VERSION ""

NS_ :

BS_:

BU_: BMU_ID_0 BMU_ID_1 BMU_ID_2 BMU_ID_3 BMU_ID_4 BMU_ID_5 BMU_ID_6 BMU_ID_7 BMU_ID_8 BMU_ID_9 BMU_ID_10 BMU_ID_11 BMU_ID_12 BMU_ID_13 BMU_ID_14 BMU_ID_15

BO_ 1280 wBMU_ID_0_Reserved: 8 BMU_ID_0
 SG_ RESERVED : 0|64@1+ (1,0) [0|0] ""  BMU_ID_0

BO_ 1281 wBMU_ID_1_Reserved: 8 BMU_ID_0
 SG_ RESERVED : 0|64@1+ (1,0) [0|0] ""  BMU_ID_1

BO_ 1282 wBMU_ID_2_Reserved: 8 BMU_ID_0
 SG_ RESERVED : 0|64@1+ (1,0) [0|0] ""  BMU_ID_2

BO_ 1283 wBMU_ID_3_Reserved: 8 BMU_ID_0
 SG_ RESERVED : 0|64@1+ (1,0) [0|0] ""  BMU_ID_3

BO_ 1284 wBMU_ID_4_Reserved: 8 BMU_ID_0
 SG_ RESERVED : 0|64@1+ (1,0) [0|0] ""  BMU_ID_4

BO_ 1285 wBMU_ID_5_Reserved: 8 BMU_ID_0
 SG_ RESERVED : 0|64@1+ (1,0) [0|0] ""  BMU_ID_5

BO_ 1286 wBMU_ID_6_Reserved: 8 BMU_ID_0
 SG_ RESERVED : 0|64@1+ (1,0) [0|0] ""  BMU_ID_6

BO_ 1287 wBMU_ID_7_Reserved: 8 BMU_ID_0
 SG_ RESERVED : 0|64@1+ (1,0) [0|0] ""  BMU_ID_7

BO_ 1288 wBMU_ID_8_Reserved: 8 BMU_ID_0
 SG_ RESERVED : 0|64@1+ (1,0) [0|0] ""  BMU_ID_8

BO_ 1289 wBMU_ID_9_Reserved: 8 BMU_ID_0
 SG_ RESERVED : 0|64@1+ (1,0) [0|0] ""  BMU_ID_9

BO_ 1290 wBMU_ID_10_Reserved: 8 BMU_ID_0
 SG_ RESERVED : 0|64@1+ (1,0) [0|0] ""  BMU_ID_10

BO_ 1291 wBMU_ID_11_Reserved: 8 BMU_ID_0
 SG_ RESERVED : 0|64@1+ (1,0) [0|0] ""  BMU_ID_11

BO_ 1292 wBMU_ID_12_Reserved: 8 BMU_ID_0
 SG_ RESERVED : 0|64@1+ (1,0) [0|0] ""  BMU_ID_12

BO_ 1293 wBMU_ID_13_Reserved: 8 BMU_ID_0
 SG_ RESERVED : 0|64@1+ (1,0) [0|0] ""  BMU_ID_13

BO_ 1294 wBMU_ID_14_Reserved: 8 BMU_ID_0
 SG_ RESERVED : 0|64@1+ (1,0) [0|0] ""  BMU_ID_14

BO_ 1295 wBMU_ID_15_Reserved: 8 BMU_ID_0
 SG_ RESERVED : 0|64@1+ (1,0) [0|0] ""  BMU_ID_15

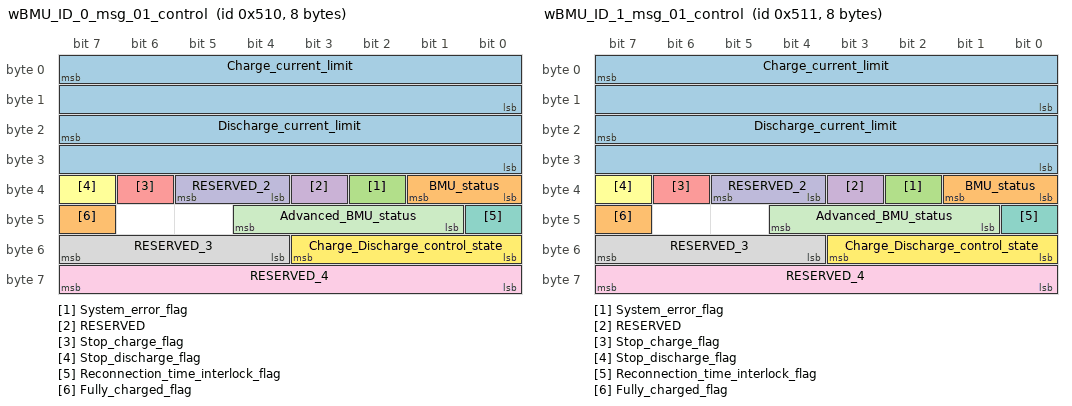
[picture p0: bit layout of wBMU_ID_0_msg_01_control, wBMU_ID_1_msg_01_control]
BO_ 1296 wBMU_ID_0_msg_01_control: 8 BMU_ID_0
 SG_ Discharge_current_limit : 23|16@0+ (0.1,0) [0|0] "A"  BMU_ID_0
 SG_ BMU_status : 33|2@0+ (1,0) [0|0] ""  BMU_ID_0
 SG_ System_error_flag : 34|1@0+ (1,0) [0|0] ""  BMU_ID_0
 SG_ RESERVED : 35|1@0+ (1,0) [0|0] ""  BMU_ID_0
 SG_ Stop_charge_flag : 38|1@0+ (1,0) [0|0] ""  BMU_ID_0
 SG_ Stop_discharge_flag : 39|1@0+ (1,0) [0|0] ""  BMU_ID_0
 SG_ Reconnection_time_interlock_flag : 40|1@0+ (1,0) [0|0] ""  BMU_ID_0
 SG_ RESERVED_3 : 55|4@0+ (1,0) [0|0] ""  BMU_ID_0
 SG_ RESERVED_4 : 63|8@0+ (1,0) [0|0] ""  BMU_ID_0
 SG_ RESERVED_2 : 37|2@0+ (1,0) [0|0] ""  BMU_ID_0
 SG_ Advanced_BMU_status : 44|4@0+ (1,0) [0|0] ""  BMU_ID_0
 SG_ Charge_Discharge_control_state : 51|4@0+ (1,0) [0|0] ""  BMU_ID_0
 SG_ Charge_current_limit : 7|16@0+ (0.1,0) [0|0] "A"  BMU_ID_0
 SG_ Fully_charged_flag : 47|1@0+ (1,0) [0|0] "" Vector__XXX

BO_ 1297 wBMU_ID_1_msg_01_control: 8 BMU_ID_1
 SG_ Discharge_current_limit : 23|16@0+ (0.1,0) [0|0] "A"  BMU_ID_0
 SG_ BMU_status : 33|2@0+ (1,0) [0|0] ""  BMU_ID_0
 SG_ System_error_flag : 34|1@0+ (1,0) [0|0] ""  BMU_ID_0
 SG_ RESERVED : 35|1@0+ (1,0) [0|0] ""  BMU_ID_0
 SG_ Stop_charge_flag : 38|1@0+ (1,0) [0|0] ""  BMU_ID_0
 SG_ Stop_discharge_flag : 39|1@0+ (1,0) [0|0] ""  BMU_ID_0
 SG_ Reconnection_time_interlock_flag : 40|1@0+ (1,0) [0|0] ""  BMU_ID_0
 SG_ RESERVED_3 : 55|4@0+ (1,0) [0|0] ""  BMU_ID_0
 SG_ RESERVED_4 : 63|8@0+ (1,0) [0|0] ""  BMU_ID_0
 SG_ RESERVED_2 : 37|2@0+ (1,0) [0|0] ""  BMU_ID_0
 SG_ Advanced_BMU_status : 44|4@0+ (1,0) [0|0] ""  BMU_ID_0
 SG_ Charge_Discharge_control_state : 51|4@0+ (1,0) [0|0] ""  BMU_ID_0
 SG_ Charge_current_limit : 7|16@0+ (0.1,0) [0|0] "A"  BMU_ID_0
 SG_ Fully_charged_flag : 47|1@0+ (1,0) [0|0] "" Vector__XXX

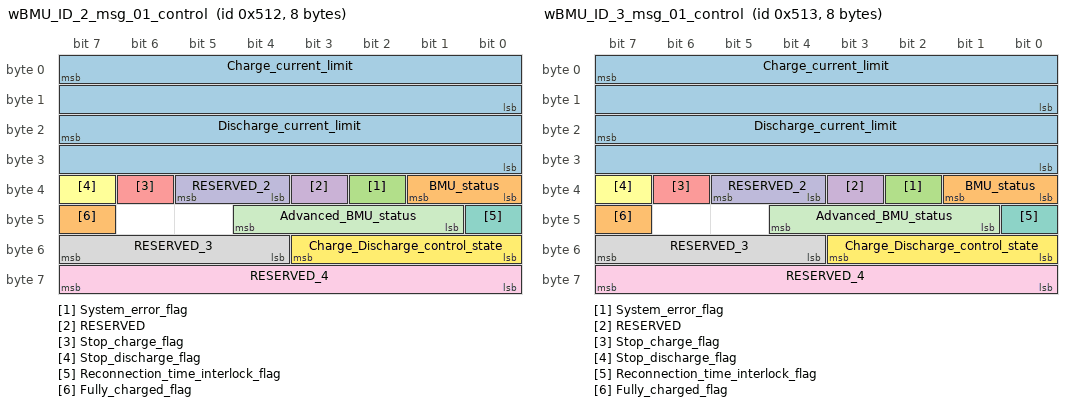
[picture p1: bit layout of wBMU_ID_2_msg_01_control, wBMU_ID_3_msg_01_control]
BO_ 1298 wBMU_ID_2_msg_01_control: 8 BMU_ID_2
 SG_ Discharge_current_limit : 23|16@0+ (0.1,0) [0|0] "A"  BMU_ID_0
 SG_ BMU_status : 33|2@0+ (1,0) [0|0] ""  BMU_ID_0
 SG_ System_error_flag : 34|1@0+ (1,0) [0|0] ""  BMU_ID_0
 SG_ RESERVED : 35|1@0+ (1,0) [0|0] ""  BMU_ID_0
 SG_ Stop_charge_flag : 38|1@0+ (1,0) [0|0] ""  BMU_ID_0
 SG_ Stop_discharge_flag : 39|1@0+ (1,0) [0|0] ""  BMU_ID_0
 SG_ Reconnection_time_interlock_flag : 40|1@0+ (1,0) [0|0] ""  BMU_ID_0
 SG_ RESERVED_3 : 55|4@0+ (1,0) [0|0] ""  BMU_ID_0
 SG_ RESERVED_4 : 63|8@0+ (1,0) [0|0] ""  BMU_ID_0
 SG_ RESERVED_2 : 37|2@0+ (1,0) [0|0] ""  BMU_ID_0
 SG_ Advanced_BMU_status : 44|4@0+ (1,0) [0|0] ""  BMU_ID_0
 SG_ Charge_Discharge_control_state : 51|4@0+ (1,0) [0|0] ""  BMU_ID_0
 SG_ Charge_current_limit : 7|16@0+ (0.1,0) [0|0] "A"  BMU_ID_0
 SG_ Fully_charged_flag : 47|1@0+ (1,0) [0|0] "" Vector__XXX

BO_ 1299 wBMU_ID_3_msg_01_control: 8 BMU_ID_3
 SG_ Discharge_current_limit : 23|16@0+ (0.1,0) [0|0] "A"  BMU_ID_0
 SG_ BMU_status : 33|2@0+ (1,0) [0|0] ""  BMU_ID_0
 SG_ System_error_flag : 34|1@0+ (1,0) [0|0] ""  BMU_ID_0
 SG_ RESERVED : 35|1@0+ (1,0) [0|0] ""  BMU_ID_0
 SG_ Stop_charge_flag : 38|1@0+ (1,0) [0|0] ""  BMU_ID_0
 SG_ Stop_discharge_flag : 39|1@0+ (1,0) [0|0] ""  BMU_ID_0
 SG_ Reconnection_time_interlock_flag : 40|1@0+ (1,0) [0|0] ""  BMU_ID_0
 SG_ RESERVED_3 : 55|4@0+ (1,0) [0|0] ""  BMU_ID_0
 SG_ RESERVED_4 : 63|8@0+ (1,0) [0|0] ""  BMU_ID_0
 SG_ RESERVED_2 : 37|2@0+ (1,0) [0|0] ""  BMU_ID_0
 SG_ Advanced_BMU_status : 44|4@0+ (1,0) [0|0] ""  BMU_ID_0
 SG_ Charge_Discharge_control_state : 51|4@0+ (1,0) [0|0] ""  BMU_ID_0
 SG_ Charge_current_limit : 7|16@0+ (0.1,0) [0|0] "A"  BMU_ID_0
 SG_ Fully_charged_flag : 47|1@0+ (1,0) [0|0] "" Vector__XXX

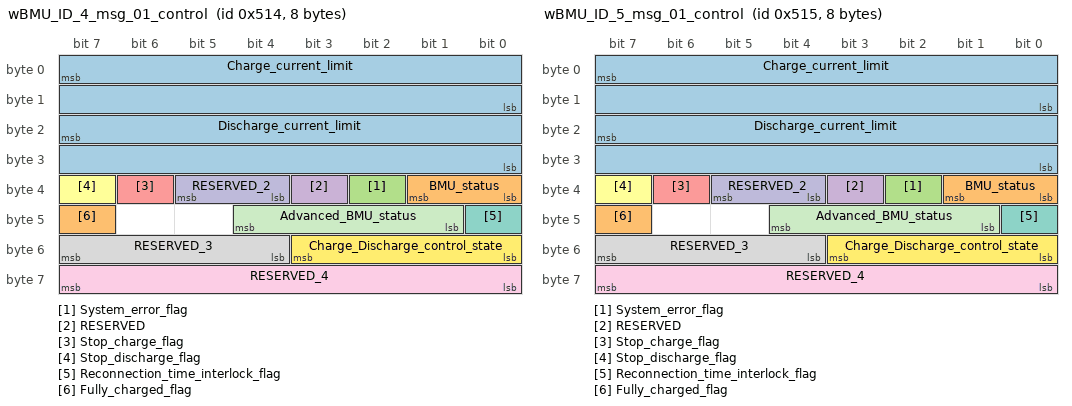
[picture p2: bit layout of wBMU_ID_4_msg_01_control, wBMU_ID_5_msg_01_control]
BO_ 1300 wBMU_ID_4_msg_01_control: 8 BMU_ID_4
 SG_ Discharge_current_limit : 23|16@0+ (0.1,0) [0|0] "A"  BMU_ID_0
 SG_ BMU_status : 33|2@0+ (1,0) [0|0] ""  BMU_ID_0
 SG_ System_error_flag : 34|1@0+ (1,0) [0|0] ""  BMU_ID_0
 SG_ RESERVED : 35|1@0+ (1,0) [0|0] ""  BMU_ID_0
 SG_ Stop_charge_flag : 38|1@0+ (1,0) [0|0] ""  BMU_ID_0
 SG_ Stop_discharge_flag : 39|1@0+ (1,0) [0|0] ""  BMU_ID_0
 SG_ Reconnection_time_interlock_flag : 40|1@0+ (1,0) [0|0] ""  BMU_ID_0
 SG_ RESERVED_3 : 55|4@0+ (1,0) [0|0] ""  BMU_ID_0
 SG_ RESERVED_4 : 63|8@0+ (1,0) [0|0] ""  BMU_ID_0
 SG_ RESERVED_2 : 37|2@0+ (1,0) [0|0] ""  BMU_ID_0
 SG_ Advanced_BMU_status : 44|4@0+ (1,0) [0|0] ""  BMU_ID_0
 SG_ Charge_Discharge_control_state : 51|4@0+ (1,0) [0|0] ""  BMU_ID_0
 SG_ Charge_current_limit : 7|16@0+ (0.1,0) [0|0] "A"  BMU_ID_0
 SG_ Fully_charged_flag : 47|1@0+ (1,0) [0|0] "" Vector__XXX

BO_ 1301 wBMU_ID_5_msg_01_control: 8 BMU_ID_5
 SG_ Discharge_current_limit : 23|16@0+ (0.1,0) [0|0] "A"  BMU_ID_0
 SG_ BMU_status : 33|2@0+ (1,0) [0|0] ""  BMU_ID_0
 SG_ System_error_flag : 34|1@0+ (1,0) [0|0] ""  BMU_ID_0
 SG_ RESERVED : 35|1@0+ (1,0) [0|0] ""  BMU_ID_0
 SG_ Stop_charge_flag : 38|1@0+ (1,0) [0|0] ""  BMU_ID_0
 SG_ Stop_discharge_flag : 39|1@0+ (1,0) [0|0] ""  BMU_ID_0
 SG_ Reconnection_time_interlock_flag : 40|1@0+ (1,0) [0|0] ""  BMU_ID_0
 SG_ RESERVED_3 : 55|4@0+ (1,0) [0|0] ""  BMU_ID_0
 SG_ RESERVED_4 : 63|8@0+ (1,0) [0|0] ""  BMU_ID_0
 SG_ RESERVED_2 : 37|2@0+ (1,0) [0|0] ""  BMU_ID_0
 SG_ Advanced_BMU_status : 44|4@0+ (1,0) [0|0] ""  BMU_ID_0
 SG_ Charge_Discharge_control_state : 51|4@0+ (1,0) [0|0] ""  BMU_ID_0
 SG_ Charge_current_limit : 7|16@0+ (0.1,0) [0|0] "A"  BMU_ID_0
 SG_ Fully_charged_flag : 47|1@0+ (1,0) [0|0] "" Vector__XXX

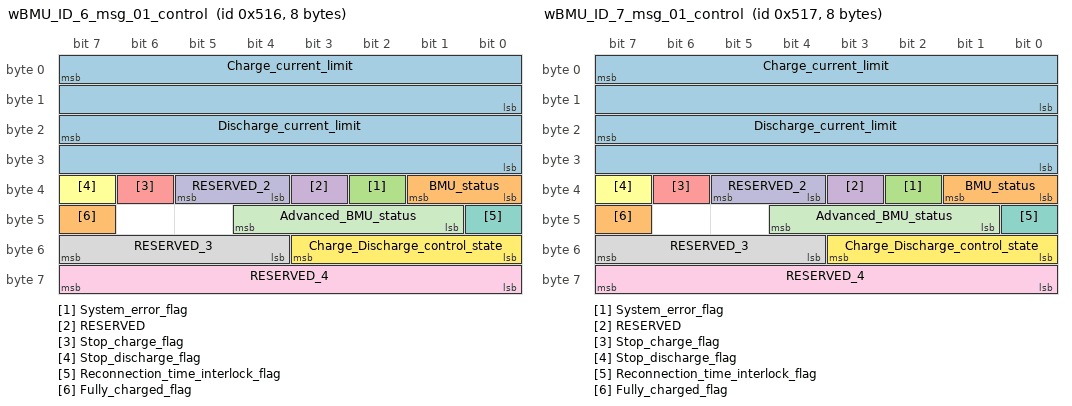
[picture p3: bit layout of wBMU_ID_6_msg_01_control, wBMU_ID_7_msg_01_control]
BO_ 1302 wBMU_ID_6_msg_01_control: 8 BMU_ID_6
 SG_ Discharge_current_limit : 23|16@0+ (0.1,0) [0|0] "A"  BMU_ID_0
 SG_ BMU_status : 33|2@0+ (1,0) [0|0] ""  BMU_ID_0
 SG_ System_error_flag : 34|1@0+ (1,0) [0|0] ""  BMU_ID_0
 SG_ RESERVED : 35|1@0+ (1,0) [0|0] ""  BMU_ID_0
 SG_ Stop_charge_flag : 38|1@0+ (1,0) [0|0] ""  BMU_ID_0
 SG_ Stop_discharge_flag : 39|1@0+ (1,0) [0|0] ""  BMU_ID_0
 SG_ Reconnection_time_interlock_flag : 40|1@0+ (1,0) [0|0] ""  BMU_ID_0
 SG_ RESERVED_3 : 55|4@0+ (1,0) [0|0] ""  BMU_ID_0
 SG_ RESERVED_4 : 63|8@0+ (1,0) [0|0] ""  BMU_ID_0
 SG_ RESERVED_2 : 37|2@0+ (1,0) [0|0] ""  BMU_ID_0
 SG_ Advanced_BMU_status : 44|4@0+ (1,0) [0|0] ""  BMU_ID_0
 SG_ Charge_Discharge_control_state : 51|4@0+ (1,0) [0|0] ""  BMU_ID_0
 SG_ Charge_current_limit : 7|16@0+ (0.1,0) [0|0] "A"  BMU_ID_0
 SG_ Fully_charged_flag : 47|1@0+ (1,0) [0|0] "" Vector__XXX

BO_ 1303 wBMU_ID_7_msg_01_control: 8 BMU_ID_7
 SG_ Discharge_current_limit : 23|16@0+ (0.1,0) [0|0] "A"  BMU_ID_0
 SG_ BMU_status : 33|2@0+ (1,0) [0|0] ""  BMU_ID_0
 SG_ System_error_flag : 34|1@0+ (1,0) [0|0] ""  BMU_ID_0
 SG_ RESERVED : 35|1@0+ (1,0) [0|0] ""  BMU_ID_0
 SG_ Stop_charge_flag : 38|1@0+ (1,0) [0|0] ""  BMU_ID_0
 SG_ Stop_discharge_flag : 39|1@0+ (1,0) [0|0] ""  BMU_ID_0
 SG_ Reconnection_time_interlock_flag : 40|1@0+ (1,0) [0|0] ""  BMU_ID_0
 SG_ RESERVED_3 : 55|4@0+ (1,0) [0|0] ""  BMU_ID_0
 SG_ RESERVED_4 : 63|8@0+ (1,0) [0|0] ""  BMU_ID_0
 SG_ RESERVED_2 : 37|2@0+ (1,0) [0|0] ""  BMU_ID_0
 SG_ Advanced_BMU_status : 44|4@0+ (1,0) [0|0] ""  BMU_ID_0
 SG_ Charge_Discharge_control_state : 51|4@0+ (1,0) [0|0] ""  BMU_ID_0
 SG_ Charge_current_limit : 7|16@0+ (0.1,0) [0|0] "A"  BMU_ID_0
 SG_ Fully_charged_flag : 47|1@0+ (1,0) [0|0] "" Vector__XXX

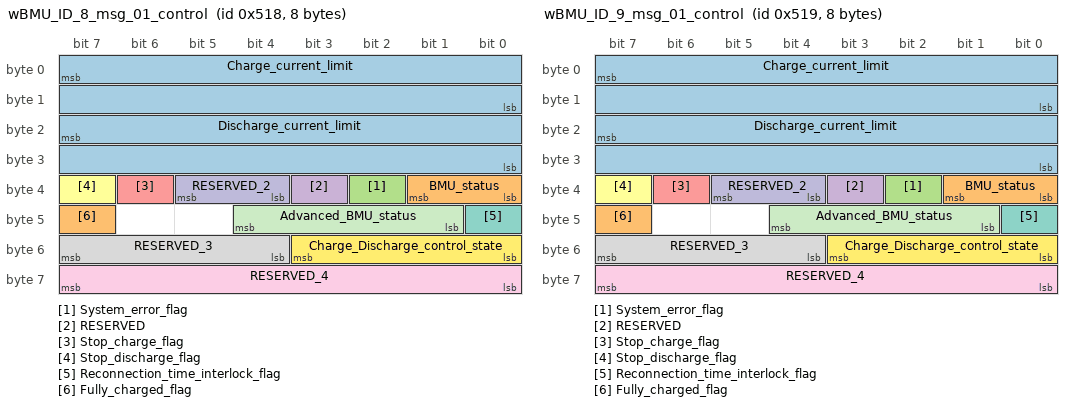
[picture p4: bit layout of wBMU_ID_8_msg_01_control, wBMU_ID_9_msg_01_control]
BO_ 1304 wBMU_ID_8_msg_01_control: 8 BMU_ID_8
 SG_ Discharge_current_limit : 23|16@0+ (0.1,0) [0|0] "A"  BMU_ID_0
 SG_ BMU_status : 33|2@0+ (1,0) [0|0] ""  BMU_ID_0
 SG_ System_error_flag : 34|1@0+ (1,0) [0|0] ""  BMU_ID_0
 SG_ RESERVED : 35|1@0+ (1,0) [0|0] ""  BMU_ID_0
 SG_ Stop_charge_flag : 38|1@0+ (1,0) [0|0] ""  BMU_ID_0
 SG_ Stop_discharge_flag : 39|1@0+ (1,0) [0|0] ""  BMU_ID_0
 SG_ Reconnection_time_interlock_flag : 40|1@0+ (1,0) [0|0] ""  BMU_ID_0
 SG_ RESERVED_3 : 55|4@0+ (1,0) [0|0] ""  BMU_ID_0
 SG_ RESERVED_4 : 63|8@0+ (1,0) [0|0] ""  BMU_ID_0
 SG_ RESERVED_2 : 37|2@0+ (1,0) [0|0] ""  BMU_ID_0
 SG_ Advanced_BMU_status : 44|4@0+ (1,0) [0|0] ""  BMU_ID_0
 SG_ Charge_Discharge_control_state : 51|4@0+ (1,0) [0|0] ""  BMU_ID_0
 SG_ Charge_current_limit : 7|16@0+ (0.1,0) [0|0] "A"  BMU_ID_0
 SG_ Fully_charged_flag : 47|1@0+ (1,0) [0|0] "" Vector__XXX

BO_ 1305 wBMU_ID_9_msg_01_control: 8 BMU_ID_9
 SG_ Discharge_current_limit : 23|16@0+ (0.1,0) [0|0] "A"  BMU_ID_0
 SG_ BMU_status : 33|2@0+ (1,0) [0|0] ""  BMU_ID_0
 SG_ System_error_flag : 34|1@0+ (1,0) [0|0] ""  BMU_ID_0
 SG_ RESERVED : 35|1@0+ (1,0) [0|0] ""  BMU_ID_0
 SG_ Stop_charge_flag : 38|1@0+ (1,0) [0|0] ""  BMU_ID_0
 SG_ Stop_discharge_flag : 39|1@0+ (1,0) [0|0] ""  BMU_ID_0
 SG_ Reconnection_time_interlock_flag : 40|1@0+ (1,0) [0|0] ""  BMU_ID_0
 SG_ RESERVED_3 : 55|4@0+ (1,0) [0|0] ""  BMU_ID_0
 SG_ RESERVED_4 : 63|8@0+ (1,0) [0|0] ""  BMU_ID_0
 SG_ RESERVED_2 : 37|2@0+ (1,0) [0|0] ""  BMU_ID_0
 SG_ Advanced_BMU_status : 44|4@0+ (1,0) [0|0] ""  BMU_ID_0
 SG_ Charge_Discharge_control_state : 51|4@0+ (1,0) [0|0] ""  BMU_ID_0
 SG_ Charge_current_limit : 7|16@0+ (0.1,0) [0|0] "A"  BMU_ID_0
 SG_ Fully_charged_flag : 47|1@0+ (1,0) [0|0] "" Vector__XXX

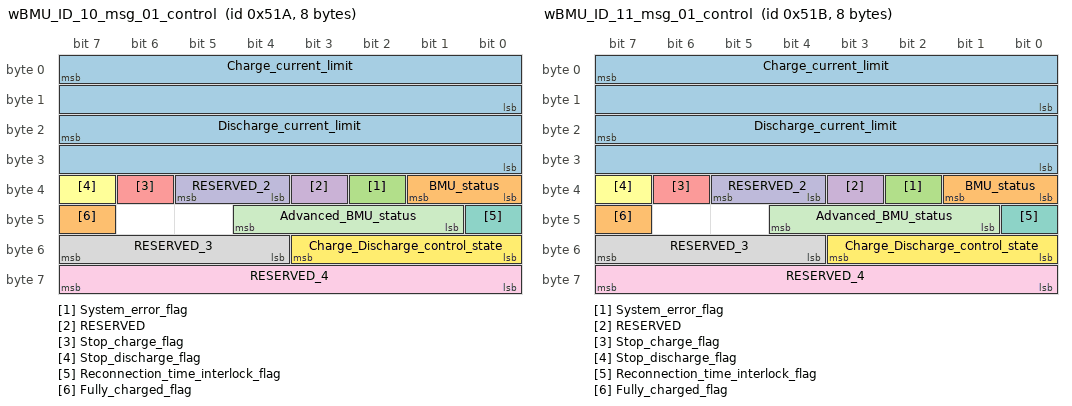
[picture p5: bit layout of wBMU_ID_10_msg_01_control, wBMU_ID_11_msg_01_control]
BO_ 1306 wBMU_ID_10_msg_01_control: 8 BMU_ID_10
 SG_ Discharge_current_limit : 23|16@0+ (0.1,0) [0|0] "A"  BMU_ID_0
 SG_ BMU_status : 33|2@0+ (1,0) [0|0] ""  BMU_ID_0
 SG_ System_error_flag : 34|1@0+ (1,0) [0|0] ""  BMU_ID_0
 SG_ RESERVED : 35|1@0+ (1,0) [0|0] ""  BMU_ID_0
 SG_ Stop_charge_flag : 38|1@0+ (1,0) [0|0] ""  BMU_ID_0
 SG_ Stop_discharge_flag : 39|1@0+ (1,0) [0|0] ""  BMU_ID_0
 SG_ Reconnection_time_interlock_flag : 40|1@0+ (1,0) [0|0] ""  BMU_ID_0
 SG_ RESERVED_3 : 55|4@0+ (1,0) [0|0] ""  BMU_ID_0
 SG_ RESERVED_4 : 63|8@0+ (1,0) [0|0] ""  BMU_ID_0
 SG_ RESERVED_2 : 37|2@0+ (1,0) [0|0] ""  BMU_ID_0
 SG_ Advanced_BMU_status : 44|4@0+ (1,0) [0|0] ""  BMU_ID_0
 SG_ Charge_Discharge_control_state : 51|4@0+ (1,0) [0|0] ""  BMU_ID_0
 SG_ Charge_current_limit : 7|16@0+ (0.1,0) [0|0] "A"  BMU_ID_0
 SG_ Fully_charged_flag : 47|1@0+ (1,0) [0|0] "" Vector__XXX

BO_ 1307 wBMU_ID_11_msg_01_control: 8 BMU_ID_11
 SG_ Discharge_current_limit : 23|16@0+ (0.1,0) [0|0] "A"  BMU_ID_0
 SG_ BMU_status : 33|2@0+ (1,0) [0|0] ""  BMU_ID_0
 SG_ System_error_flag : 34|1@0+ (1,0) [0|0] ""  BMU_ID_0
 SG_ RESERVED : 35|1@0+ (1,0) [0|0] ""  BMU_ID_0
 SG_ Stop_charge_flag : 38|1@0+ (1,0) [0|0] ""  BMU_ID_0
 SG_ Stop_discharge_flag : 39|1@0+ (1,0) [0|0] ""  BMU_ID_0
 SG_ Reconnection_time_interlock_flag : 40|1@0+ (1,0) [0|0] ""  BMU_ID_0
 SG_ RESERVED_3 : 55|4@0+ (1,0) [0|0] ""  BMU_ID_0
 SG_ RESERVED_4 : 63|8@0+ (1,0) [0|0] ""  BMU_ID_0
 SG_ RESERVED_2 : 37|2@0+ (1,0) [0|0] ""  BMU_ID_0
 SG_ Advanced_BMU_status : 44|4@0+ (1,0) [0|0] ""  BMU_ID_0
 SG_ Charge_Discharge_control_state : 51|4@0+ (1,0) [0|0] ""  BMU_ID_0
 SG_ Charge_current_limit : 7|16@0+ (0.1,0) [0|0] "A"  BMU_ID_0
 SG_ Fully_charged_flag : 47|1@0+ (1,0) [0|0] "" Vector__XXX

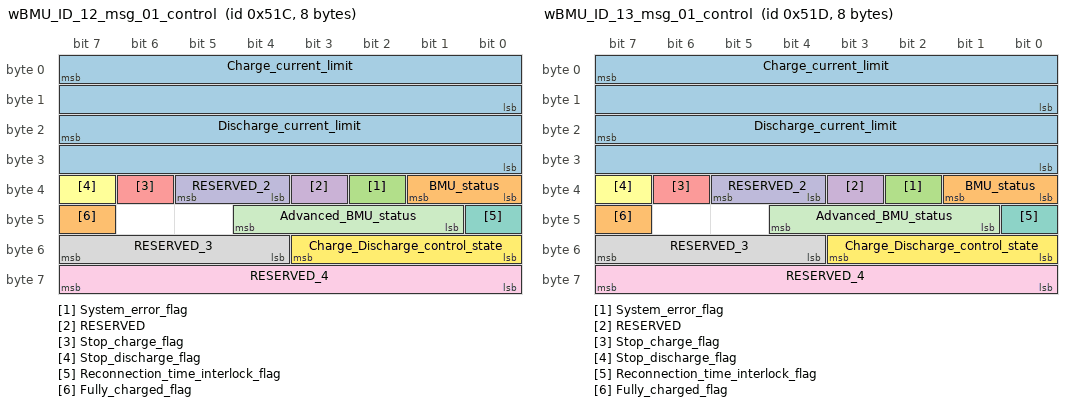
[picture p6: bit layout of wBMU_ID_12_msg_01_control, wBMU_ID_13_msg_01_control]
BO_ 1308 wBMU_ID_12_msg_01_control: 8 BMU_ID_12
 SG_ Discharge_current_limit : 23|16@0+ (0.1,0) [0|0] "A"  BMU_ID_0
 SG_ BMU_status : 33|2@0+ (1,0) [0|0] ""  BMU_ID_0
 SG_ System_error_flag : 34|1@0+ (1,0) [0|0] ""  BMU_ID_0
 SG_ RESERVED : 35|1@0+ (1,0) [0|0] ""  BMU_ID_0
 SG_ Stop_charge_flag : 38|1@0+ (1,0) [0|0] ""  BMU_ID_0
 SG_ Stop_discharge_flag : 39|1@0+ (1,0) [0|0] ""  BMU_ID_0
 SG_ Reconnection_time_interlock_flag : 40|1@0+ (1,0) [0|0] ""  BMU_ID_0
 SG_ RESERVED_3 : 55|4@0+ (1,0) [0|0] ""  BMU_ID_0
 SG_ RESERVED_4 : 63|8@0+ (1,0) [0|0] ""  BMU_ID_0
 SG_ RESERVED_2 : 37|2@0+ (1,0) [0|0] ""  BMU_ID_0
 SG_ Advanced_BMU_status : 44|4@0+ (1,0) [0|0] ""  BMU_ID_0
 SG_ Charge_Discharge_control_state : 51|4@0+ (1,0) [0|0] ""  BMU_ID_0
 SG_ Charge_current_limit : 7|16@0+ (0.1,0) [0|0] "A"  BMU_ID_0
 SG_ Fully_charged_flag : 47|1@0+ (1,0) [0|0] "" Vector__XXX

BO_ 1309 wBMU_ID_13_msg_01_control: 8 BMU_ID_13
 SG_ Discharge_current_limit : 23|16@0+ (0.1,0) [0|0] "A"  BMU_ID_0
 SG_ BMU_status : 33|2@0+ (1,0) [0|0] ""  BMU_ID_0
 SG_ System_error_flag : 34|1@0+ (1,0) [0|0] ""  BMU_ID_0
 SG_ RESERVED : 35|1@0+ (1,0) [0|0] ""  BMU_ID_0
 SG_ Stop_charge_flag : 38|1@0+ (1,0) [0|0] ""  BMU_ID_0
 SG_ Stop_discharge_flag : 39|1@0+ (1,0) [0|0] ""  BMU_ID_0
 SG_ Reconnection_time_interlock_flag : 40|1@0+ (1,0) [0|0] ""  BMU_ID_0
 SG_ RESERVED_3 : 55|4@0+ (1,0) [0|0] ""  BMU_ID_0
 SG_ RESERVED_4 : 63|8@0+ (1,0) [0|0] ""  BMU_ID_0
 SG_ RESERVED_2 : 37|2@0+ (1,0) [0|0] ""  BMU_ID_0
 SG_ Advanced_BMU_status : 44|4@0+ (1,0) [0|0] ""  BMU_ID_0
 SG_ Charge_Discharge_control_state : 51|4@0+ (1,0) [0|0] ""  BMU_ID_0
 SG_ Charge_current_limit : 7|16@0+ (0.1,0) [0|0] "A"  BMU_ID_0
 SG_ Fully_charged_flag : 47|1@0+ (1,0) [0|0] "" Vector__XXX

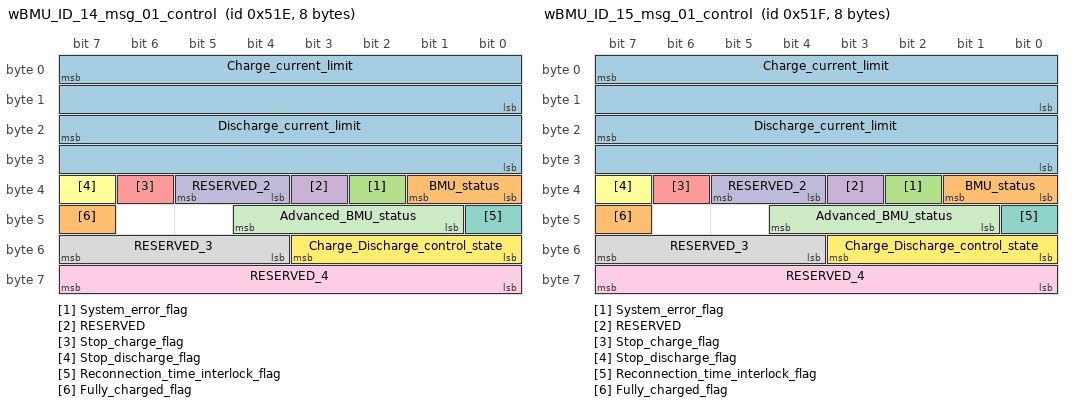
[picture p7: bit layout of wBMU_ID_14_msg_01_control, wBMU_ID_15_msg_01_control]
BO_ 1310 wBMU_ID_14_msg_01_control: 8 BMU_ID_14
 SG_ Discharge_current_limit : 23|16@0+ (0.1,0) [0|0] "A"  BMU_ID_0
 SG_ BMU_status : 33|2@0+ (1,0) [0|0] ""  BMU_ID_0
 SG_ System_error_flag : 34|1@0+ (1,0) [0|0] ""  BMU_ID_0
 SG_ RESERVED : 35|1@0+ (1,0) [0|0] ""  BMU_ID_0
 SG_ Stop_charge_flag : 38|1@0+ (1,0) [0|0] ""  BMU_ID_0
 SG_ Stop_discharge_flag : 39|1@0+ (1,0) [0|0] ""  BMU_ID_0
 SG_ Reconnection_time_interlock_flag : 40|1@0+ (1,0) [0|0] ""  BMU_ID_0
 SG_ RESERVED_3 : 55|4@0+ (1,0) [0|0] ""  BMU_ID_0
 SG_ RESERVED_4 : 63|8@0+ (1,0) [0|0] ""  BMU_ID_0
 SG_ RESERVED_2 : 37|2@0+ (1,0) [0|0] ""  BMU_ID_0
 SG_ Advanced_BMU_status : 44|4@0+ (1,0) [0|0] ""  BMU_ID_0
 SG_ Charge_Discharge_control_state : 51|4@0+ (1,0) [0|0] ""  BMU_ID_0
 SG_ Charge_current_limit : 7|16@0+ (0.1,0) [0|0] "A"  BMU_ID_0
 SG_ Fully_charged_flag : 47|1@0+ (1,0) [0|0] "" Vector__XXX

BO_ 1311 wBMU_ID_15_msg_01_control: 8 BMU_ID_15
 SG_ Discharge_current_limit : 23|16@0+ (0.1,0) [0|0] "A"  BMU_ID_0
 SG_ BMU_status : 33|2@0+ (1,0) [0|0] ""  BMU_ID_0
 SG_ System_error_flag : 34|1@0+ (1,0) [0|0] ""  BMU_ID_0
 SG_ RESERVED : 35|1@0+ (1,0) [0|0] ""  BMU_ID_0
 SG_ Stop_charge_flag : 38|1@0+ (1,0) [0|0] ""  BMU_ID_0
 SG_ Stop_discharge_flag : 39|1@0+ (1,0) [0|0] ""  BMU_ID_0
 SG_ Reconnection_time_interlock_flag : 40|1@0+ (1,0) [0|0] ""  BMU_ID_0
 SG_ RESERVED_3 : 55|4@0+ (1,0) [0|0] ""  BMU_ID_0
 SG_ RESERVED_4 : 63|8@0+ (1,0) [0|0] ""  BMU_ID_0
 SG_ RESERVED_2 : 37|2@0+ (1,0) [0|0] ""  BMU_ID_0
 SG_ Advanced_BMU_status : 44|4@0+ (1,0) [0|0] ""  BMU_ID_0
 SG_ Charge_Discharge_control_state : 51|4@0+ (1,0) [0|0] ""  BMU_ID_0
 SG_ Charge_current_limit : 7|16@0+ (0.1,0) [0|0] "A"  BMU_ID_0
 SG_ Fully_charged_flag : 47|1@0+ (1,0) [0|0] "" Vector__XXX

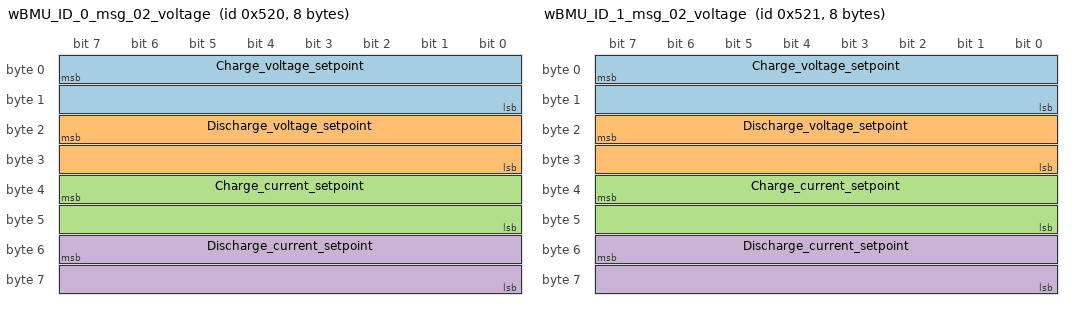
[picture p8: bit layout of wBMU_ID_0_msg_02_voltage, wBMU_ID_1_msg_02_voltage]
BO_ 1312 wBMU_ID_0_msg_02_voltage: 8 BMU_ID_0
 SG_ Charge_voltage_setpoint : 7|16@0+ (0.1,0) [0|0] "V"  BMU_ID_0
 SG_ Discharge_voltage_setpoint : 23|16@0+ (0.1,0) [0|0] "V"  BMU_ID_0
 SG_ Charge_current_setpoint : 39|16@0+ (0.1,0) [0|0] "A"  BMU_ID_0
 SG_ Discharge_current_setpoint : 55|16@0+ (0.1,0) [0|0] "A"  BMU_ID_0

BO_ 1313 wBMU_ID_1_msg_02_voltage: 8 BMU_ID_1
 SG_ Charge_voltage_setpoint : 7|16@0+ (0.1,0) [0|0] "V"  BMU_ID_0
 SG_ Discharge_voltage_setpoint : 23|16@0+ (0.1,0) [0|0] "V"  BMU_ID_0
 SG_ Charge_current_setpoint : 39|16@0+ (0.1,0) [0|0] "A"  BMU_ID_0
 SG_ Discharge_current_setpoint : 55|16@0+ (0.1,0) [0|0] "A"  BMU_ID_0

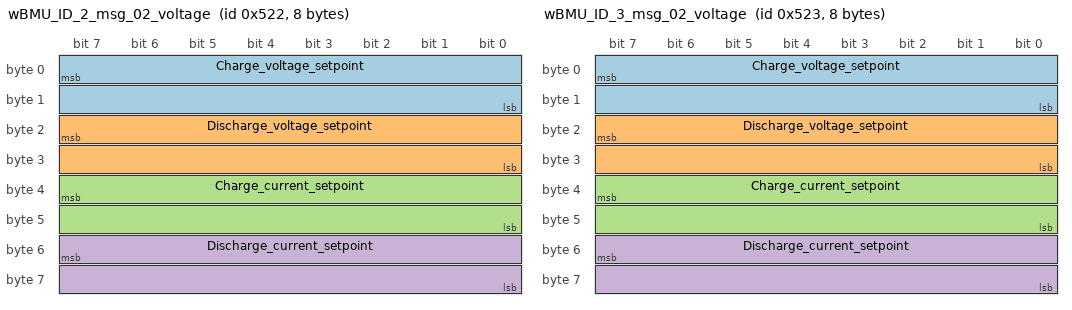
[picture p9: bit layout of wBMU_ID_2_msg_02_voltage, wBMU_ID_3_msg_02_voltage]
BO_ 1314 wBMU_ID_2_msg_02_voltage: 8 BMU_ID_2
 SG_ Charge_voltage_setpoint : 7|16@0+ (0.1,0) [0|0] "V"  BMU_ID_0
 SG_ Discharge_voltage_setpoint : 23|16@0+ (0.1,0) [0|0] "V"  BMU_ID_0
 SG_ Charge_current_setpoint : 39|16@0+ (0.1,0) [0|0] "A"  BMU_ID_0
 SG_ Discharge_current_setpoint : 55|16@0+ (0.1,0) [0|0] "A"  BMU_ID_0

BO_ 1315 wBMU_ID_3_msg_02_voltage: 8 BMU_ID_3
 SG_ Charge_voltage_setpoint : 7|16@0+ (0.1,0) [0|0] "V"  BMU_ID_0
 SG_ Discharge_voltage_setpoint : 23|16@0+ (0.1,0) [0|0] "V"  BMU_ID_0
 SG_ Charge_current_setpoint : 39|16@0+ (0.1,0) [0|0] "A"  BMU_ID_0
 SG_ Discharge_current_setpoint : 55|16@0+ (0.1,0) [0|0] "A"  BMU_ID_0

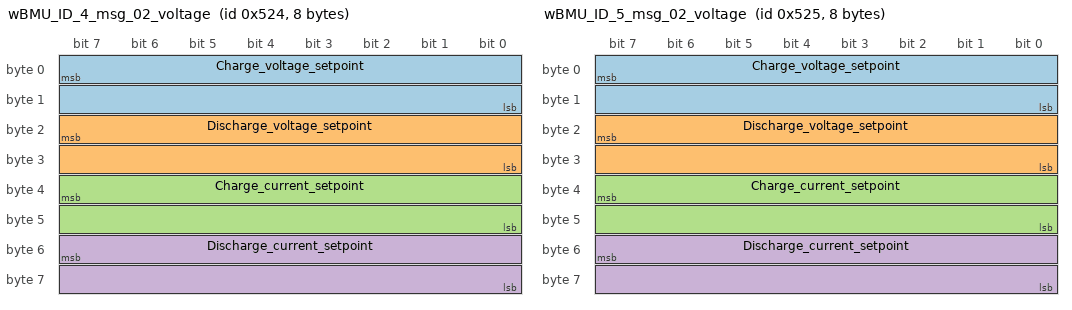
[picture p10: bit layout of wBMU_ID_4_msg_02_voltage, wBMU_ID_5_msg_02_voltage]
BO_ 1316 wBMU_ID_4_msg_02_voltage: 8 BMU_ID_4
 SG_ Charge_voltage_setpoint : 7|16@0+ (0.1,0) [0|0] "V"  BMU_ID_0
 SG_ Discharge_voltage_setpoint : 23|16@0+ (0.1,0) [0|0] "V"  BMU_ID_0
 SG_ Charge_current_setpoint : 39|16@0+ (0.1,0) [0|0] "A"  BMU_ID_0
 SG_ Discharge_current_setpoint : 55|16@0+ (0.1,0) [0|0] "A"  BMU_ID_0

BO_ 1317 wBMU_ID_5_msg_02_voltage: 8 BMU_ID_5
 SG_ Charge_voltage_setpoint : 7|16@0+ (0.1,0) [0|0] "V"  BMU_ID_0
 SG_ Discharge_voltage_setpoint : 23|16@0+ (0.1,0) [0|0] "V"  BMU_ID_0
 SG_ Charge_current_setpoint : 39|16@0+ (0.1,0) [0|0] "A"  BMU_ID_0
 SG_ Discharge_current_setpoint : 55|16@0+ (0.1,0) [0|0] "A"  BMU_ID_0

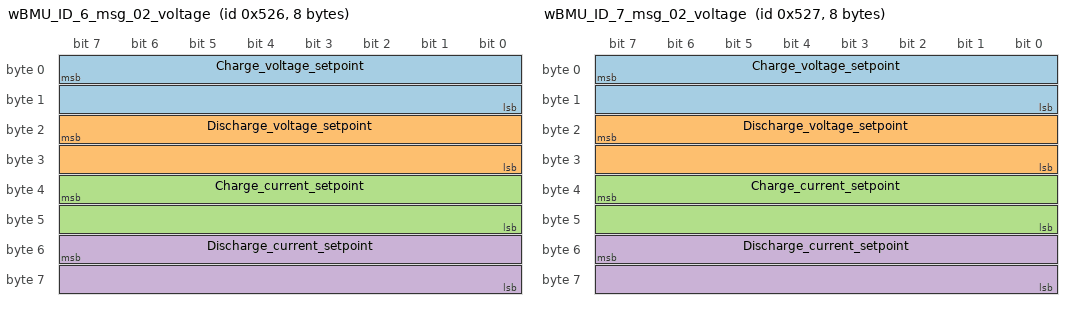
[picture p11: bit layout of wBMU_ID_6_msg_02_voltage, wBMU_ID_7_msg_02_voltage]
BO_ 1318 wBMU_ID_6_msg_02_voltage: 8 BMU_ID_6
 SG_ Charge_voltage_setpoint : 7|16@0+ (0.1,0) [0|0] "V"  BMU_ID_0
 SG_ Discharge_voltage_setpoint : 23|16@0+ (0.1,0) [0|0] "V"  BMU_ID_0
 SG_ Charge_current_setpoint : 39|16@0+ (0.1,0) [0|0] "A"  BMU_ID_0
 SG_ Discharge_current_setpoint : 55|16@0+ (0.1,0) [0|0] "A"  BMU_ID_0

BO_ 1319 wBMU_ID_7_msg_02_voltage: 8 BMU_ID_7
 SG_ Charge_voltage_setpoint : 7|16@0+ (0.1,0) [0|0] "V"  BMU_ID_0
 SG_ Discharge_voltage_setpoint : 23|16@0+ (0.1,0) [0|0] "V"  BMU_ID_0
 SG_ Charge_current_setpoint : 39|16@0+ (0.1,0) [0|0] "A"  BMU_ID_0
 SG_ Discharge_current_setpoint : 55|16@0+ (0.1,0) [0|0] "A"  BMU_ID_0

BO_ 1320 wBMU_ID_8_msg_02_voltage: 8 BMU_ID_8
 SG_ Charge_voltage_setpoint : 7|16@0+ (0.1,0) [0|0] "V"  BMU_ID_0
 SG_ Discharge_voltage_setpoint : 23|16@0+ (0.1,0) [0|0] "V"  BMU_ID_0
 SG_ Charge_current_setpoint : 39|16@0+ (0.1,0) [0|0] "A"  BMU_ID_0
 SG_ Discharge_current_setpoint : 55|16@0+ (0.1,0) [0|0] "A"  BMU_ID_0

BO_ 1321 wBMU_ID_9_msg_02_voltage: 8 BMU_ID_9
 SG_ Charge_voltage_setpoint : 7|16@0+ (0.1,0) [0|0] "V"  BMU_ID_0
 SG_ Discharge_voltage_setpoint : 23|16@0+ (0.1,0) [0|0] "V"  BMU_ID_0
 SG_ Charge_current_setpoint : 39|16@0+ (0.1,0) [0|0] "A"  BMU_ID_0
 SG_ Discharge_current_setpoint : 55|16@0+ (0.1,0) [0|0] "A"  BMU_ID_0

BO_ 1322 wBMU_ID_10_msg_02_voltage: 8 BMU_ID_10
 SG_ Charge_voltage_setpoint : 7|16@0+ (0.1,0) [0|0] "V"  BMU_ID_0
 SG_ Discharge_voltage_setpoint : 23|16@0+ (0.1,0) [0|0] "V"  BMU_ID_0
 SG_ Charge_current_setpoint : 39|16@0+ (0.1,0) [0|0] "A"  BMU_ID_0
 SG_ Discharge_current_setpoint : 55|16@0+ (0.1,0) [0|0] "A"  BMU_ID_0

BO_ 1323 wBMU_ID_11_msg_02_voltage: 8 BMU_ID_11
 SG_ Charge_voltage_setpoint : 7|16@0+ (0.1,0) [0|0] "V"  BMU_ID_0
 SG_ Discharge_voltage_setpoint : 23|16@0+ (0.1,0) [0|0] "V"  BMU_ID_0
 SG_ Charge_current_setpoint : 39|16@0+ (0.1,0) [0|0] "A"  BMU_ID_0
 SG_ Discharge_current_setpoint : 55|16@0+ (0.1,0) [0|0] "A"  BMU_ID_0

BO_ 1324 wBMU_ID_12_msg_02_voltage: 8 BMU_ID_12
 SG_ Charge_voltage_setpoint : 7|16@0+ (0.1,0) [0|0] "V"  BMU_ID_0
 SG_ Discharge_voltage_setpoint : 23|16@0+ (0.1,0) [0|0] "V"  BMU_ID_0
 SG_ Charge_current_setpoint : 39|16@0+ (0.1,0) [0|0] "A"  BMU_ID_0
 SG_ Discharge_current_setpoint : 55|16@0+ (0.1,0) [0|0] "A"  BMU_ID_0

BO_ 1325 wBMU_ID_13_msg_02_voltage: 8 BMU_ID_13
 SG_ Charge_voltage_setpoint : 7|16@0+ (0.1,0) [0|0] "V"  BMU_ID_0
 SG_ Discharge_voltage_setpoint : 23|16@0+ (0.1,0) [0|0] "V"  BMU_ID_0
 SG_ Charge_current_setpoint : 39|16@0+ (0.1,0) [0|0] "A"  BMU_ID_0
 SG_ Discharge_current_setpoint : 55|16@0+ (0.1,0) [0|0] "A"  BMU_ID_0

BO_ 1326 wBMU_ID_14_msg_02_voltage: 8 BMU_ID_14
 SG_ Charge_voltage_setpoint : 7|16@0+ (0.1,0) [0|0] "V"  BMU_ID_0
 SG_ Discharge_voltage_setpoint : 23|16@0+ (0.1,0) [0|0] "V"  BMU_ID_0
 SG_ Charge_current_setpoint : 39|16@0+ (0.1,0) [0|0] "A"  BMU_ID_0
 SG_ Discharge_current_setpoint : 55|16@0+ (0.1,0) [0|0] "A"  BMU_ID_0

BO_ 1327 wBMU_ID_15_msg_02_voltage: 8 BMU_ID_15
 SG_ Charge_voltage_setpoint : 7|16@0+ (0.1,0) [0|0] "V"  BMU_ID_0
 SG_ Discharge_voltage_setpoint : 23|16@0+ (0.1,0) [0|0] "V"  BMU_ID_0
 SG_ Charge_current_setpoint : 39|16@0+ (0.1,0) [0|0] "A"  BMU_ID_0
 SG_ Discharge_current_setpoint : 55|16@0+ (0.1,0) [0|0] "A"  BMU_ID_0

BO_ 1328 wBMU_ID_0_msg_03_errors: 8 BMU_ID_0
 SG_ System_errors : 0|1@1+ (1,0) [0|0] ""  BMU_ID_0
 SG_ Architecture_configuration_error : 1|1@1+ (1,0) [0|0] ""  BMU_ID_0
 SG_ Parallelization_voltage_errors : 2|1@1+ (1,0) [0|0] ""  BMU_ID_0
 SG_ General_configuration_errors : 3|1@1+ (1,0) [0|0] ""  BMU_ID_0
 SG_ Parallelization_comm_lost_primar : 4|1@1+ (1,0) [0|0] ""  BMU_ID_0
 SG_ Cell_overvoltage : 5|1@1+ (1,0) [0|0] ""  BMU_ID_0
 SG_ Cell_undervoltage : 6|1@1+ (1,0) [0|0] ""  BMU_ID_0
 SG_ Comm_failure_with_CMU : 7|1@1+ (1,0) [0|0] ""  BMU_ID_0
 SG_ Internal_CMU_error : 8|1@1+ (1,0) [0|0] ""  BMU_ID_0
 SG_ Internal_CMU_temperature_error : 9|1@1+ (1,0) [0|0] ""  BMU_ID_0
 SG_ Internal_CMU_voltage_reference : 10|1@1+ (1,0) [0|0] ""  BMU_ID_0
 SG_ Cell_shortcircuit : 11|1@1+ (1,0) [0|0] ""  BMU_ID_0
 SG_ Battery_overcurrent : 12|1@1+ (1,0) [0|0] ""  BMU_ID_0
 SG_ Overload_ratio_exceeded : 13|1@1+ (1,0) [0|0] ""  BMU_ID_0
 SG_ Current_sensor_errors : 14|1@1+ (1,0) [0|0] ""  BMU_ID_0
 SG_ BMU_temperature_errors : 15|1@1+ (1,0) [0|0] ""  BMU_ID_0
 SG_ Cell_overtemperature : 16|1@1+ (1,0) [0|0] ""  BMU_ID_0
 SG_ Cell_undertemperature : 17|1@1+ (1,0) [0|0] ""  BMU_ID_0
 SG_ Balancing_overtemperature : 18|1@1+ (1,0) [0|0] ""  BMU_ID_0
 SG_ Balancing_undertemperature : 19|1@1+ (1,0) [0|0] ""  BMU_ID_0
 SG_ Max_op_cell_temp_delta : 20|1@1+ (1,0) [0|0] ""  BMU_ID_0
 SG_ Thermal_runaway : 21|1@1+ (1,0) [0|0] ""  BMU_ID_0
 SG_ OW_and_SC_detected_on_cell : 22|1@1+ (1,0) [0|0] ""  BMU_ID_0
 SG_ BMU_external_overtemperature : 23|1@1+ (1,0) [0|0] ""  BMU_ID_0
 SG_ Battery_undervoltage : 24|1@1+ (1,0) [0|0] ""  BMU_ID_0
 SG_ BMU_supply_voltage_error : 25|1@1+ (1,0) [0|0] ""  BMU_ID_0
 SG_ Battery_overvoltage : 26|1@1+ (1,0) [0|0] ""  BMU_ID_0
 SG_ Cells_unbalanced : 27|1@1+ (1,0) [0|0] ""  BMU_ID_0
 SG_ Advanced_relaxation_voltage_delt : 28|1@1+ (1,0) [0|0] ""  BMU_ID_0
 SG_ Internal_BMU_error : 30|1@1+ (1,0) [0|0] ""  BMU_ID_0
 SG_ Safety_sensor_error : 31|1@1+ (1,0) [0|0] ""  BMU_ID_0
 SG_ High_voltage_sensor_errors : 32|1@1+ (1,0) [0|0] ""  BMU_ID_0
 SG_ IMD_errors : 33|1@1+ (1,0) [0|0] ""  BMU_ID_0
 SG_ Isolation_error : 34|1@1+ (1,0) [0|0] ""  BMU_ID_0
 SG_ BMU_SoC_errors : 35|1@1+ (1,0) [0|0] ""  BMU_ID_0
 SG_ BMU_SoH_error : 36|1@1+ (1,0) [0|0] ""  BMU_ID_0
 SG_ Contactor_stuck_open_errors : 37|1@1+ (1,0) [0|0] ""  BMU_ID_0
 SG_ Contactor_stuck_closed_errors : 38|1@1+ (1,0) [0|0] ""  BMU_ID_0
 SG_ Contactor_supply_error : 39|1@1+ (1,0) [0|0] ""  BMU_ID_0
 SG_ Contactor_precharge_error : 40|1@1+ (1,0) [0|0] ""  BMU_ID_0
 SG_ Emergency_button_error : 41|1@1+ (1,0) [0|0] ""  BMU_ID_0
 SG_ Actuation_errors : 42|1@1+ (1,0) [0|0] ""  BMU_ID_0
 SG_ Auto_OFF : 43|1@1+ (1,0) [0|0] ""  BMU_ID_0
 SG_ Mode_mismatch : 44|1@1+ (1,0) [0|0] ""  BMU_ID_0
 SG_ Open_wire_errors : 45|1@1+ (1,0) [0|0] ""  BMU_ID_0
 SG_ Output_driver_errors_diagnostics : 46|1@1+ (1,0) [0|0] ""  BMU_ID_0
 SG_ User_forced_errors : 47|1@1+ (1,0) [0|0] ""  BMU_ID_0
 SG_ SD_error : 48|1@1+ (1,0) [0|0] ""  BMU_ID_0
 SG_ Ethernet_module_error : 49|1@1+ (1,0) [0|0] ""  BMU_ID_0
 SG_ Internal_memory_errors : 29|1@1+ (1,0) [0|0] ""  BMU_ID_0

BO_ 1329 wBMU_ID_1_msg_03_errors: 8 BMU_ID_1
 SG_ System_errors : 0|1@1+ (1,0) [0|0] ""  BMU_ID_0
 SG_ Architecture_configuration_error : 1|1@1+ (1,0) [0|0] ""  BMU_ID_0
 SG_ Parallelization_voltage_errors : 2|1@1+ (1,0) [0|0] ""  BMU_ID_0
 SG_ General_configuration_errors : 3|1@1+ (1,0) [0|0] ""  BMU_ID_0
 SG_ Parallelization_comm_lost_primar : 4|1@1+ (1,0) [0|0] ""  BMU_ID_0
 SG_ Cell_overvoltage : 5|1@1+ (1,0) [0|0] ""  BMU_ID_0
 SG_ Cell_undervoltage : 6|1@1+ (1,0) [0|0] ""  BMU_ID_0
 SG_ Comm_failure_with_CMU : 7|1@1+ (1,0) [0|0] ""  BMU_ID_0
 SG_ Internal_CMU_error : 8|1@1+ (1,0) [0|0] ""  BMU_ID_0
 SG_ Internal_CMU_temperature_error : 9|1@1+ (1,0) [0|0] ""  BMU_ID_0
 SG_ Internal_CMU_voltage_reference : 10|1@1+ (1,0) [0|0] ""  BMU_ID_0
 SG_ Cell_shortcircuit : 11|1@1+ (1,0) [0|0] ""  BMU_ID_0
 SG_ Battery_overcurrent : 12|1@1+ (1,0) [0|0] ""  BMU_ID_0
 SG_ Overload_ratio_exceeded : 13|1@1+ (1,0) [0|0] ""  BMU_ID_0
 SG_ Current_sensor_errors : 14|1@1+ (1,0) [0|0] ""  BMU_ID_0
 SG_ BMU_temperature_errors : 15|1@1+ (1,0) [0|0] ""  BMU_ID_0
 SG_ Cell_overtemperature : 16|1@1+ (1,0) [0|0] ""  BMU_ID_0
 SG_ Cell_undertemperature : 17|1@1+ (1,0) [0|0] ""  BMU_ID_0
 SG_ Balancing_overtemperature : 18|1@1+ (1,0) [0|0] ""  BMU_ID_0
 SG_ Balancing_undertemperature : 19|1@1+ (1,0) [0|0] ""  BMU_ID_0
 SG_ Max_op_cell_temp_delta : 20|1@1+ (1,0) [0|0] ""  BMU_ID_0
 SG_ Thermal_runaway : 21|1@1+ (1,0) [0|0] ""  BMU_ID_0
 SG_ OW_and_SC_detected_on_cell : 22|1@1+ (1,0) [0|0] ""  BMU_ID_0
 SG_ BMU_external_overtemperature : 23|1@1+ (1,0) [0|0] ""  BMU_ID_0
 SG_ Battery_undervoltage : 24|1@1+ (1,0) [0|0] ""  BMU_ID_0
 SG_ BMU_supply_voltage_error : 25|1@1+ (1,0) [0|0] ""  BMU_ID_0
 SG_ Battery_overvoltage : 26|1@1+ (1,0) [0|0] ""  BMU_ID_0
 SG_ Cells_unbalanced : 27|1@1+ (1,0) [0|0] ""  BMU_ID_0
 SG_ Advanced_relaxation_voltage_delt : 28|1@1+ (1,0) [0|0] ""  BMU_ID_0
 SG_ Internal_BMU_error : 30|1@1+ (1,0) [0|0] ""  BMU_ID_0
 SG_ Safety_sensor_error : 31|1@1+ (1,0) [0|0] ""  BMU_ID_0
 SG_ High_voltage_sensor_errors : 32|1@1+ (1,0) [0|0] ""  BMU_ID_0
 SG_ IMD_errors : 33|1@1+ (1,0) [0|0] ""  BMU_ID_0
 SG_ Isolation_error : 34|1@1+ (1,0) [0|0] ""  BMU_ID_0
 SG_ BMU_SoC_errors : 35|1@1+ (1,0) [0|0] ""  BMU_ID_0
 SG_ BMU_SoH_error : 36|1@1+ (1,0) [0|0] ""  BMU_ID_0
 SG_ Contactor_stuck_open_errors : 37|1@1+ (1,0) [0|0] ""  BMU_ID_0
 SG_ Contactor_stuck_closed_errors : 38|1@1+ (1,0) [0|0] ""  BMU_ID_0
 SG_ Contactor_supply_error : 39|1@1+ (1,0) [0|0] ""  BMU_ID_0
 SG_ Contactor_precharge_error : 40|1@1+ (1,0) [0|0] ""  BMU_ID_0
 SG_ Emergency_button_error : 41|1@1+ (1,0) [0|0] ""  BMU_ID_0
 SG_ Actuation_errors : 42|1@1+ (1,0) [0|0] ""  BMU_ID_0
 SG_ Auto_OFF : 43|1@1+ (1,0) [0|0] ""  BMU_ID_0
 SG_ Mode_mismatch : 44|1@1+ (1,0) [0|0] ""  BMU_ID_0
 SG_ Open_wire_errors : 45|1@1+ (1,0) [0|0] ""  BMU_ID_0
 SG_ Output_driver_errors_diagnostics : 46|1@1+ (1,0) [0|0] ""  BMU_ID_0
 SG_ User_forced_errors : 47|1@1+ (1,0) [0|0] ""  BMU_ID_0
 SG_ SD_error : 48|1@1+ (1,0) [0|0] ""  BMU_ID_0
 SG_ Ethernet_module_error : 49|1@1+ (1,0) [0|0] ""  BMU_ID_0
 SG_ Internal_memory_errors : 29|1@1+ (1,0) [0|0] ""  BMU_ID_0

BO_ 1330 wBMU_ID_2_msg_03_errors: 8 BMU_ID_2
 SG_ System_errors : 0|1@1+ (1,0) [0|0] ""  BMU_ID_0
 SG_ Architecture_configuration_error : 1|1@1+ (1,0) [0|0] ""  BMU_ID_0
 SG_ Parallelization_voltage_errors : 2|1@1+ (1,0) [0|0] ""  BMU_ID_0
 SG_ General_configuration_errors : 3|1@1+ (1,0) [0|0] ""  BMU_ID_0
 SG_ Parallelization_comm_lost_primar : 4|1@1+ (1,0) [0|0] ""  BMU_ID_0
 SG_ Cell_overvoltage : 5|1@1+ (1,0) [0|0] ""  BMU_ID_0
 SG_ Cell_undervoltage : 6|1@1+ (1,0) [0|0] ""  BMU_ID_0
 SG_ Comm_failure_with_CMU : 7|1@1+ (1,0) [0|0] ""  BMU_ID_0
 SG_ Internal_CMU_error : 8|1@1+ (1,0) [0|0] ""  BMU_ID_0
 SG_ Internal_CMU_temperature_error : 9|1@1+ (1,0) [0|0] ""  BMU_ID_0
 SG_ Internal_CMU_voltage_reference : 10|1@1+ (1,0) [0|0] ""  BMU_ID_0
 SG_ Cell_shortcircuit : 11|1@1+ (1,0) [0|0] ""  BMU_ID_0
 SG_ Battery_overcurrent : 12|1@1+ (1,0) [0|0] ""  BMU_ID_0
 SG_ Overload_ratio_exceeded : 13|1@1+ (1,0) [0|0] ""  BMU_ID_0
 SG_ Current_sensor_errors : 14|1@1+ (1,0) [0|0] ""  BMU_ID_0
 SG_ BMU_temperature_errors : 15|1@1+ (1,0) [0|0] ""  BMU_ID_0
 SG_ Cell_overtemperature : 16|1@1+ (1,0) [0|0] ""  BMU_ID_0
 SG_ Cell_undertemperature : 17|1@1+ (1,0) [0|0] ""  BMU_ID_0
 SG_ Balancing_overtemperature : 18|1@1+ (1,0) [0|0] ""  BMU_ID_0
 SG_ Balancing_undertemperature : 19|1@1+ (1,0) [0|0] ""  BMU_ID_0
 SG_ Max_op_cell_temp_delta : 20|1@1+ (1,0) [0|0] ""  BMU_ID_0
 SG_ Thermal_runaway : 21|1@1+ (1,0) [0|0] ""  BMU_ID_0
 SG_ OW_and_SC_detected_on_cell : 22|1@1+ (1,0) [0|0] ""  BMU_ID_0
 SG_ BMU_external_overtemperature : 23|1@1+ (1,0) [0|0] ""  BMU_ID_0
 SG_ Battery_undervoltage : 24|1@1+ (1,0) [0|0] ""  BMU_ID_0
 SG_ BMU_supply_voltage_error : 25|1@1+ (1,0) [0|0] ""  BMU_ID_0
 SG_ Battery_overvoltage : 26|1@1+ (1,0) [0|0] ""  BMU_ID_0
 SG_ Cells_unbalanced : 27|1@1+ (1,0) [0|0] ""  BMU_ID_0
 SG_ Advanced_relaxation_voltage_delt : 28|1@1+ (1,0) [0|0] ""  BMU_ID_0
 SG_ Internal_BMU_error : 30|1@1+ (1,0) [0|0] ""  BMU_ID_0
 SG_ Safety_sensor_error : 31|1@1+ (1,0) [0|0] ""  BMU_ID_0
 SG_ High_voltage_sensor_errors : 32|1@1+ (1,0) [0|0] ""  BMU_ID_0
 SG_ IMD_errors : 33|1@1+ (1,0) [0|0] ""  BMU_ID_0
 SG_ Isolation_error : 34|1@1+ (1,0) [0|0] ""  BMU_ID_0
 SG_ BMU_SoC_errors : 35|1@1+ (1,0) [0|0] ""  BMU_ID_0
 SG_ BMU_SoH_error : 36|1@1+ (1,0) [0|0] ""  BMU_ID_0
 SG_ Contactor_stuck_open_errors : 37|1@1+ (1,0) [0|0] ""  BMU_ID_0
 SG_ Contactor_stuck_closed_errors : 38|1@1+ (1,0) [0|0] ""  BMU_ID_0
 SG_ Contactor_supply_error : 39|1@1+ (1,0) [0|0] ""  BMU_ID_0
 SG_ Contactor_precharge_error : 40|1@1+ (1,0) [0|0] ""  BMU_ID_0
 SG_ Emergency_button_error : 41|1@1+ (1,0) [0|0] ""  BMU_ID_0
 SG_ Actuation_errors : 42|1@1+ (1,0) [0|0] ""  BMU_ID_0
 SG_ Auto_OFF : 43|1@1+ (1,0) [0|0] ""  BMU_ID_0
 SG_ Mode_mismatch : 44|1@1+ (1,0) [0|0] ""  BMU_ID_0
 SG_ Open_wire_errors : 45|1@1+ (1,0) [0|0] ""  BMU_ID_0
 SG_ Output_driver_errors_diagnostics : 46|1@1+ (1,0) [0|0] ""  BMU_ID_0
 SG_ User_forced_errors : 47|1@1+ (1,0) [0|0] ""  BMU_ID_0
 SG_ SD_error : 48|1@1+ (1,0) [0|0] ""  BMU_ID_0
 SG_ Ethernet_module_error : 49|1@1+ (1,0) [0|0] ""  BMU_ID_0
 SG_ Internal_memory_errors : 29|1@1+ (1,0) [0|0] ""  BMU_ID_0

BO_ 1331 wBMU_ID_3_msg_03_errors: 8 BMU_ID_3
 SG_ System_errors : 0|1@1+ (1,0) [0|0] ""  BMU_ID_0
 SG_ Architecture_configuration_error : 1|1@1+ (1,0) [0|0] ""  BMU_ID_0
 SG_ Parallelization_voltage_errors : 2|1@1+ (1,0) [0|0] ""  BMU_ID_0
 SG_ General_configuration_errors : 3|1@1+ (1,0) [0|0] ""  BMU_ID_0
 SG_ Parallelization_comm_lost_primar : 4|1@1+ (1,0) [0|0] ""  BMU_ID_0
 SG_ Cell_overvoltage : 5|1@1+ (1,0) [0|0] ""  BMU_ID_0
 SG_ Cell_undervoltage : 6|1@1+ (1,0) [0|0] ""  BMU_ID_0
 SG_ Comm_failure_with_CMU : 7|1@1+ (1,0) [0|0] ""  BMU_ID_0
 SG_ Internal_CMU_error : 8|1@1+ (1,0) [0|0] ""  BMU_ID_0
 SG_ Internal_CMU_temperature_error : 9|1@1+ (1,0) [0|0] ""  BMU_ID_0
 SG_ Internal_CMU_voltage_reference : 10|1@1+ (1,0) [0|0] ""  BMU_ID_0
 SG_ Cell_shortcircuit : 11|1@1+ (1,0) [0|0] ""  BMU_ID_0
 SG_ Battery_overcurrent : 12|1@1+ (1,0) [0|0] ""  BMU_ID_0
 SG_ Overload_ratio_exceeded : 13|1@1+ (1,0) [0|0] ""  BMU_ID_0
 SG_ Current_sensor_errors : 14|1@1+ (1,0) [0|0] ""  BMU_ID_0
 SG_ BMU_temperature_errors : 15|1@1+ (1,0) [0|0] ""  BMU_ID_0
 SG_ Cell_overtemperature : 16|1@1+ (1,0) [0|0] ""  BMU_ID_0
 SG_ Cell_undertemperature : 17|1@1+ (1,0) [0|0] ""  BMU_ID_0
 SG_ Balancing_overtemperature : 18|1@1+ (1,0) [0|0] ""  BMU_ID_0
 SG_ Balancing_undertemperature : 19|1@1+ (1,0) [0|0] ""  BMU_ID_0
 SG_ Max_op_cell_temp_delta : 20|1@1+ (1,0) [0|0] ""  BMU_ID_0
 SG_ Thermal_runaway : 21|1@1+ (1,0) [0|0] ""  BMU_ID_0
 SG_ OW_and_SC_detected_on_cell : 22|1@1+ (1,0) [0|0] ""  BMU_ID_0
 SG_ BMU_external_overtemperature : 23|1@1+ (1,0) [0|0] ""  BMU_ID_0
 SG_ Battery_undervoltage : 24|1@1+ (1,0) [0|0] ""  BMU_ID_0
 SG_ BMU_supply_voltage_error : 25|1@1+ (1,0) [0|0] ""  BMU_ID_0
 SG_ Battery_overvoltage : 26|1@1+ (1,0) [0|0] ""  BMU_ID_0
 SG_ Cells_unbalanced : 27|1@1+ (1,0) [0|0] ""  BMU_ID_0
 SG_ Advanced_relaxation_voltage_delt : 28|1@1+ (1,0) [0|0] ""  BMU_ID_0
 SG_ Internal_BMU_error : 30|1@1+ (1,0) [0|0] ""  BMU_ID_0
 SG_ Safety_sensor_error : 31|1@1+ (1,0) [0|0] ""  BMU_ID_0
 SG_ High_voltage_sensor_errors : 32|1@1+ (1,0) [0|0] ""  BMU_ID_0
 SG_ IMD_errors : 33|1@1+ (1,0) [0|0] ""  BMU_ID_0
 SG_ Isolation_error : 34|1@1+ (1,0) [0|0] ""  BMU_ID_0
 SG_ BMU_SoC_errors : 35|1@1+ (1,0) [0|0] ""  BMU_ID_0
 SG_ BMU_SoH_error : 36|1@1+ (1,0) [0|0] ""  BMU_ID_0
 SG_ Contactor_stuck_open_errors : 37|1@1+ (1,0) [0|0] ""  BMU_ID_0
 SG_ Contactor_stuck_closed_errors : 38|1@1+ (1,0) [0|0] ""  BMU_ID_0
 SG_ Contactor_supply_error : 39|1@1+ (1,0) [0|0] ""  BMU_ID_0
 SG_ Contactor_precharge_error : 40|1@1+ (1,0) [0|0] ""  BMU_ID_0
 SG_ Emergency_button_error : 41|1@1+ (1,0) [0|0] ""  BMU_ID_0
 SG_ Actuation_errors : 42|1@1+ (1,0) [0|0] ""  BMU_ID_0
 SG_ Auto_OFF : 43|1@1+ (1,0) [0|0] ""  BMU_ID_0
 SG_ Mode_mismatch : 44|1@1+ (1,0) [0|0] ""  BMU_ID_0
 SG_ Open_wire_errors : 45|1@1+ (1,0) [0|0] ""  BMU_ID_0
 SG_ Output_driver_errors_diagnostics : 46|1@1+ (1,0) [0|0] ""  BMU_ID_0
 SG_ User_forced_errors : 47|1@1+ (1,0) [0|0] ""  BMU_ID_0
 SG_ SD_error : 48|1@1+ (1,0) [0|0] ""  BMU_ID_0
 SG_ Ethernet_module_error : 49|1@1+ (1,0) [0|0] ""  BMU_ID_0
 SG_ Internal_memory_errors : 29|1@1+ (1,0) [0|0] ""  BMU_ID_0

BO_ 1332 wBMU_ID_4_msg_03_errors: 8 BMU_ID_4
 SG_ System_errors : 0|1@1+ (1,0) [0|0] ""  BMU_ID_0
 SG_ Architecture_configuration_error : 1|1@1+ (1,0) [0|0] ""  BMU_ID_0
 SG_ Parallelization_voltage_errors : 2|1@1+ (1,0) [0|0] ""  BMU_ID_0
 SG_ General_configuration_errors : 3|1@1+ (1,0) [0|0] ""  BMU_ID_0
 SG_ Parallelization_comm_lost_primar : 4|1@1+ (1,0) [0|0] ""  BMU_ID_0
 SG_ Cell_overvoltage : 5|1@1+ (1,0) [0|0] ""  BMU_ID_0
 SG_ Cell_undervoltage : 6|1@1+ (1,0) [0|0] ""  BMU_ID_0
 SG_ Comm_failure_with_CMU : 7|1@1+ (1,0) [0|0] ""  BMU_ID_0
 SG_ Internal_CMU_error : 8|1@1+ (1,0) [0|0] ""  BMU_ID_0
 SG_ Internal_CMU_temperature_error : 9|1@1+ (1,0) [0|0] ""  BMU_ID_0
 SG_ Internal_CMU_voltage_reference : 10|1@1+ (1,0) [0|0] ""  BMU_ID_0
 SG_ Cell_shortcircuit : 11|1@1+ (1,0) [0|0] ""  BMU_ID_0
 SG_ Battery_overcurrent : 12|1@1+ (1,0) [0|0] ""  BMU_ID_0
 SG_ Overload_ratio_exceeded : 13|1@1+ (1,0) [0|0] ""  BMU_ID_0
 SG_ Current_sensor_errors : 14|1@1+ (1,0) [0|0] ""  BMU_ID_0
 SG_ BMU_temperature_errors : 15|1@1+ (1,0) [0|0] ""  BMU_ID_0
 SG_ Cell_overtemperature : 16|1@1+ (1,0) [0|0] ""  BMU_ID_0
 SG_ Cell_undertemperature : 17|1@1+ (1,0) [0|0] ""  BMU_ID_0
 SG_ Balancing_overtemperature : 18|1@1+ (1,0) [0|0] ""  BMU_ID_0
 SG_ Balancing_undertemperature : 19|1@1+ (1,0) [0|0] ""  BMU_ID_0
 SG_ Max_op_cell_temp_delta : 20|1@1+ (1,0) [0|0] ""  BMU_ID_0
 SG_ Thermal_runaway : 21|1@1+ (1,0) [0|0] ""  BMU_ID_0
 SG_ OW_and_SC_detected_on_cell : 22|1@1+ (1,0) [0|0] ""  BMU_ID_0
 SG_ BMU_external_overtemperature : 23|1@1+ (1,0) [0|0] ""  BMU_ID_0
 SG_ Battery_undervoltage : 24|1@1+ (1,0) [0|0] ""  BMU_ID_0
 SG_ BMU_supply_voltage_error : 25|1@1+ (1,0) [0|0] ""  BMU_ID_0
 SG_ Battery_overvoltage : 26|1@1+ (1,0) [0|0] ""  BMU_ID_0
 SG_ Cells_unbalanced : 27|1@1+ (1,0) [0|0] ""  BMU_ID_0
 SG_ Advanced_relaxation_voltage_delt : 28|1@1+ (1,0) [0|0] ""  BMU_ID_0
 SG_ Internal_BMU_error : 30|1@1+ (1,0) [0|0] ""  BMU_ID_0
 SG_ Safety_sensor_error : 31|1@1+ (1,0) [0|0] ""  BMU_ID_0
 SG_ High_voltage_sensor_errors : 32|1@1+ (1,0) [0|0] ""  BMU_ID_0
 SG_ IMD_errors : 33|1@1+ (1,0) [0|0] ""  BMU_ID_0
 SG_ Isolation_error : 34|1@1+ (1,0) [0|0] ""  BMU_ID_0
 SG_ BMU_SoC_errors : 35|1@1+ (1,0) [0|0] ""  BMU_ID_0
 SG_ BMU_SoH_error : 36|1@1+ (1,0) [0|0] ""  BMU_ID_0
 SG_ Contactor_stuck_open_errors : 37|1@1+ (1,0) [0|0] ""  BMU_ID_0
 SG_ Contactor_stuck_closed_errors : 38|1@1+ (1,0) [0|0] ""  BMU_ID_0
 SG_ Contactor_supply_error : 39|1@1+ (1,0) [0|0] ""  BMU_ID_0
 SG_ Contactor_precharge_error : 40|1@1+ (1,0) [0|0] ""  BMU_ID_0
 SG_ Emergency_button_error : 41|1@1+ (1,0) [0|0] ""  BMU_ID_0
 SG_ Actuation_errors : 42|1@1+ (1,0) [0|0] ""  BMU_ID_0
 SG_ Auto_OFF : 43|1@1+ (1,0) [0|0] ""  BMU_ID_0
 SG_ Mode_mismatch : 44|1@1+ (1,0) [0|0] ""  BMU_ID_0
 SG_ Open_wire_errors : 45|1@1+ (1,0) [0|0] ""  BMU_ID_0
 SG_ Output_driver_errors_diagnostics : 46|1@1+ (1,0) [0|0] ""  BMU_ID_0
 SG_ User_forced_errors : 47|1@1+ (1,0) [0|0] ""  BMU_ID_0
 SG_ SD_error : 48|1@1+ (1,0) [0|0] ""  BMU_ID_0
 SG_ Ethernet_module_error : 49|1@1+ (1,0) [0|0] ""  BMU_ID_0
 SG_ Internal_memory_errors : 29|1@1+ (1,0) [0|0] ""  BMU_ID_0

BO_ 1333 wBMU_ID_5_msg_03_errors: 8 BMU_ID_5
 SG_ System_errors : 0|1@1+ (1,0) [0|0] ""  BMU_ID_0
 SG_ Architecture_configuration_error : 1|1@1+ (1,0) [0|0] ""  BMU_ID_0
 SG_ Parallelization_voltage_errors : 2|1@1+ (1,0) [0|0] ""  BMU_ID_0
 SG_ General_configuration_errors : 3|1@1+ (1,0) [0|0] ""  BMU_ID_0
 SG_ Parallelization_comm_lost_primar : 4|1@1+ (1,0) [0|0] ""  BMU_ID_0
 SG_ Cell_overvoltage : 5|1@1+ (1,0) [0|0] ""  BMU_ID_0
 SG_ Cell_undervoltage : 6|1@1+ (1,0) [0|0] ""  BMU_ID_0
 SG_ Comm_failure_with_CMU : 7|1@1+ (1,0) [0|0] ""  BMU_ID_0
 SG_ Internal_CMU_error : 8|1@1+ (1,0) [0|0] ""  BMU_ID_0
 SG_ Internal_CMU_temperature_error : 9|1@1+ (1,0) [0|0] ""  BMU_ID_0
 SG_ Internal_CMU_voltage_reference : 10|1@1+ (1,0) [0|0] ""  BMU_ID_0
 SG_ Cell_shortcircuit : 11|1@1+ (1,0) [0|0] ""  BMU_ID_0
 SG_ Battery_overcurrent : 12|1@1+ (1,0) [0|0] ""  BMU_ID_0
 SG_ Overload_ratio_exceeded : 13|1@1+ (1,0) [0|0] ""  BMU_ID_0
 SG_ Current_sensor_errors : 14|1@1+ (1,0) [0|0] ""  BMU_ID_0
 SG_ BMU_temperature_errors : 15|1@1+ (1,0) [0|0] ""  BMU_ID_0
 SG_ Cell_overtemperature : 16|1@1+ (1,0) [0|0] ""  BMU_ID_0
 SG_ Cell_undertemperature : 17|1@1+ (1,0) [0|0] ""  BMU_ID_0
 SG_ Balancing_overtemperature : 18|1@1+ (1,0) [0|0] ""  BMU_ID_0
 SG_ Balancing_undertemperature : 19|1@1+ (1,0) [0|0] ""  BMU_ID_0
 SG_ Max_op_cell_temp_delta : 20|1@1+ (1,0) [0|0] ""  BMU_ID_0
 SG_ Thermal_runaway : 21|1@1+ (1,0) [0|0] ""  BMU_ID_0
 SG_ OW_and_SC_detected_on_cell : 22|1@1+ (1,0) [0|0] ""  BMU_ID_0
 SG_ BMU_external_overtemperature : 23|1@1+ (1,0) [0|0] ""  BMU_ID_0
 SG_ Battery_undervoltage : 24|1@1+ (1,0) [0|0] ""  BMU_ID_0
 SG_ BMU_supply_voltage_error : 25|1@1+ (1,0) [0|0] ""  BMU_ID_0
 SG_ Battery_overvoltage : 26|1@1+ (1,0) [0|0] ""  BMU_ID_0
 SG_ Cells_unbalanced : 27|1@1+ (1,0) [0|0] ""  BMU_ID_0
 SG_ Advanced_relaxation_voltage_delt : 28|1@1+ (1,0) [0|0] ""  BMU_ID_0
 SG_ Internal_BMU_error : 30|1@1+ (1,0) [0|0] ""  BMU_ID_0
 SG_ Safety_sensor_error : 31|1@1+ (1,0) [0|0] ""  BMU_ID_0
 SG_ High_voltage_sensor_errors : 32|1@1+ (1,0) [0|0] ""  BMU_ID_0
 SG_ IMD_errors : 33|1@1+ (1,0) [0|0] ""  BMU_ID_0
 SG_ Isolation_error : 34|1@1+ (1,0) [0|0] ""  BMU_ID_0
 SG_ BMU_SoC_errors : 35|1@1+ (1,0) [0|0] ""  BMU_ID_0
 SG_ BMU_SoH_error : 36|1@1+ (1,0) [0|0] ""  BMU_ID_0
 SG_ Contactor_stuck_open_errors : 37|1@1+ (1,0) [0|0] ""  BMU_ID_0
 SG_ Contactor_stuck_closed_errors : 38|1@1+ (1,0) [0|0] ""  BMU_ID_0
 SG_ Contactor_supply_error : 39|1@1+ (1,0) [0|0] ""  BMU_ID_0
 SG_ Contactor_precharge_error : 40|1@1+ (1,0) [0|0] ""  BMU_ID_0
 SG_ Emergency_button_error : 41|1@1+ (1,0) [0|0] ""  BMU_ID_0
 SG_ Actuation_errors : 42|1@1+ (1,0) [0|0] ""  BMU_ID_0
 SG_ Auto_OFF : 43|1@1+ (1,0) [0|0] ""  BMU_ID_0
 SG_ Mode_mismatch : 44|1@1+ (1,0) [0|0] ""  BMU_ID_0
 SG_ Open_wire_errors : 45|1@1+ (1,0) [0|0] ""  BMU_ID_0
 SG_ Output_driver_errors_diagnostics : 46|1@1+ (1,0) [0|0] ""  BMU_ID_0
 SG_ User_forced_errors : 47|1@1+ (1,0) [0|0] ""  BMU_ID_0
 SG_ SD_error : 48|1@1+ (1,0) [0|0] ""  BMU_ID_0
 SG_ Ethernet_module_error : 49|1@1+ (1,0) [0|0] ""  BMU_ID_0
 SG_ Internal_memory_errors : 29|1@1+ (1,0) [0|0] ""  BMU_ID_0

BO_ 1334 wBMU_ID_6_msg_03_errors: 8 BMU_ID_6
 SG_ System_errors : 0|1@1+ (1,0) [0|0] ""  BMU_ID_0
 SG_ Architecture_configuration_error : 1|1@1+ (1,0) [0|0] ""  BMU_ID_0
 SG_ Parallelization_voltage_errors : 2|1@1+ (1,0) [0|0] ""  BMU_ID_0
 SG_ General_configuration_errors : 3|1@1+ (1,0) [0|0] ""  BMU_ID_0
 SG_ Parallelization_comm_lost_primar : 4|1@1+ (1,0) [0|0] ""  BMU_ID_0
 SG_ Cell_overvoltage : 5|1@1+ (1,0) [0|0] ""  BMU_ID_0
 SG_ Cell_undervoltage : 6|1@1+ (1,0) [0|0] ""  BMU_ID_0
 SG_ Comm_failure_with_CMU : 7|1@1+ (1,0) [0|0] ""  BMU_ID_0
 SG_ Internal_CMU_error : 8|1@1+ (1,0) [0|0] ""  BMU_ID_0
 SG_ Internal_CMU_temperature_error : 9|1@1+ (1,0) [0|0] ""  BMU_ID_0
 SG_ Internal_CMU_voltage_reference : 10|1@1+ (1,0) [0|0] ""  BMU_ID_0
 SG_ Cell_shortcircuit : 11|1@1+ (1,0) [0|0] ""  BMU_ID_0
 SG_ Battery_overcurrent : 12|1@1+ (1,0) [0|0] ""  BMU_ID_0
 SG_ Overload_ratio_exceeded : 13|1@1+ (1,0) [0|0] ""  BMU_ID_0
 SG_ Current_sensor_errors : 14|1@1+ (1,0) [0|0] ""  BMU_ID_0
 SG_ BMU_temperature_errors : 15|1@1+ (1,0) [0|0] ""  BMU_ID_0
 SG_ Cell_overtemperature : 16|1@1+ (1,0) [0|0] ""  BMU_ID_0
 SG_ Cell_undertemperature : 17|1@1+ (1,0) [0|0] ""  BMU_ID_0
 SG_ Balancing_overtemperature : 18|1@1+ (1,0) [0|0] ""  BMU_ID_0
 SG_ Balancing_undertemperature : 19|1@1+ (1,0) [0|0] ""  BMU_ID_0
 SG_ Max_op_cell_temp_delta : 20|1@1+ (1,0) [0|0] ""  BMU_ID_0
 SG_ Thermal_runaway : 21|1@1+ (1,0) [0|0] ""  BMU_ID_0
 SG_ OW_and_SC_detected_on_cell : 22|1@1+ (1,0) [0|0] ""  BMU_ID_0
 SG_ BMU_external_overtemperature : 23|1@1+ (1,0) [0|0] ""  BMU_ID_0
 SG_ Battery_undervoltage : 24|1@1+ (1,0) [0|0] ""  BMU_ID_0
 SG_ BMU_supply_voltage_error : 25|1@1+ (1,0) [0|0] ""  BMU_ID_0
 SG_ Battery_overvoltage : 26|1@1+ (1,0) [0|0] ""  BMU_ID_0
 SG_ Cells_unbalanced : 27|1@1+ (1,0) [0|0] ""  BMU_ID_0
 SG_ Advanced_relaxation_voltage_delt : 28|1@1+ (1,0) [0|0] ""  BMU_ID_0
 SG_ Internal_BMU_error : 30|1@1+ (1,0) [0|0] ""  BMU_ID_0
 SG_ Safety_sensor_error : 31|1@1+ (1,0) [0|0] ""  BMU_ID_0
 SG_ High_voltage_sensor_errors : 32|1@1+ (1,0) [0|0] ""  BMU_ID_0
 SG_ IMD_errors : 33|1@1+ (1,0) [0|0] ""  BMU_ID_0
 SG_ Isolation_error : 34|1@1+ (1,0) [0|0] ""  BMU_ID_0
 SG_ BMU_SoC_errors : 35|1@1+ (1,0) [0|0] ""  BMU_ID_0
 SG_ BMU_SoH_error : 36|1@1+ (1,0) [0|0] ""  BMU_ID_0
 SG_ Contactor_stuck_open_errors : 37|1@1+ (1,0) [0|0] ""  BMU_ID_0
 SG_ Contactor_stuck_closed_errors : 38|1@1+ (1,0) [0|0] ""  BMU_ID_0
 SG_ Contactor_supply_error : 39|1@1+ (1,0) [0|0] ""  BMU_ID_0
 SG_ Contactor_precharge_error : 40|1@1+ (1,0) [0|0] ""  BMU_ID_0
 SG_ Emergency_button_error : 41|1@1+ (1,0) [0|0] ""  BMU_ID_0
 SG_ Actuation_errors : 42|1@1+ (1,0) [0|0] ""  BMU_ID_0
 SG_ Auto_OFF : 43|1@1+ (1,0) [0|0] ""  BMU_ID_0
 SG_ Mode_mismatch : 44|1@1+ (1,0) [0|0] ""  BMU_ID_0
 SG_ Open_wire_errors : 45|1@1+ (1,0) [0|0] ""  BMU_ID_0
 SG_ Output_driver_errors_diagnostics : 46|1@1+ (1,0) [0|0] ""  BMU_ID_0
 SG_ User_forced_errors : 47|1@1+ (1,0) [0|0] ""  BMU_ID_0
 SG_ SD_error : 48|1@1+ (1,0) [0|0] ""  BMU_ID_0
 SG_ Ethernet_module_error : 49|1@1+ (1,0) [0|0] ""  BMU_ID_0
 SG_ Internal_memory_errors : 29|1@1+ (1,0) [0|0] ""  BMU_ID_0

BO_ 1335 wBMU_ID_7_msg_03_errors: 8 BMU_ID_7
 SG_ System_errors : 0|1@1+ (1,0) [0|0] ""  BMU_ID_0
 SG_ Architecture_configuration_error : 1|1@1+ (1,0) [0|0] ""  BMU_ID_0
 SG_ Parallelization_voltage_errors : 2|1@1+ (1,0) [0|0] ""  BMU_ID_0
 SG_ General_configuration_errors : 3|1@1+ (1,0) [0|0] ""  BMU_ID_0
 SG_ Parallelization_comm_lost_primar : 4|1@1+ (1,0) [0|0] ""  BMU_ID_0
 SG_ Cell_overvoltage : 5|1@1+ (1,0) [0|0] ""  BMU_ID_0
 SG_ Cell_undervoltage : 6|1@1+ (1,0) [0|0] ""  BMU_ID_0
 SG_ Comm_failure_with_CMU : 7|1@1+ (1,0) [0|0] ""  BMU_ID_0
 SG_ Internal_CMU_error : 8|1@1+ (1,0) [0|0] ""  BMU_ID_0
 SG_ Internal_CMU_temperature_error : 9|1@1+ (1,0) [0|0] ""  BMU_ID_0
 SG_ Internal_CMU_voltage_reference : 10|1@1+ (1,0) [0|0] ""  BMU_ID_0
 SG_ Cell_shortcircuit : 11|1@1+ (1,0) [0|0] ""  BMU_ID_0
 SG_ Battery_overcurrent : 12|1@1+ (1,0) [0|0] ""  BMU_ID_0
 SG_ Overload_ratio_exceeded : 13|1@1+ (1,0) [0|0] ""  BMU_ID_0
 SG_ Current_sensor_errors : 14|1@1+ (1,0) [0|0] ""  BMU_ID_0
 SG_ BMU_temperature_errors : 15|1@1+ (1,0) [0|0] ""  BMU_ID_0
 SG_ Cell_overtemperature : 16|1@1+ (1,0) [0|0] ""  BMU_ID_0
 SG_ Cell_undertemperature : 17|1@1+ (1,0) [0|0] ""  BMU_ID_0
 SG_ Balancing_overtemperature : 18|1@1+ (1,0) [0|0] ""  BMU_ID_0
 SG_ Balancing_undertemperature : 19|1@1+ (1,0) [0|0] ""  BMU_ID_0
 SG_ Max_op_cell_temp_delta : 20|1@1+ (1,0) [0|0] ""  BMU_ID_0
 SG_ Thermal_runaway : 21|1@1+ (1,0) [0|0] ""  BMU_ID_0
 SG_ OW_and_SC_detected_on_cell : 22|1@1+ (1,0) [0|0] ""  BMU_ID_0
 SG_ BMU_external_overtemperature : 23|1@1+ (1,0) [0|0] ""  BMU_ID_0
 SG_ Battery_undervoltage : 24|1@1+ (1,0) [0|0] ""  BMU_ID_0
 SG_ BMU_supply_voltage_error : 25|1@1+ (1,0) [0|0] ""  BMU_ID_0
 SG_ Battery_overvoltage : 26|1@1+ (1,0) [0|0] ""  BMU_ID_0
 SG_ Cells_unbalanced : 27|1@1+ (1,0) [0|0] ""  BMU_ID_0
 SG_ Advanced_relaxation_voltage_delt : 28|1@1+ (1,0) [0|0] ""  BMU_ID_0
 SG_ Internal_BMU_error : 30|1@1+ (1,0) [0|0] ""  BMU_ID_0
 SG_ Safety_sensor_error : 31|1@1+ (1,0) [0|0] ""  BMU_ID_0
 SG_ High_voltage_sensor_errors : 32|1@1+ (1,0) [0|0] ""  BMU_ID_0
 SG_ IMD_errors : 33|1@1+ (1,0) [0|0] ""  BMU_ID_0
 SG_ Isolation_error : 34|1@1+ (1,0) [0|0] ""  BMU_ID_0
 SG_ BMU_SoC_errors : 35|1@1+ (1,0) [0|0] ""  BMU_ID_0
 SG_ BMU_SoH_error : 36|1@1+ (1,0) [0|0] ""  BMU_ID_0
 SG_ Contactor_stuck_open_errors : 37|1@1+ (1,0) [0|0] ""  BMU_ID_0
 SG_ Contactor_stuck_closed_errors : 38|1@1+ (1,0) [0|0] ""  BMU_ID_0
 SG_ Contactor_supply_error : 39|1@1+ (1,0) [0|0] ""  BMU_ID_0
 SG_ Contactor_precharge_error : 40|1@1+ (1,0) [0|0] ""  BMU_ID_0
 SG_ Emergency_button_error : 41|1@1+ (1,0) [0|0] ""  BMU_ID_0
 SG_ Actuation_errors : 42|1@1+ (1,0) [0|0] ""  BMU_ID_0
 SG_ Auto_OFF : 43|1@1+ (1,0) [0|0] ""  BMU_ID_0
 SG_ Mode_mismatch : 44|1@1+ (1,0) [0|0] ""  BMU_ID_0
 SG_ Open_wire_errors : 45|1@1+ (1,0) [0|0] ""  BMU_ID_0
 SG_ Output_driver_errors_diagnostics : 46|1@1+ (1,0) [0|0] ""  BMU_ID_0
 SG_ User_forced_errors : 47|1@1+ (1,0) [0|0] ""  BMU_ID_0
 SG_ SD_error : 48|1@1+ (1,0) [0|0] ""  BMU_ID_0
 SG_ Ethernet_module_error : 49|1@1+ (1,0) [0|0] ""  BMU_ID_0
 SG_ Internal_memory_errors : 29|1@1+ (1,0) [0|0] ""  BMU_ID_0

BO_ 1336 wBMU_ID_8_msg_03_errors: 8 BMU_ID_8
 SG_ System_errors : 0|1@1+ (1,0) [0|0] ""  BMU_ID_0
 SG_ Architecture_configuration_error : 1|1@1+ (1,0) [0|0] ""  BMU_ID_0
 SG_ Parallelization_voltage_errors : 2|1@1+ (1,0) [0|0] ""  BMU_ID_0
 SG_ General_configuration_errors : 3|1@1+ (1,0) [0|0] ""  BMU_ID_0
 SG_ Parallelization_comm_lost_primar : 4|1@1+ (1,0) [0|0] ""  BMU_ID_0
 SG_ Cell_overvoltage : 5|1@1+ (1,0) [0|0] ""  BMU_ID_0
 SG_ Cell_undervoltage : 6|1@1+ (1,0) [0|0] ""  BMU_ID_0
 SG_ Comm_failure_with_CMU : 7|1@1+ (1,0) [0|0] ""  BMU_ID_0
 SG_ Internal_CMU_error : 8|1@1+ (1,0) [0|0] ""  BMU_ID_0
 SG_ Internal_CMU_temperature_error : 9|1@1+ (1,0) [0|0] ""  BMU_ID_0
 SG_ Internal_CMU_voltage_reference : 10|1@1+ (1,0) [0|0] ""  BMU_ID_0
 SG_ Cell_shortcircuit : 11|1@1+ (1,0) [0|0] ""  BMU_ID_0
 SG_ Battery_overcurrent : 12|1@1+ (1,0) [0|0] ""  BMU_ID_0
 SG_ Overload_ratio_exceeded : 13|1@1+ (1,0) [0|0] ""  BMU_ID_0
 SG_ Current_sensor_errors : 14|1@1+ (1,0) [0|0] ""  BMU_ID_0
 SG_ BMU_temperature_errors : 15|1@1+ (1,0) [0|0] ""  BMU_ID_0
 SG_ Cell_overtemperature : 16|1@1+ (1,0) [0|0] ""  BMU_ID_0
 SG_ Cell_undertemperature : 17|1@1+ (1,0) [0|0] ""  BMU_ID_0
 SG_ Balancing_overtemperature : 18|1@1+ (1,0) [0|0] ""  BMU_ID_0
 SG_ Balancing_undertemperature : 19|1@1+ (1,0) [0|0] ""  BMU_ID_0
 SG_ Max_op_cell_temp_delta : 20|1@1+ (1,0) [0|0] ""  BMU_ID_0
 SG_ Thermal_runaway : 21|1@1+ (1,0) [0|0] ""  BMU_ID_0
 SG_ OW_and_SC_detected_on_cell : 22|1@1+ (1,0) [0|0] ""  BMU_ID_0
 SG_ BMU_external_overtemperature : 23|1@1+ (1,0) [0|0] ""  BMU_ID_0
 SG_ Battery_undervoltage : 24|1@1+ (1,0) [0|0] ""  BMU_ID_0
 SG_ BMU_supply_voltage_error : 25|1@1+ (1,0) [0|0] ""  BMU_ID_0
 SG_ Battery_overvoltage : 26|1@1+ (1,0) [0|0] ""  BMU_ID_0
 SG_ Cells_unbalanced : 27|1@1+ (1,0) [0|0] ""  BMU_ID_0
 SG_ Advanced_relaxation_voltage_delt : 28|1@1+ (1,0) [0|0] ""  BMU_ID_0
 SG_ Internal_BMU_error : 30|1@1+ (1,0) [0|0] ""  BMU_ID_0
 SG_ Safety_sensor_error : 31|1@1+ (1,0) [0|0] ""  BMU_ID_0
 SG_ High_voltage_sensor_errors : 32|1@1+ (1,0) [0|0] ""  BMU_ID_0
 SG_ IMD_errors : 33|1@1+ (1,0) [0|0] ""  BMU_ID_0
 SG_ Isolation_error : 34|1@1+ (1,0) [0|0] ""  BMU_ID_0
 SG_ BMU_SoC_errors : 35|1@1+ (1,0) [0|0] ""  BMU_ID_0
 SG_ BMU_SoH_error : 36|1@1+ (1,0) [0|0] ""  BMU_ID_0
 SG_ Contactor_stuck_open_errors : 37|1@1+ (1,0) [0|0] ""  BMU_ID_0
 SG_ Contactor_stuck_closed_errors : 38|1@1+ (1,0) [0|0] ""  BMU_ID_0
 SG_ Contactor_supply_error : 39|1@1+ (1,0) [0|0] ""  BMU_ID_0
 SG_ Contactor_precharge_error : 40|1@1+ (1,0) [0|0] ""  BMU_ID_0
 SG_ Emergency_button_error : 41|1@1+ (1,0) [0|0] ""  BMU_ID_0
 SG_ Actuation_errors : 42|1@1+ (1,0) [0|0] ""  BMU_ID_0
 SG_ Auto_OFF : 43|1@1+ (1,0) [0|0] ""  BMU_ID_0
 SG_ Mode_mismatch : 44|1@1+ (1,0) [0|0] ""  BMU_ID_0
 SG_ Open_wire_errors : 45|1@1+ (1,0) [0|0] ""  BMU_ID_0
 SG_ Output_driver_errors_diagnostics : 46|1@1+ (1,0) [0|0] ""  BMU_ID_0
 SG_ User_forced_errors : 47|1@1+ (1,0) [0|0] ""  BMU_ID_0
 SG_ SD_error : 48|1@1+ (1,0) [0|0] ""  BMU_ID_0
 SG_ Ethernet_module_error : 49|1@1+ (1,0) [0|0] ""  BMU_ID_0
 SG_ Internal_memory_errors : 29|1@1+ (1,0) [0|0] ""  BMU_ID_0

BO_ 1337 wBMU_ID_9_msg_03_errors: 8 BMU_ID_9
 SG_ System_errors : 0|1@1+ (1,0) [0|0] ""  BMU_ID_0
 SG_ Architecture_configuration_error : 1|1@1+ (1,0) [0|0] ""  BMU_ID_0
 SG_ Parallelization_voltage_errors : 2|1@1+ (1,0) [0|0] ""  BMU_ID_0
 SG_ General_configuration_errors : 3|1@1+ (1,0) [0|0] ""  BMU_ID_0
 SG_ Parallelization_comm_lost_primar : 4|1@1+ (1,0) [0|0] ""  BMU_ID_0
 SG_ Cell_overvoltage : 5|1@1+ (1,0) [0|0] ""  BMU_ID_0
 SG_ Cell_undervoltage : 6|1@1+ (1,0) [0|0] ""  BMU_ID_0
 SG_ Comm_failure_with_CMU : 7|1@1+ (1,0) [0|0] ""  BMU_ID_0
 SG_ Internal_CMU_error : 8|1@1+ (1,0) [0|0] ""  BMU_ID_0
 SG_ Internal_CMU_temperature_error : 9|1@1+ (1,0) [0|0] ""  BMU_ID_0
 SG_ Internal_CMU_voltage_reference : 10|1@1+ (1,0) [0|0] ""  BMU_ID_0
 SG_ Cell_shortcircuit : 11|1@1+ (1,0) [0|0] ""  BMU_ID_0
 SG_ Battery_overcurrent : 12|1@1+ (1,0) [0|0] ""  BMU_ID_0
 SG_ Overload_ratio_exceeded : 13|1@1+ (1,0) [0|0] ""  BMU_ID_0
 SG_ Current_sensor_errors : 14|1@1+ (1,0) [0|0] ""  BMU_ID_0
 SG_ BMU_temperature_errors : 15|1@1+ (1,0) [0|0] ""  BMU_ID_0
 SG_ Cell_overtemperature : 16|1@1+ (1,0) [0|0] ""  BMU_ID_0
 SG_ Cell_undertemperature : 17|1@1+ (1,0) [0|0] ""  BMU_ID_0
 SG_ Balancing_overtemperature : 18|1@1+ (1,0) [0|0] ""  BMU_ID_0
 SG_ Balancing_undertemperature : 19|1@1+ (1,0) [0|0] ""  BMU_ID_0
 SG_ Max_op_cell_temp_delta : 20|1@1+ (1,0) [0|0] ""  BMU_ID_0
 SG_ Thermal_runaway : 21|1@1+ (1,0) [0|0] ""  BMU_ID_0
 SG_ OW_and_SC_detected_on_cell : 22|1@1+ (1,0) [0|0] ""  BMU_ID_0
 SG_ BMU_external_overtemperature : 23|1@1+ (1,0) [0|0] ""  BMU_ID_0
 SG_ Battery_undervoltage : 24|1@1+ (1,0) [0|0] ""  BMU_ID_0
 SG_ BMU_supply_voltage_error : 25|1@1+ (1,0) [0|0] ""  BMU_ID_0
 SG_ Battery_overvoltage : 26|1@1+ (1,0) [0|0] ""  BMU_ID_0
 SG_ Cells_unbalanced : 27|1@1+ (1,0) [0|0] ""  BMU_ID_0
 SG_ Advanced_relaxation_voltage_delt : 28|1@1+ (1,0) [0|0] ""  BMU_ID_0
 SG_ Internal_BMU_error : 30|1@1+ (1,0) [0|0] ""  BMU_ID_0
 SG_ Safety_sensor_error : 31|1@1+ (1,0) [0|0] ""  BMU_ID_0
 SG_ High_voltage_sensor_errors : 32|1@1+ (1,0) [0|0] ""  BMU_ID_0
 SG_ IMD_errors : 33|1@1+ (1,0) [0|0] ""  BMU_ID_0
 SG_ Isolation_error : 34|1@1+ (1,0) [0|0] ""  BMU_ID_0
 SG_ BMU_SoC_errors : 35|1@1+ (1,0) [0|0] ""  BMU_ID_0
 SG_ BMU_SoH_error : 36|1@1+ (1,0) [0|0] ""  BMU_ID_0
 SG_ Contactor_stuck_open_errors : 37|1@1+ (1,0) [0|0] ""  BMU_ID_0
 SG_ Contactor_stuck_closed_errors : 38|1@1+ (1,0) [0|0] ""  BMU_ID_0
 SG_ Contactor_supply_error : 39|1@1+ (1,0) [0|0] ""  BMU_ID_0
 SG_ Contactor_precharge_error : 40|1@1+ (1,0) [0|0] ""  BMU_ID_0
 SG_ Emergency_button_error : 41|1@1+ (1,0) [0|0] ""  BMU_ID_0
 SG_ Actuation_errors : 42|1@1+ (1,0) [0|0] ""  BMU_ID_0
 SG_ Auto_OFF : 43|1@1+ (1,0) [0|0] ""  BMU_ID_0
 SG_ Mode_mismatch : 44|1@1+ (1,0) [0|0] ""  BMU_ID_0
 SG_ Open_wire_errors : 45|1@1+ (1,0) [0|0] ""  BMU_ID_0
 SG_ Output_driver_errors_diagnostics : 46|1@1+ (1,0) [0|0] ""  BMU_ID_0
 SG_ User_forced_errors : 47|1@1+ (1,0) [0|0] ""  BMU_ID_0
 SG_ SD_error : 48|1@1+ (1,0) [0|0] ""  BMU_ID_0
 SG_ Ethernet_module_error : 49|1@1+ (1,0) [0|0] ""  BMU_ID_0
 SG_ Internal_memory_errors : 29|1@1+ (1,0) [0|0] ""  BMU_ID_0

BO_ 1338 wBMU_ID_10_msg_03_errors: 8 BMU_ID_10
 SG_ System_errors : 0|1@1+ (1,0) [0|0] ""  BMU_ID_0
 SG_ Architecture_configuration_error : 1|1@1+ (1,0) [0|0] ""  BMU_ID_0
 SG_ Parallelization_voltage_errors : 2|1@1+ (1,0) [0|0] ""  BMU_ID_0
 SG_ General_configuration_errors : 3|1@1+ (1,0) [0|0] ""  BMU_ID_0
 SG_ Parallelization_comm_lost_primar : 4|1@1+ (1,0) [0|0] ""  BMU_ID_0
 SG_ Cell_overvoltage : 5|1@1+ (1,0) [0|0] ""  BMU_ID_0
 SG_ Cell_undervoltage : 6|1@1+ (1,0) [0|0] ""  BMU_ID_0
 SG_ Comm_failure_with_CMU : 7|1@1+ (1,0) [0|0] ""  BMU_ID_0
 SG_ Internal_CMU_error : 8|1@1+ (1,0) [0|0] ""  BMU_ID_0
 SG_ Internal_CMU_temperature_error : 9|1@1+ (1,0) [0|0] ""  BMU_ID_0
 SG_ Internal_CMU_voltage_reference : 10|1@1+ (1,0) [0|0] ""  BMU_ID_0
 SG_ Cell_shortcircuit : 11|1@1+ (1,0) [0|0] ""  BMU_ID_0
 SG_ Battery_overcurrent : 12|1@1+ (1,0) [0|0] ""  BMU_ID_0
 SG_ Overload_ratio_exceeded : 13|1@1+ (1,0) [0|0] ""  BMU_ID_0
 SG_ Current_sensor_errors : 14|1@1+ (1,0) [0|0] ""  BMU_ID_0
 SG_ BMU_temperature_errors : 15|1@1+ (1,0) [0|0] ""  BMU_ID_0
 SG_ Cell_overtemperature : 16|1@1+ (1,0) [0|0] ""  BMU_ID_0
 SG_ Cell_undertemperature : 17|1@1+ (1,0) [0|0] ""  BMU_ID_0
 SG_ Balancing_overtemperature : 18|1@1+ (1,0) [0|0] ""  BMU_ID_0
 SG_ Balancing_undertemperature : 19|1@1+ (1,0) [0|0] ""  BMU_ID_0
 SG_ Max_op_cell_temp_delta : 20|1@1+ (1,0) [0|0] ""  BMU_ID_0
 SG_ Thermal_runaway : 21|1@1+ (1,0) [0|0] ""  BMU_ID_0
 SG_ OW_and_SC_detected_on_cell : 22|1@1+ (1,0) [0|0] ""  BMU_ID_0
 SG_ BMU_external_overtemperature : 23|1@1+ (1,0) [0|0] ""  BMU_ID_0
 SG_ Battery_undervoltage : 24|1@1+ (1,0) [0|0] ""  BMU_ID_0
 SG_ BMU_supply_voltage_error : 25|1@1+ (1,0) [0|0] ""  BMU_ID_0
 SG_ Battery_overvoltage : 26|1@1+ (1,0) [0|0] ""  BMU_ID_0
 SG_ Cells_unbalanced : 27|1@1+ (1,0) [0|0] ""  BMU_ID_0
 SG_ Advanced_relaxation_voltage_delt : 28|1@1+ (1,0) [0|0] ""  BMU_ID_0
 SG_ Internal_BMU_error : 30|1@1+ (1,0) [0|0] ""  BMU_ID_0
 SG_ Safety_sensor_error : 31|1@1+ (1,0) [0|0] ""  BMU_ID_0
 SG_ High_voltage_sensor_errors : 32|1@1+ (1,0) [0|0] ""  BMU_ID_0
 SG_ IMD_errors : 33|1@1+ (1,0) [0|0] ""  BMU_ID_0
 SG_ Isolation_error : 34|1@1+ (1,0) [0|0] ""  BMU_ID_0
 SG_ BMU_SoC_errors : 35|1@1+ (1,0) [0|0] ""  BMU_ID_0
 SG_ BMU_SoH_error : 36|1@1+ (1,0) [0|0] ""  BMU_ID_0
 SG_ Contactor_stuck_open_errors : 37|1@1+ (1,0) [0|0] ""  BMU_ID_0
 SG_ Contactor_stuck_closed_errors : 38|1@1+ (1,0) [0|0] ""  BMU_ID_0
 SG_ Contactor_supply_error : 39|1@1+ (1,0) [0|0] ""  BMU_ID_0
 SG_ Contactor_precharge_error : 40|1@1+ (1,0) [0|0] ""  BMU_ID_0
 SG_ Emergency_button_error : 41|1@1+ (1,0) [0|0] ""  BMU_ID_0
 SG_ Actuation_errors : 42|1@1+ (1,0) [0|0] ""  BMU_ID_0
 SG_ Auto_OFF : 43|1@1+ (1,0) [0|0] ""  BMU_ID_0
 SG_ Mode_mismatch : 44|1@1+ (1,0) [0|0] ""  BMU_ID_0
 SG_ Open_wire_errors : 45|1@1+ (1,0) [0|0] ""  BMU_ID_0
 SG_ Output_driver_errors_diagnostics : 46|1@1+ (1,0) [0|0] ""  BMU_ID_0
 SG_ User_forced_errors : 47|1@1+ (1,0) [0|0] ""  BMU_ID_0
 SG_ SD_error : 48|1@1+ (1,0) [0|0] ""  BMU_ID_0
 SG_ Ethernet_module_error : 49|1@1+ (1,0) [0|0] ""  BMU_ID_0
 SG_ Internal_memory_errors : 29|1@1+ (1,0) [0|0] ""  BMU_ID_0

BO_ 1339 wBMU_ID_11_msg_03_errors: 8 BMU_ID_11
 SG_ System_errors : 0|1@1+ (1,0) [0|0] ""  BMU_ID_0
 SG_ Architecture_configuration_error : 1|1@1+ (1,0) [0|0] ""  BMU_ID_0
 SG_ Parallelization_voltage_errors : 2|1@1+ (1,0) [0|0] ""  BMU_ID_0
 SG_ General_configuration_errors : 3|1@1+ (1,0) [0|0] ""  BMU_ID_0
 SG_ Parallelization_comm_lost_primar : 4|1@1+ (1,0) [0|0] ""  BMU_ID_0
 SG_ Cell_overvoltage : 5|1@1+ (1,0) [0|0] ""  BMU_ID_0
 SG_ Cell_undervoltage : 6|1@1+ (1,0) [0|0] ""  BMU_ID_0
 SG_ Comm_failure_with_CMU : 7|1@1+ (1,0) [0|0] ""  BMU_ID_0
 SG_ Internal_CMU_error : 8|1@1+ (1,0) [0|0] ""  BMU_ID_0
 SG_ Internal_CMU_temperature_error : 9|1@1+ (1,0) [0|0] ""  BMU_ID_0
 SG_ Internal_CMU_voltage_reference : 10|1@1+ (1,0) [0|0] ""  BMU_ID_0
 SG_ Cell_shortcircuit : 11|1@1+ (1,0) [0|0] ""  BMU_ID_0
 SG_ Battery_overcurrent : 12|1@1+ (1,0) [0|0] ""  BMU_ID_0
 SG_ Overload_ratio_exceeded : 13|1@1+ (1,0) [0|0] ""  BMU_ID_0
 SG_ Current_sensor_errors : 14|1@1+ (1,0) [0|0] ""  BMU_ID_0
 SG_ BMU_temperature_errors : 15|1@1+ (1,0) [0|0] ""  BMU_ID_0
 SG_ Cell_overtemperature : 16|1@1+ (1,0) [0|0] ""  BMU_ID_0
 SG_ Cell_undertemperature : 17|1@1+ (1,0) [0|0] ""  BMU_ID_0
 SG_ Balancing_overtemperature : 18|1@1+ (1,0) [0|0] ""  BMU_ID_0
 SG_ Balancing_undertemperature : 19|1@1+ (1,0) [0|0] ""  BMU_ID_0
 SG_ Max_op_cell_temp_delta : 20|1@1+ (1,0) [0|0] ""  BMU_ID_0
 SG_ Thermal_runaway : 21|1@1+ (1,0) [0|0] ""  BMU_ID_0
 SG_ OW_and_SC_detected_on_cell : 22|1@1+ (1,0) [0|0] ""  BMU_ID_0
 SG_ BMU_external_overtemperature : 23|1@1+ (1,0) [0|0] ""  BMU_ID_0
 SG_ Battery_undervoltage : 24|1@1+ (1,0) [0|0] ""  BMU_ID_0
 SG_ BMU_supply_voltage_error : 25|1@1+ (1,0) [0|0] ""  BMU_ID_0
 SG_ Battery_overvoltage : 26|1@1+ (1,0) [0|0] ""  BMU_ID_0
 SG_ Cells_unbalanced : 27|1@1+ (1,0) [0|0] ""  BMU_ID_0
 SG_ Advanced_relaxation_voltage_delt : 28|1@1+ (1,0) [0|0] ""  BMU_ID_0
 SG_ Internal_BMU_error : 30|1@1+ (1,0) [0|0] ""  BMU_ID_0
 SG_ Safety_sensor_error : 31|1@1+ (1,0) [0|0] ""  BMU_ID_0
 SG_ High_voltage_sensor_errors : 32|1@1+ (1,0) [0|0] ""  BMU_ID_0
 SG_ IMD_errors : 33|1@1+ (1,0) [0|0] ""  BMU_ID_0
 SG_ Isolation_error : 34|1@1+ (1,0) [0|0] ""  BMU_ID_0
 SG_ BMU_SoC_errors : 35|1@1+ (1,0) [0|0] ""  BMU_ID_0
 SG_ BMU_SoH_error : 36|1@1+ (1,0) [0|0] ""  BMU_ID_0
 SG_ Contactor_stuck_open_errors : 37|1@1+ (1,0) [0|0] ""  BMU_ID_0
 SG_ Contactor_stuck_closed_errors : 38|1@1+ (1,0) [0|0] ""  BMU_ID_0
 SG_ Contactor_supply_error : 39|1@1+ (1,0) [0|0] ""  BMU_ID_0
 SG_ Contactor_precharge_error : 40|1@1+ (1,0) [0|0] ""  BMU_ID_0
 SG_ Emergency_button_error : 41|1@1+ (1,0) [0|0] ""  BMU_ID_0
 SG_ Actuation_errors : 42|1@1+ (1,0) [0|0] ""  BMU_ID_0
 SG_ Auto_OFF : 43|1@1+ (1,0) [0|0] ""  BMU_ID_0
 SG_ Mode_mismatch : 44|1@1+ (1,0) [0|0] ""  BMU_ID_0
 SG_ Open_wire_errors : 45|1@1+ (1,0) [0|0] ""  BMU_ID_0
 SG_ Output_driver_errors_diagnostics : 46|1@1+ (1,0) [0|0] ""  BMU_ID_0
 SG_ User_forced_errors : 47|1@1+ (1,0) [0|0] ""  BMU_ID_0
 SG_ SD_error : 48|1@1+ (1,0) [0|0] ""  BMU_ID_0
 SG_ Ethernet_module_error : 49|1@1+ (1,0) [0|0] ""  BMU_ID_0
 SG_ Internal_memory_errors : 29|1@1+ (1,0) [0|0] ""  BMU_ID_0

BO_ 1340 wBMU_ID_12_msg_03_errors: 8 BMU_ID_12
 SG_ System_errors : 0|1@1+ (1,0) [0|0] ""  BMU_ID_0
 SG_ Architecture_configuration_error : 1|1@1+ (1,0) [0|0] ""  BMU_ID_0
 SG_ Parallelization_voltage_errors : 2|1@1+ (1,0) [0|0] ""  BMU_ID_0
 SG_ General_configuration_errors : 3|1@1+ (1,0) [0|0] ""  BMU_ID_0
 SG_ Parallelization_comm_lost_primar : 4|1@1+ (1,0) [0|0] ""  BMU_ID_0
 SG_ Cell_overvoltage : 5|1@1+ (1,0) [0|0] ""  BMU_ID_0
 SG_ Cell_undervoltage : 6|1@1+ (1,0) [0|0] ""  BMU_ID_0
 SG_ Comm_failure_with_CMU : 7|1@1+ (1,0) [0|0] ""  BMU_ID_0
 SG_ Internal_CMU_error : 8|1@1+ (1,0) [0|0] ""  BMU_ID_0
 SG_ Internal_CMU_temperature_error : 9|1@1+ (1,0) [0|0] ""  BMU_ID_0
 SG_ Internal_CMU_voltage_reference : 10|1@1+ (1,0) [0|0] ""  BMU_ID_0
 SG_ Cell_shortcircuit : 11|1@1+ (1,0) [0|0] ""  BMU_ID_0
 SG_ Battery_overcurrent : 12|1@1+ (1,0) [0|0] ""  BMU_ID_0
 SG_ Overload_ratio_exceeded : 13|1@1+ (1,0) [0|0] ""  BMU_ID_0
 SG_ Current_sensor_errors : 14|1@1+ (1,0) [0|0] ""  BMU_ID_0
 SG_ BMU_temperature_errors : 15|1@1+ (1,0) [0|0] ""  BMU_ID_0
 SG_ Cell_overtemperature : 16|1@1+ (1,0) [0|0] ""  BMU_ID_0
 SG_ Cell_undertemperature : 17|1@1+ (1,0) [0|0] ""  BMU_ID_0
 SG_ Balancing_overtemperature : 18|1@1+ (1,0) [0|0] ""  BMU_ID_0
 SG_ Balancing_undertemperature : 19|1@1+ (1,0) [0|0] ""  BMU_ID_0
 SG_ Max_op_cell_temp_delta : 20|1@1+ (1,0) [0|0] ""  BMU_ID_0
 SG_ Thermal_runaway : 21|1@1+ (1,0) [0|0] ""  BMU_ID_0
 SG_ OW_and_SC_detected_on_cell : 22|1@1+ (1,0) [0|0] ""  BMU_ID_0
 SG_ BMU_external_overtemperature : 23|1@1+ (1,0) [0|0] ""  BMU_ID_0
 SG_ Battery_undervoltage : 24|1@1+ (1,0) [0|0] ""  BMU_ID_0
 SG_ BMU_supply_voltage_error : 25|1@1+ (1,0) [0|0] ""  BMU_ID_0
 SG_ Battery_overvoltage : 26|1@1+ (1,0) [0|0] ""  BMU_ID_0
 SG_ Cells_unbalanced : 27|1@1+ (1,0) [0|0] ""  BMU_ID_0
 SG_ Advanced_relaxation_voltage_delt : 28|1@1+ (1,0) [0|0] ""  BMU_ID_0
 SG_ Internal_BMU_error : 30|1@1+ (1,0) [0|0] ""  BMU_ID_0
 SG_ Safety_sensor_error : 31|1@1+ (1,0) [0|0] ""  BMU_ID_0
 SG_ High_voltage_sensor_errors : 32|1@1+ (1,0) [0|0] ""  BMU_ID_0
 SG_ IMD_errors : 33|1@1+ (1,0) [0|0] ""  BMU_ID_0
 SG_ Isolation_error : 34|1@1+ (1,0) [0|0] ""  BMU_ID_0
 SG_ BMU_SoC_errors : 35|1@1+ (1,0) [0|0] ""  BMU_ID_0
 SG_ BMU_SoH_error : 36|1@1+ (1,0) [0|0] ""  BMU_ID_0
 SG_ Contactor_stuck_open_errors : 37|1@1+ (1,0) [0|0] ""  BMU_ID_0
 SG_ Contactor_stuck_closed_errors : 38|1@1+ (1,0) [0|0] ""  BMU_ID_0
 SG_ Contactor_supply_error : 39|1@1+ (1,0) [0|0] ""  BMU_ID_0
 SG_ Contactor_precharge_error : 40|1@1+ (1,0) [0|0] ""  BMU_ID_0
 SG_ Emergency_button_error : 41|1@1+ (1,0) [0|0] ""  BMU_ID_0
 SG_ Actuation_errors : 42|1@1+ (1,0) [0|0] ""  BMU_ID_0
 SG_ Auto_OFF : 43|1@1+ (1,0) [0|0] ""  BMU_ID_0
 SG_ Mode_mismatch : 44|1@1+ (1,0) [0|0] ""  BMU_ID_0
 SG_ Open_wire_errors : 45|1@1+ (1,0) [0|0] ""  BMU_ID_0
 SG_ Output_driver_errors_diagnostics : 46|1@1+ (1,0) [0|0] ""  BMU_ID_0
 SG_ User_forced_errors : 47|1@1+ (1,0) [0|0] ""  BMU_ID_0
 SG_ SD_error : 48|1@1+ (1,0) [0|0] ""  BMU_ID_0
 SG_ Ethernet_module_error : 49|1@1+ (1,0) [0|0] ""  BMU_ID_0
 SG_ Internal_memory_errors : 29|1@1+ (1,0) [0|0] ""  BMU_ID_0

BO_ 1341 wBMU_ID_13_msg_03_errors: 8 BMU_ID_13
 SG_ System_errors : 0|1@1+ (1,0) [0|0] ""  BMU_ID_0
 SG_ Architecture_configuration_error : 1|1@1+ (1,0) [0|0] ""  BMU_ID_0
 SG_ Parallelization_voltage_errors : 2|1@1+ (1,0) [0|0] ""  BMU_ID_0
 SG_ General_configuration_errors : 3|1@1+ (1,0) [0|0] ""  BMU_ID_0
 SG_ Parallelization_comm_lost_primar : 4|1@1+ (1,0) [0|0] ""  BMU_ID_0
 SG_ Cell_overvoltage : 5|1@1+ (1,0) [0|0] ""  BMU_ID_0
 SG_ Cell_undervoltage : 6|1@1+ (1,0) [0|0] ""  BMU_ID_0
 SG_ Comm_failure_with_CMU : 7|1@1+ (1,0) [0|0] ""  BMU_ID_0
 SG_ Internal_CMU_error : 8|1@1+ (1,0) [0|0] ""  BMU_ID_0
 SG_ Internal_CMU_temperature_error : 9|1@1+ (1,0) [0|0] ""  BMU_ID_0
 SG_ Internal_CMU_voltage_reference : 10|1@1+ (1,0) [0|0] ""  BMU_ID_0
 SG_ Cell_shortcircuit : 11|1@1+ (1,0) [0|0] ""  BMU_ID_0
 SG_ Battery_overcurrent : 12|1@1+ (1,0) [0|0] ""  BMU_ID_0
 SG_ Overload_ratio_exceeded : 13|1@1+ (1,0) [0|0] ""  BMU_ID_0
 SG_ Current_sensor_errors : 14|1@1+ (1,0) [0|0] ""  BMU_ID_0
 SG_ BMU_temperature_errors : 15|1@1+ (1,0) [0|0] ""  BMU_ID_0
 SG_ Cell_overtemperature : 16|1@1+ (1,0) [0|0] ""  BMU_ID_0
 SG_ Cell_undertemperature : 17|1@1+ (1,0) [0|0] ""  BMU_ID_0
 SG_ Balancing_overtemperature : 18|1@1+ (1,0) [0|0] ""  BMU_ID_0
 SG_ Balancing_undertemperature : 19|1@1+ (1,0) [0|0] ""  BMU_ID_0
 SG_ Max_op_cell_temp_delta : 20|1@1+ (1,0) [0|0] ""  BMU_ID_0
 SG_ Thermal_runaway : 21|1@1+ (1,0) [0|0] ""  BMU_ID_0
 SG_ OW_and_SC_detected_on_cell : 22|1@1+ (1,0) [0|0] ""  BMU_ID_0
 SG_ BMU_external_overtemperature : 23|1@1+ (1,0) [0|0] ""  BMU_ID_0
 SG_ Battery_undervoltage : 24|1@1+ (1,0) [0|0] ""  BMU_ID_0
 SG_ BMU_supply_voltage_error : 25|1@1+ (1,0) [0|0] ""  BMU_ID_0
 SG_ Battery_overvoltage : 26|1@1+ (1,0) [0|0] ""  BMU_ID_0
 SG_ Cells_unbalanced : 27|1@1+ (1,0) [0|0] ""  BMU_ID_0
 SG_ Advanced_relaxation_voltage_delt : 28|1@1+ (1,0) [0|0] ""  BMU_ID_0
 SG_ Internal_BMU_error : 30|1@1+ (1,0) [0|0] ""  BMU_ID_0
 SG_ Safety_sensor_error : 31|1@1+ (1,0) [0|0] ""  BMU_ID_0
 SG_ High_voltage_sensor_errors : 32|1@1+ (1,0) [0|0] ""  BMU_ID_0
 SG_ IMD_errors : 33|1@1+ (1,0) [0|0] ""  BMU_ID_0
 SG_ Isolation_error : 34|1@1+ (1,0) [0|0] ""  BMU_ID_0
 SG_ BMU_SoC_errors : 35|1@1+ (1,0) [0|0] ""  BMU_ID_0
 SG_ BMU_SoH_error : 36|1@1+ (1,0) [0|0] ""  BMU_ID_0
 SG_ Contactor_stuck_open_errors : 37|1@1+ (1,0) [0|0] ""  BMU_ID_0
 SG_ Contactor_stuck_closed_errors : 38|1@1+ (1,0) [0|0] ""  BMU_ID_0
 SG_ Contactor_supply_error : 39|1@1+ (1,0) [0|0] ""  BMU_ID_0
 SG_ Contactor_precharge_error : 40|1@1+ (1,0) [0|0] ""  BMU_ID_0
 SG_ Emergency_button_error : 41|1@1+ (1,0) [0|0] ""  BMU_ID_0
 SG_ Actuation_errors : 42|1@1+ (1,0) [0|0] ""  BMU_ID_0
 SG_ Auto_OFF : 43|1@1+ (1,0) [0|0] ""  BMU_ID_0
 SG_ Mode_mismatch : 44|1@1+ (1,0) [0|0] ""  BMU_ID_0
 SG_ Open_wire_errors : 45|1@1+ (1,0) [0|0] ""  BMU_ID_0
 SG_ Output_driver_errors_diagnostics : 46|1@1+ (1,0) [0|0] ""  BMU_ID_0
 SG_ User_forced_errors : 47|1@1+ (1,0) [0|0] ""  BMU_ID_0
 SG_ SD_error : 48|1@1+ (1,0) [0|0] ""  BMU_ID_0
 SG_ Ethernet_module_error : 49|1@1+ (1,0) [0|0] ""  BMU_ID_0
 SG_ Internal_memory_errors : 29|1@1+ (1,0) [0|0] ""  BMU_ID_0

BO_ 1342 wBMU_ID_14_msg_03_errors: 8 BMU_ID_14
 SG_ System_errors : 0|1@1+ (1,0) [0|0] ""  BMU_ID_0
 SG_ Architecture_configuration_error : 1|1@1+ (1,0) [0|0] ""  BMU_ID_0
 SG_ Parallelization_voltage_errors : 2|1@1+ (1,0) [0|0] ""  BMU_ID_0
 SG_ General_configuration_errors : 3|1@1+ (1,0) [0|0] ""  BMU_ID_0
 SG_ Parallelization_comm_lost_primar : 4|1@1+ (1,0) [0|0] ""  BMU_ID_0
 SG_ Cell_overvoltage : 5|1@1+ (1,0) [0|0] ""  BMU_ID_0
 SG_ Cell_undervoltage : 6|1@1+ (1,0) [0|0] ""  BMU_ID_0
 SG_ Comm_failure_with_CMU : 7|1@1+ (1,0) [0|0] ""  BMU_ID_0
 SG_ Internal_CMU_error : 8|1@1+ (1,0) [0|0] ""  BMU_ID_0
 SG_ Internal_CMU_temperature_error : 9|1@1+ (1,0) [0|0] ""  BMU_ID_0
 SG_ Internal_CMU_voltage_reference : 10|1@1+ (1,0) [0|0] ""  BMU_ID_0
 SG_ Cell_shortcircuit : 11|1@1+ (1,0) [0|0] ""  BMU_ID_0
 SG_ Battery_overcurrent : 12|1@1+ (1,0) [0|0] ""  BMU_ID_0
 SG_ Overload_ratio_exceeded : 13|1@1+ (1,0) [0|0] ""  BMU_ID_0
 SG_ Current_sensor_errors : 14|1@1+ (1,0) [0|0] ""  BMU_ID_0
 SG_ BMU_temperature_errors : 15|1@1+ (1,0) [0|0] ""  BMU_ID_0
 SG_ Cell_overtemperature : 16|1@1+ (1,0) [0|0] ""  BMU_ID_0
 SG_ Cell_undertemperature : 17|1@1+ (1,0) [0|0] ""  BMU_ID_0
 SG_ Balancing_overtemperature : 18|1@1+ (1,0) [0|0] ""  BMU_ID_0
 SG_ Balancing_undertemperature : 19|1@1+ (1,0) [0|0] ""  BMU_ID_0
 SG_ Max_op_cell_temp_delta : 20|1@1+ (1,0) [0|0] ""  BMU_ID_0
 SG_ Thermal_runaway : 21|1@1+ (1,0) [0|0] ""  BMU_ID_0
 SG_ OW_and_SC_detected_on_cell : 22|1@1+ (1,0) [0|0] ""  BMU_ID_0
 SG_ BMU_external_overtemperature : 23|1@1+ (1,0) [0|0] ""  BMU_ID_0
 SG_ Battery_undervoltage : 24|1@1+ (1,0) [0|0] ""  BMU_ID_0
 SG_ BMU_supply_voltage_error : 25|1@1+ (1,0) [0|0] ""  BMU_ID_0
 SG_ Battery_overvoltage : 26|1@1+ (1,0) [0|0] ""  BMU_ID_0
 SG_ Cells_unbalanced : 27|1@1+ (1,0) [0|0] ""  BMU_ID_0
 SG_ Advanced_relaxation_voltage_delt : 28|1@1+ (1,0) [0|0] ""  BMU_ID_0
 SG_ Internal_BMU_error : 30|1@1+ (1,0) [0|0] ""  BMU_ID_0
 SG_ Safety_sensor_error : 31|1@1+ (1,0) [0|0] ""  BMU_ID_0
 SG_ High_voltage_sensor_errors : 32|1@1+ (1,0) [0|0] ""  BMU_ID_0
 SG_ IMD_errors : 33|1@1+ (1,0) [0|0] ""  BMU_ID_0
 SG_ Isolation_error : 34|1@1+ (1,0) [0|0] ""  BMU_ID_0
 SG_ BMU_SoC_errors : 35|1@1+ (1,0) [0|0] ""  BMU_ID_0
 SG_ BMU_SoH_error : 36|1@1+ (1,0) [0|0] ""  BMU_ID_0
 SG_ Contactor_stuck_open_errors : 37|1@1+ (1,0) [0|0] ""  BMU_ID_0
 SG_ Contactor_stuck_closed_errors : 38|1@1+ (1,0) [0|0] ""  BMU_ID_0
 SG_ Contactor_supply_error : 39|1@1+ (1,0) [0|0] ""  BMU_ID_0
 SG_ Contactor_precharge_error : 40|1@1+ (1,0) [0|0] ""  BMU_ID_0
 SG_ Emergency_button_error : 41|1@1+ (1,0) [0|0] ""  BMU_ID_0
 SG_ Actuation_errors : 42|1@1+ (1,0) [0|0] ""  BMU_ID_0
 SG_ Auto_OFF : 43|1@1+ (1,0) [0|0] ""  BMU_ID_0
 SG_ Mode_mismatch : 44|1@1+ (1,0) [0|0] ""  BMU_ID_0
 SG_ Open_wire_errors : 45|1@1+ (1,0) [0|0] ""  BMU_ID_0
 SG_ Output_driver_errors_diagnostics : 46|1@1+ (1,0) [0|0] ""  BMU_ID_0
 SG_ User_forced_errors : 47|1@1+ (1,0) [0|0] ""  BMU_ID_0
 SG_ SD_error : 48|1@1+ (1,0) [0|0] ""  BMU_ID_0
 SG_ Ethernet_module_error : 49|1@1+ (1,0) [0|0] ""  BMU_ID_0
 SG_ Internal_memory_errors : 29|1@1+ (1,0) [0|0] ""  BMU_ID_0

BO_ 1343 wBMU_ID_15_msg_03_errors: 8 BMU_ID_15
 SG_ System_errors : 0|1@1+ (1,0) [0|0] ""  BMU_ID_0
 SG_ Architecture_configuration_error : 1|1@1+ (1,0) [0|0] ""  BMU_ID_0
 SG_ Parallelization_voltage_errors : 2|1@1+ (1,0) [0|0] ""  BMU_ID_0
 SG_ General_configuration_errors : 3|1@1+ (1,0) [0|0] ""  BMU_ID_0
 SG_ Parallelization_comm_lost_primar : 4|1@1+ (1,0) [0|0] ""  BMU_ID_0
 SG_ Cell_overvoltage : 5|1@1+ (1,0) [0|0] ""  BMU_ID_0
 SG_ Cell_undervoltage : 6|1@1+ (1,0) [0|0] ""  BMU_ID_0
 SG_ Comm_failure_with_CMU : 7|1@1+ (1,0) [0|0] ""  BMU_ID_0
 SG_ Internal_CMU_error : 8|1@1+ (1,0) [0|0] ""  BMU_ID_0
 SG_ Internal_CMU_temperature_error : 9|1@1+ (1,0) [0|0] ""  BMU_ID_0
 SG_ Internal_CMU_voltage_reference : 10|1@1+ (1,0) [0|0] ""  BMU_ID_0
 SG_ Cell_shortcircuit : 11|1@1+ (1,0) [0|0] ""  BMU_ID_0
 SG_ Battery_overcurrent : 12|1@1+ (1,0) [0|0] ""  BMU_ID_0
 SG_ Overload_ratio_exceeded : 13|1@1+ (1,0) [0|0] ""  BMU_ID_0
 SG_ Current_sensor_errors : 14|1@1+ (1,0) [0|0] ""  BMU_ID_0
 SG_ BMU_temperature_errors : 15|1@1+ (1,0) [0|0] ""  BMU_ID_0
 SG_ Cell_overtemperature : 16|1@1+ (1,0) [0|0] ""  BMU_ID_0
 SG_ Cell_undertemperature : 17|1@1+ (1,0) [0|0] ""  BMU_ID_0
 SG_ Balancing_overtemperature : 18|1@1+ (1,0) [0|0] ""  BMU_ID_0
 SG_ Balancing_undertemperature : 19|1@1+ (1,0) [0|0] ""  BMU_ID_0
 SG_ Max_op_cell_temp_delta : 20|1@1+ (1,0) [0|0] ""  BMU_ID_0
 SG_ Thermal_runaway : 21|1@1+ (1,0) [0|0] ""  BMU_ID_0
 SG_ OW_and_SC_detected_on_cell : 22|1@1+ (1,0) [0|0] ""  BMU_ID_0
 SG_ BMU_external_overtemperature : 23|1@1+ (1,0) [0|0] ""  BMU_ID_0
 SG_ Battery_undervoltage : 24|1@1+ (1,0) [0|0] ""  BMU_ID_0
 SG_ BMU_supply_voltage_error : 25|1@1+ (1,0) [0|0] ""  BMU_ID_0
 SG_ Battery_overvoltage : 26|1@1+ (1,0) [0|0] ""  BMU_ID_0
 SG_ Cells_unbalanced : 27|1@1+ (1,0) [0|0] ""  BMU_ID_0
 SG_ Advanced_relaxation_voltage_delt : 28|1@1+ (1,0) [0|0] ""  BMU_ID_0
 SG_ Internal_BMU_error : 30|1@1+ (1,0) [0|0] ""  BMU_ID_0
 SG_ Safety_sensor_error : 31|1@1+ (1,0) [0|0] ""  BMU_ID_0
 SG_ High_voltage_sensor_errors : 32|1@1+ (1,0) [0|0] ""  BMU_ID_0
 SG_ IMD_errors : 33|1@1+ (1,0) [0|0] ""  BMU_ID_0
 SG_ Isolation_error : 34|1@1+ (1,0) [0|0] ""  BMU_ID_0
 SG_ BMU_SoC_errors : 35|1@1+ (1,0) [0|0] ""  BMU_ID_0
 SG_ BMU_SoH_error : 36|1@1+ (1,0) [0|0] ""  BMU_ID_0
 SG_ Contactor_stuck_open_errors : 37|1@1+ (1,0) [0|0] ""  BMU_ID_0
 SG_ Contactor_stuck_closed_errors : 38|1@1+ (1,0) [0|0] ""  BMU_ID_0
 SG_ Contactor_supply_error : 39|1@1+ (1,0) [0|0] ""  BMU_ID_0
 SG_ Contactor_precharge_error : 40|1@1+ (1,0) [0|0] ""  BMU_ID_0
 SG_ Emergency_button_error : 41|1@1+ (1,0) [0|0] ""  BMU_ID_0
 SG_ Actuation_errors : 42|1@1+ (1,0) [0|0] ""  BMU_ID_0
 SG_ Auto_OFF : 43|1@1+ (1,0) [0|0] ""  BMU_ID_0
 SG_ Mode_mismatch : 44|1@1+ (1,0) [0|0] ""  BMU_ID_0
 SG_ Open_wire_errors : 45|1@1+ (1,0) [0|0] ""  BMU_ID_0
 SG_ Output_driver_errors_diagnostics : 46|1@1+ (1,0) [0|0] ""  BMU_ID_0
 SG_ User_forced_errors : 47|1@1+ (1,0) [0|0] ""  BMU_ID_0
 SG_ SD_error : 48|1@1+ (1,0) [0|0] ""  BMU_ID_0
 SG_ Ethernet_module_error : 49|1@1+ (1,0) [0|0] ""  BMU_ID_0
 SG_ Internal_memory_errors : 29|1@1+ (1,0) [0|0] ""  BMU_ID_0

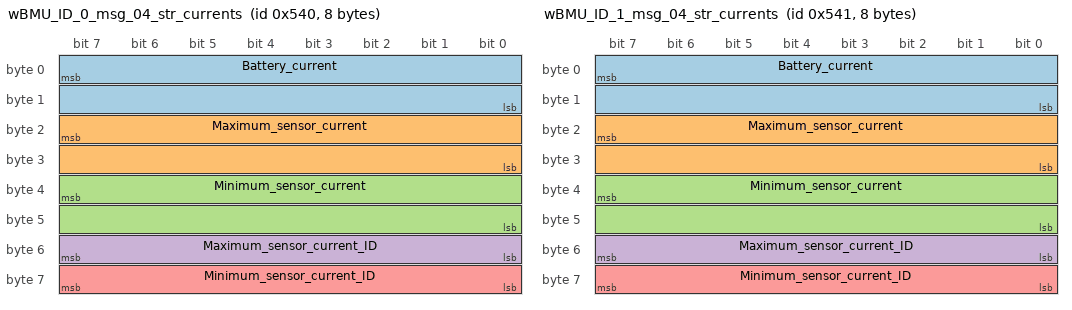
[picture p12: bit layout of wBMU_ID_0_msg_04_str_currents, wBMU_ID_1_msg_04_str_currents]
BO_ 1344 wBMU_ID_0_msg_04_str_currents: 8 BMU_ID_0
 SG_ Battery_current : 7|16@0+ (0.1,-3200) [0|0] "A"  BMU_ID_0
 SG_ Maximum_sensor_current : 23|16@0+ (0.1,-3200) [0|0] "A"  BMU_ID_0
 SG_ Minimum_sensor_current : 39|16@0+ (0.1,-3200) [0|0] "A"  BMU_ID_0
 SG_ Maximum_sensor_current_ID : 55|8@0+ (1,1) [0|0] "-"  BMU_ID_0
 SG_ Minimum_sensor_current_ID : 63|8@0+ (1,1) [0|0] "-"  BMU_ID_0

BO_ 1345 wBMU_ID_1_msg_04_str_currents: 8 BMU_ID_1
 SG_ Battery_current : 7|16@0+ (0.1,-3200) [0|0] "A"  BMU_ID_0
 SG_ Maximum_sensor_current : 23|16@0+ (0.1,-3200) [0|0] "A"  BMU_ID_0
 SG_ Minimum_sensor_current : 39|16@0+ (0.1,-3200) [0|0] "A"  BMU_ID_0
 SG_ Maximum_sensor_current_ID : 55|8@0+ (1,1) [0|0] "-"  BMU_ID_0
 SG_ Minimum_sensor_current_ID : 63|8@0+ (1,1) [0|0] "-"  BMU_ID_0

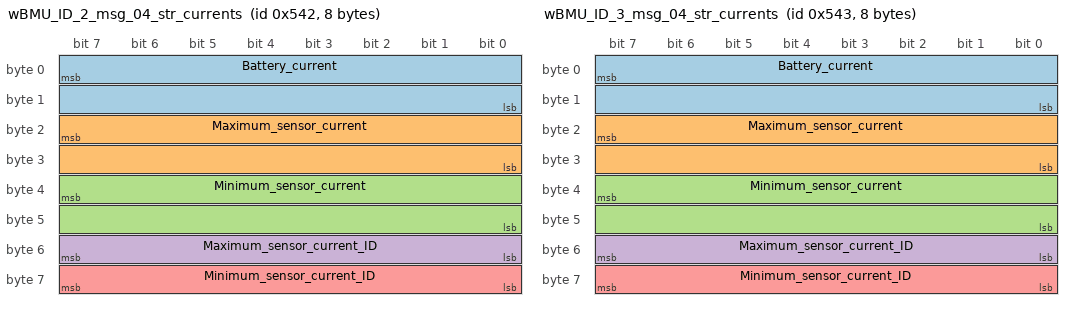
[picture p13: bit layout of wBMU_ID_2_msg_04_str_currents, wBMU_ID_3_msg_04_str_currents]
BO_ 1346 wBMU_ID_2_msg_04_str_currents: 8 BMU_ID_2
 SG_ Battery_current : 7|16@0+ (0.1,-3200) [0|0] "A"  BMU_ID_0
 SG_ Maximum_sensor_current : 23|16@0+ (0.1,-3200) [0|0] "A"  BMU_ID_0
 SG_ Minimum_sensor_current : 39|16@0+ (0.1,-3200) [0|0] "A"  BMU_ID_0
 SG_ Maximum_sensor_current_ID : 55|8@0+ (1,1) [0|0] "-"  BMU_ID_0
 SG_ Minimum_sensor_current_ID : 63|8@0+ (1,1) [0|0] "-"  BMU_ID_0

BO_ 1347 wBMU_ID_3_msg_04_str_currents: 8 BMU_ID_3
 SG_ Battery_current : 7|16@0+ (0.1,-3200) [0|0] "A"  BMU_ID_0
 SG_ Maximum_sensor_current : 23|16@0+ (0.1,-3200) [0|0] "A"  BMU_ID_0
 SG_ Minimum_sensor_current : 39|16@0+ (0.1,-3200) [0|0] "A"  BMU_ID_0
 SG_ Maximum_sensor_current_ID : 55|8@0+ (1,1) [0|0] "-"  BMU_ID_0
 SG_ Minimum_sensor_current_ID : 63|8@0+ (1,1) [0|0] "-"  BMU_ID_0

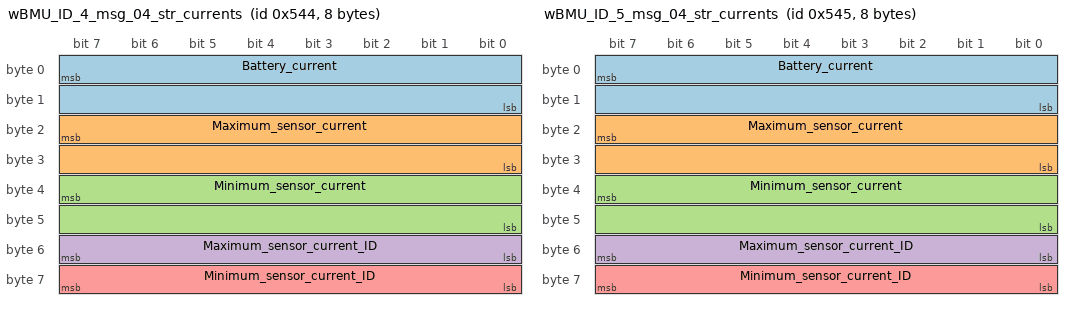
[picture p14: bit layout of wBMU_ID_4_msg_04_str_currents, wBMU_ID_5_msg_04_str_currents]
BO_ 1348 wBMU_ID_4_msg_04_str_currents: 8 BMU_ID_4
 SG_ Battery_current : 7|16@0+ (0.1,-3200) [0|0] "A"  BMU_ID_0
 SG_ Maximum_sensor_current : 23|16@0+ (0.1,-3200) [0|0] "A"  BMU_ID_0
 SG_ Minimum_sensor_current : 39|16@0+ (0.1,-3200) [0|0] "A"  BMU_ID_0
 SG_ Maximum_sensor_current_ID : 55|8@0+ (1,1) [0|0] "-"  BMU_ID_0
 SG_ Minimum_sensor_current_ID : 63|8@0+ (1,1) [0|0] "-"  BMU_ID_0

BO_ 1349 wBMU_ID_5_msg_04_str_currents: 8 BMU_ID_5
 SG_ Battery_current : 7|16@0+ (0.1,-3200) [0|0] "A"  BMU_ID_0
 SG_ Maximum_sensor_current : 23|16@0+ (0.1,-3200) [0|0] "A"  BMU_ID_0
 SG_ Minimum_sensor_current : 39|16@0+ (0.1,-3200) [0|0] "A"  BMU_ID_0
 SG_ Maximum_sensor_current_ID : 55|8@0+ (1,1) [0|0] "-"  BMU_ID_0
 SG_ Minimum_sensor_current_ID : 63|8@0+ (1,1) [0|0] "-"  BMU_ID_0

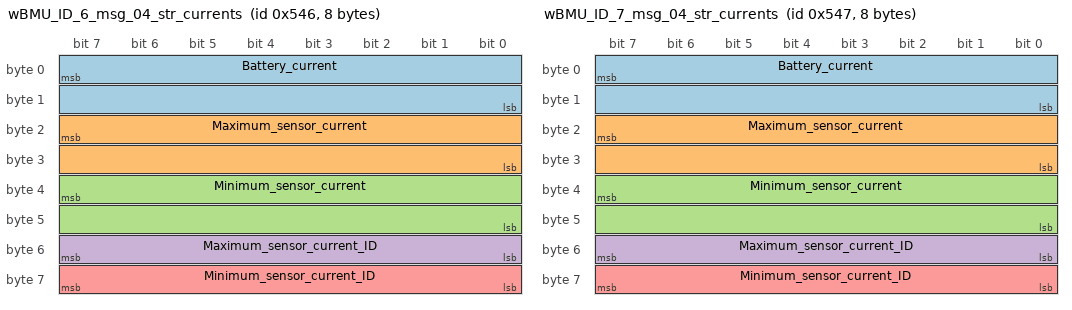
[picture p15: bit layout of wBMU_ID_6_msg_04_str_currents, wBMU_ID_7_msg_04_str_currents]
BO_ 1350 wBMU_ID_6_msg_04_str_currents: 8 BMU_ID_6
 SG_ Battery_current : 7|16@0+ (0.1,-3200) [0|0] "A"  BMU_ID_0
 SG_ Maximum_sensor_current : 23|16@0+ (0.1,-3200) [0|0] "A"  BMU_ID_0
 SG_ Minimum_sensor_current : 39|16@0+ (0.1,-3200) [0|0] "A"  BMU_ID_0
 SG_ Maximum_sensor_current_ID : 55|8@0+ (1,1) [0|0] "-"  BMU_ID_0
 SG_ Minimum_sensor_current_ID : 63|8@0+ (1,1) [0|0] "-"  BMU_ID_0

BO_ 1351 wBMU_ID_7_msg_04_str_currents: 8 BMU_ID_7
 SG_ Battery_current : 7|16@0+ (0.1,-3200) [0|0] "A"  BMU_ID_0
 SG_ Maximum_sensor_current : 23|16@0+ (0.1,-3200) [0|0] "A"  BMU_ID_0
 SG_ Minimum_sensor_current : 39|16@0+ (0.1,-3200) [0|0] "A"  BMU_ID_0
 SG_ Maximum_sensor_current_ID : 55|8@0+ (1,1) [0|0] "-"  BMU_ID_0
 SG_ Minimum_sensor_current_ID : 63|8@0+ (1,1) [0|0] "-"  BMU_ID_0

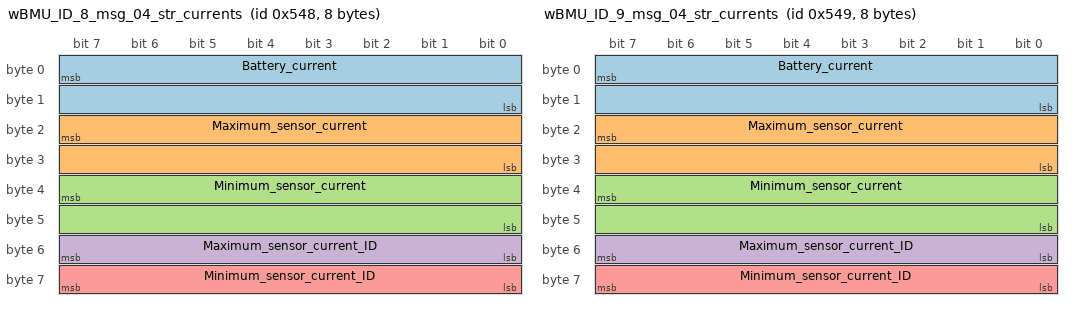
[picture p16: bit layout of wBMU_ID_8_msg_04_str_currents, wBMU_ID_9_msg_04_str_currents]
BO_ 1352 wBMU_ID_8_msg_04_str_currents: 8 BMU_ID_8
 SG_ Battery_current : 7|16@0+ (0.1,-3200) [0|0] "A"  BMU_ID_0
 SG_ Maximum_sensor_current : 23|16@0+ (0.1,-3200) [0|0] "A"  BMU_ID_0
 SG_ Minimum_sensor_current : 39|16@0+ (0.1,-3200) [0|0] "A"  BMU_ID_0
 SG_ Maximum_sensor_current_ID : 55|8@0+ (1,1) [0|0] "-"  BMU_ID_0
 SG_ Minimum_sensor_current_ID : 63|8@0+ (1,1) [0|0] "-"  BMU_ID_0

BO_ 1353 wBMU_ID_9_msg_04_str_currents: 8 BMU_ID_9
 SG_ Battery_current : 7|16@0+ (0.1,-3200) [0|0] "A"  BMU_ID_0
 SG_ Maximum_sensor_current : 23|16@0+ (0.1,-3200) [0|0] "A"  BMU_ID_0
 SG_ Minimum_sensor_current : 39|16@0+ (0.1,-3200) [0|0] "A"  BMU_ID_0
 SG_ Maximum_sensor_current_ID : 55|8@0+ (1,1) [0|0] "-"  BMU_ID_0
 SG_ Minimum_sensor_current_ID : 63|8@0+ (1,1) [0|0] "-"  BMU_ID_0

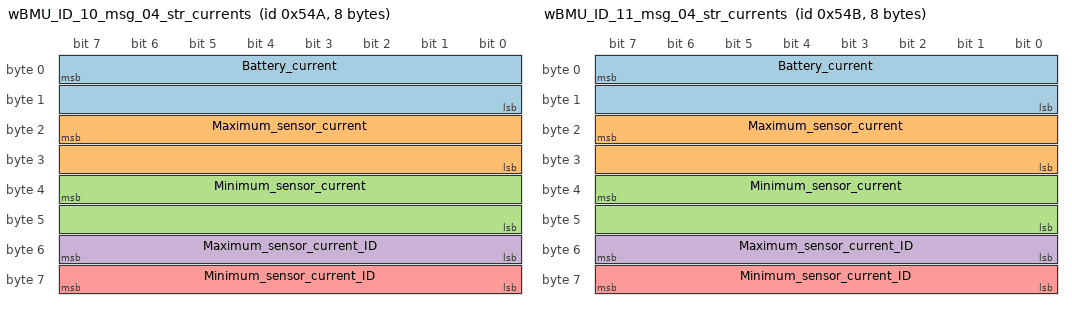
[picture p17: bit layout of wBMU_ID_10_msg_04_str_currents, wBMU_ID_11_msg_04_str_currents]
BO_ 1354 wBMU_ID_10_msg_04_str_currents: 8 BMU_ID_10
 SG_ Battery_current : 7|16@0+ (0.1,-3200) [0|0] "A"  BMU_ID_0
 SG_ Maximum_sensor_current : 23|16@0+ (0.1,-3200) [0|0] "A"  BMU_ID_0
 SG_ Minimum_sensor_current : 39|16@0+ (0.1,-3200) [0|0] "A"  BMU_ID_0
 SG_ Maximum_sensor_current_ID : 55|8@0+ (1,1) [0|0] "-"  BMU_ID_0
 SG_ Minimum_sensor_current_ID : 63|8@0+ (1,1) [0|0] "-"  BMU_ID_0

BO_ 1355 wBMU_ID_11_msg_04_str_currents: 8 BMU_ID_11
 SG_ Battery_current : 7|16@0+ (0.1,-3200) [0|0] "A"  BMU_ID_0
 SG_ Maximum_sensor_current : 23|16@0+ (0.1,-3200) [0|0] "A"  BMU_ID_0
 SG_ Minimum_sensor_current : 39|16@0+ (0.1,-3200) [0|0] "A"  BMU_ID_0
 SG_ Maximum_sensor_current_ID : 55|8@0+ (1,1) [0|0] "-"  BMU_ID_0
 SG_ Minimum_sensor_current_ID : 63|8@0+ (1,1) [0|0] "-"  BMU_ID_0

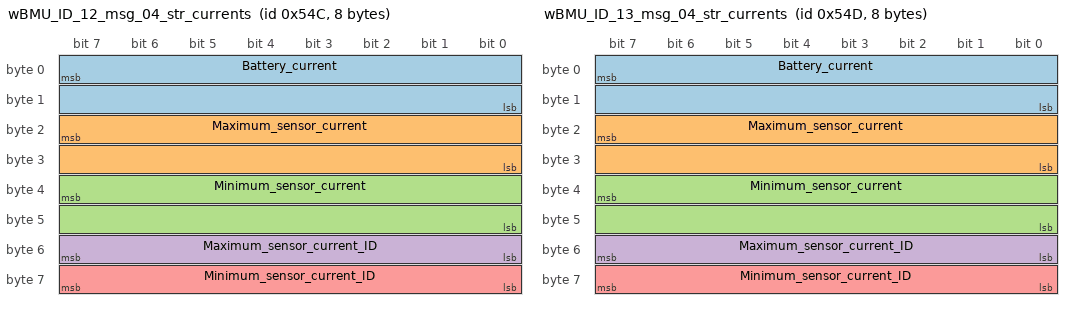
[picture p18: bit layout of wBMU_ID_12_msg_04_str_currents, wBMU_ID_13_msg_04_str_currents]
BO_ 1356 wBMU_ID_12_msg_04_str_currents: 8 BMU_ID_12
 SG_ Battery_current : 7|16@0+ (0.1,-3200) [0|0] "A"  BMU_ID_0
 SG_ Maximum_sensor_current : 23|16@0+ (0.1,-3200) [0|0] "A"  BMU_ID_0
 SG_ Minimum_sensor_current : 39|16@0+ (0.1,-3200) [0|0] "A"  BMU_ID_0
 SG_ Maximum_sensor_current_ID : 55|8@0+ (1,1) [0|0] "-"  BMU_ID_0
 SG_ Minimum_sensor_current_ID : 63|8@0+ (1,1) [0|0] "-"  BMU_ID_0

BO_ 1357 wBMU_ID_13_msg_04_str_currents: 8 BMU_ID_13
 SG_ Battery_current : 7|16@0+ (0.1,-3200) [0|0] "A"  BMU_ID_0
 SG_ Maximum_sensor_current : 23|16@0+ (0.1,-3200) [0|0] "A"  BMU_ID_0
 SG_ Minimum_sensor_current : 39|16@0+ (0.1,-3200) [0|0] "A"  BMU_ID_0
 SG_ Maximum_sensor_current_ID : 55|8@0+ (1,1) [0|0] "-"  BMU_ID_0
 SG_ Minimum_sensor_current_ID : 63|8@0+ (1,1) [0|0] "-"  BMU_ID_0

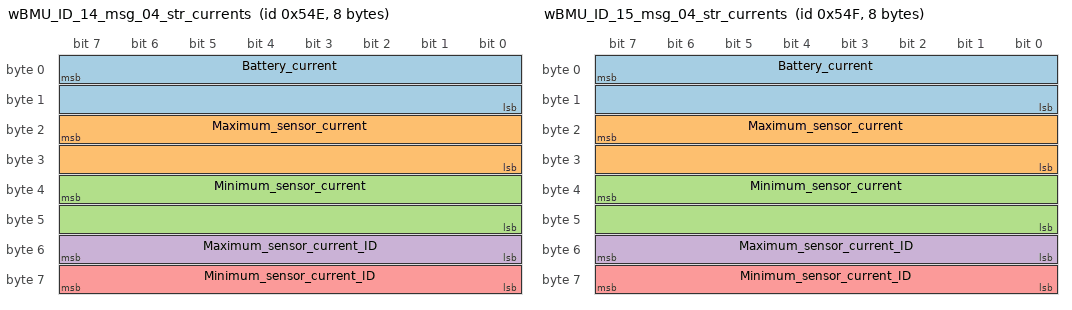
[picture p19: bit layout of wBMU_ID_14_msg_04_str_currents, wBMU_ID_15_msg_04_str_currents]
BO_ 1358 wBMU_ID_14_msg_04_str_currents: 8 BMU_ID_14
 SG_ Battery_current : 7|16@0+ (0.1,-3200) [0|0] "A"  BMU_ID_0
 SG_ Maximum_sensor_current : 23|16@0+ (0.1,-3200) [0|0] "A"  BMU_ID_0
 SG_ Minimum_sensor_current : 39|16@0+ (0.1,-3200) [0|0] "A"  BMU_ID_0
 SG_ Maximum_sensor_current_ID : 55|8@0+ (1,1) [0|0] "-"  BMU_ID_0
 SG_ Minimum_sensor_current_ID : 63|8@0+ (1,1) [0|0] "-"  BMU_ID_0

BO_ 1359 wBMU_ID_15_msg_04_str_currents: 8 BMU_ID_15
 SG_ Battery_current : 7|16@0+ (0.1,-3200) [0|0] "A"  BMU_ID_0
 SG_ Maximum_sensor_current : 23|16@0+ (0.1,-3200) [0|0] "A"  BMU_ID_0
 SG_ Minimum_sensor_current : 39|16@0+ (0.1,-3200) [0|0] "A"  BMU_ID_0
 SG_ Maximum_sensor_current_ID : 55|8@0+ (1,1) [0|0] "-"  BMU_ID_0
 SG_ Minimum_sensor_current_ID : 63|8@0+ (1,1) [0|0] "-"  BMU_ID_0

BO_ 1360 wBMU_ID_0_msg_05_warnings: 8 BMU_ID_0
 SG_ System_errors : 0|1@1+ (1,0) [0|0] ""  BMU_ID_0
 SG_ Architecture_configuration_error : 1|1@1+ (1,0) [0|0] ""  BMU_ID_0
 SG_ Parallelization_voltage_errors : 2|1@1+ (1,0) [0|0] ""  BMU_ID_0
 SG_ General_configuration_errors : 3|1@1+ (1,0) [0|0] ""  BMU_ID_0
 SG_ Parallelization_comm_lost_primar : 4|1@1+ (1,0) [0|0] ""  BMU_ID_0
 SG_ Cell_overvoltage : 5|1@1+ (1,0) [0|0] ""  BMU_ID_0
 SG_ Cell_undervoltage : 6|1@1+ (1,0) [0|0] ""  BMU_ID_0
 SG_ Comm_failure_with_CMU : 7|1@1+ (1,0) [0|0] ""  BMU_ID_0
 SG_ Internal_CMU_error : 8|1@1+ (1,0) [0|0] ""  BMU_ID_0
 SG_ Internal_CMU_temperature_error : 9|1@1+ (1,0) [0|0] ""  BMU_ID_0
 SG_ Internal_CMU_voltage_reference : 10|1@1+ (1,0) [0|0] ""  BMU_ID_0
 SG_ Cell_shortcircuit : 11|1@1+ (1,0) [0|0] ""  BMU_ID_0
 SG_ Battery_overcurrent : 12|1@1+ (1,0) [0|0] ""  BMU_ID_0
 SG_ Overload_ratio_exceeded : 13|1@1+ (1,0) [0|0] ""  BMU_ID_0
 SG_ Current_sensor_errors : 14|1@1+ (1,0) [0|0] ""  BMU_ID_0
 SG_ BMU_temperature_errors : 15|1@1+ (1,0) [0|0] ""  BMU_ID_0
 SG_ Cell_overtemperature : 16|1@1+ (1,0) [0|0] ""  BMU_ID_0
 SG_ Cell_undertemperature : 17|1@1+ (1,0) [0|0] ""  BMU_ID_0
 SG_ Balancing_overtemperature : 18|1@1+ (1,0) [0|0] ""  BMU_ID_0
 SG_ Balancing_undertemperature : 19|1@1+ (1,0) [0|0] ""  BMU_ID_0
 SG_ Max_op_cell_temp_delta : 20|1@1+ (1,0) [0|0] ""  BMU_ID_0
 SG_ Thermal_runaway : 21|1@1+ (1,0) [0|0] ""  BMU_ID_0
 SG_ OW_and_SC_detected_on_cell : 22|1@1+ (1,0) [0|0] ""  BMU_ID_0
 SG_ BMU_external_overtemperature : 23|1@1+ (1,0) [0|0] ""  BMU_ID_0
 SG_ Battery_undervoltage : 24|1@1+ (1,0) [0|0] ""  BMU_ID_0
 SG_ BMU_supply_voltage_error : 25|1@1+ (1,0) [0|0] ""  BMU_ID_0
 SG_ Battery_overvoltage : 26|1@1+ (1,0) [0|0] ""  BMU_ID_0
 SG_ Cells_unbalanced : 27|1@1+ (1,0) [0|0] ""  BMU_ID_0
 SG_ Advanced_relaxation_voltage_delt : 28|1@1+ (1,0) [0|0] ""  BMU_ID_0
 SG_ Internal_BMU_error : 30|1@1+ (1,0) [0|0] ""  BMU_ID_0
 SG_ Safety_sensor_error : 31|1@1+ (1,0) [0|0] ""  BMU_ID_0
 SG_ High_voltage_sensor_errors : 32|1@1+ (1,0) [0|0] ""  BMU_ID_0
 SG_ IMD_errors : 33|1@1+ (1,0) [0|0] ""  BMU_ID_0
 SG_ Isolation_error : 34|1@1+ (1,0) [0|0] ""  BMU_ID_0
 SG_ BMU_SoC_errors : 35|1@1+ (1,0) [0|0] ""  BMU_ID_0
 SG_ BMU_SoH_error : 36|1@1+ (1,0) [0|0] ""  BMU_ID_0
 SG_ Contactor_stuck_open_errors : 37|1@1+ (1,0) [0|0] ""  BMU_ID_0
 SG_ Contactor_stuck_closed_errors : 38|1@1+ (1,0) [0|0] ""  BMU_ID_0
 SG_ Contactor_supply_error : 39|1@1+ (1,0) [0|0] ""  BMU_ID_0
 SG_ Contactor_precharge_error : 40|1@1+ (1,0) [0|0] ""  BMU_ID_0
 SG_ Emergency_button_error : 41|1@1+ (1,0) [0|0] ""  BMU_ID_0
 SG_ Actuation_errors : 42|1@1+ (1,0) [0|0] ""  BMU_ID_0
 SG_ Auto_OFF : 43|1@1+ (1,0) [0|0] ""  BMU_ID_0
 SG_ Mode_mismatch : 44|1@1+ (1,0) [0|0] ""  BMU_ID_0
 SG_ Open_wire_errors : 45|1@1+ (1,0) [0|0] ""  BMU_ID_0
 SG_ Output_driver_errors_diagnostics : 46|1@1+ (1,0) [0|0] ""  BMU_ID_0
 SG_ User_forced_errors : 47|1@1+ (1,0) [0|0] ""  BMU_ID_0
 SG_ SD_error : 48|1@1+ (1,0) [0|0] ""  BMU_ID_0
 SG_ Ethernet_module_error : 49|1@1+ (1,0) [0|0] ""  BMU_ID_0
 SG_ Internal_memory_errors : 29|1@1+ (1,0) [0|0] ""  BMU_ID_0

BO_ 1361 wBMU_ID_1_msg_05_warnings: 8 BMU_ID_1
 SG_ System_errors : 0|1@1+ (1,0) [0|0] ""  BMU_ID_0
 SG_ Architecture_configuration_error : 1|1@1+ (1,0) [0|0] ""  BMU_ID_0
 SG_ Parallelization_voltage_errors : 2|1@1+ (1,0) [0|0] ""  BMU_ID_0
 SG_ General_configuration_errors : 3|1@1+ (1,0) [0|0] ""  BMU_ID_0
 SG_ Parallelization_comm_lost_primar : 4|1@1+ (1,0) [0|0] ""  BMU_ID_0
 SG_ Cell_overvoltage : 5|1@1+ (1,0) [0|0] ""  BMU_ID_0
 SG_ Cell_undervoltage : 6|1@1+ (1,0) [0|0] ""  BMU_ID_0
 SG_ Comm_failure_with_CMU : 7|1@1+ (1,0) [0|0] ""  BMU_ID_0
 SG_ Internal_CMU_error : 8|1@1+ (1,0) [0|0] ""  BMU_ID_0
 SG_ Internal_CMU_temperature_error : 9|1@1+ (1,0) [0|0] ""  BMU_ID_0
 SG_ Internal_CMU_voltage_reference : 10|1@1+ (1,0) [0|0] ""  BMU_ID_0
 SG_ Cell_shortcircuit : 11|1@1+ (1,0) [0|0] ""  BMU_ID_0
 SG_ Battery_overcurrent : 12|1@1+ (1,0) [0|0] ""  BMU_ID_0
 SG_ Overload_ratio_exceeded : 13|1@1+ (1,0) [0|0] ""  BMU_ID_0
 SG_ Current_sensor_errors : 14|1@1+ (1,0) [0|0] ""  BMU_ID_0
 SG_ BMU_temperature_errors : 15|1@1+ (1,0) [0|0] ""  BMU_ID_0
 SG_ Cell_overtemperature : 16|1@1+ (1,0) [0|0] ""  BMU_ID_0
 SG_ Cell_undertemperature : 17|1@1+ (1,0) [0|0] ""  BMU_ID_0
 SG_ Balancing_overtemperature : 18|1@1+ (1,0) [0|0] ""  BMU_ID_0
 SG_ Balancing_undertemperature : 19|1@1+ (1,0) [0|0] ""  BMU_ID_0
 SG_ Max_op_cell_temp_delta : 20|1@1+ (1,0) [0|0] ""  BMU_ID_0
 SG_ Thermal_runaway : 21|1@1+ (1,0) [0|0] ""  BMU_ID_0
 SG_ OW_and_SC_detected_on_cell : 22|1@1+ (1,0) [0|0] ""  BMU_ID_0
 SG_ BMU_external_overtemperature : 23|1@1+ (1,0) [0|0] ""  BMU_ID_0
 SG_ Battery_undervoltage : 24|1@1+ (1,0) [0|0] ""  BMU_ID_0
 SG_ BMU_supply_voltage_error : 25|1@1+ (1,0) [0|0] ""  BMU_ID_0
 SG_ Battery_overvoltage : 26|1@1+ (1,0) [0|0] ""  BMU_ID_0
 SG_ Cells_unbalanced : 27|1@1+ (1,0) [0|0] ""  BMU_ID_0
 SG_ Advanced_relaxation_voltage_delt : 28|1@1+ (1,0) [0|0] ""  BMU_ID_0
 SG_ Internal_BMU_error : 30|1@1+ (1,0) [0|0] ""  BMU_ID_0
 SG_ Safety_sensor_error : 31|1@1+ (1,0) [0|0] ""  BMU_ID_0
 SG_ High_voltage_sensor_errors : 32|1@1+ (1,0) [0|0] ""  BMU_ID_0
 SG_ IMD_errors : 33|1@1+ (1,0) [0|0] ""  BMU_ID_0
 SG_ Isolation_error : 34|1@1+ (1,0) [0|0] ""  BMU_ID_0
 SG_ BMU_SoC_errors : 35|1@1+ (1,0) [0|0] ""  BMU_ID_0
 SG_ BMU_SoH_error : 36|1@1+ (1,0) [0|0] ""  BMU_ID_0
 SG_ Contactor_stuck_open_errors : 37|1@1+ (1,0) [0|0] ""  BMU_ID_0
 SG_ Contactor_stuck_closed_errors : 38|1@1+ (1,0) [0|0] ""  BMU_ID_0
 SG_ Contactor_supply_error : 39|1@1+ (1,0) [0|0] ""  BMU_ID_0
 SG_ Contactor_precharge_error : 40|1@1+ (1,0) [0|0] ""  BMU_ID_0
 SG_ Emergency_button_error : 41|1@1+ (1,0) [0|0] ""  BMU_ID_0
 SG_ Actuation_errors : 42|1@1+ (1,0) [0|0] ""  BMU_ID_0
 SG_ Auto_OFF : 43|1@1+ (1,0) [0|0] ""  BMU_ID_0
 SG_ Mode_mismatch : 44|1@1+ (1,0) [0|0] ""  BMU_ID_0
 SG_ Open_wire_errors : 45|1@1+ (1,0) [0|0] ""  BMU_ID_0
 SG_ Output_driver_errors_diagnostics : 46|1@1+ (1,0) [0|0] ""  BMU_ID_0
 SG_ User_forced_errors : 47|1@1+ (1,0) [0|0] ""  BMU_ID_0
 SG_ SD_error : 48|1@1+ (1,0) [0|0] ""  BMU_ID_0
 SG_ Ethernet_module_error : 49|1@1+ (1,0) [0|0] ""  BMU_ID_0
 SG_ Internal_memory_errors : 29|1@1+ (1,0) [0|0] ""  BMU_ID_0

BO_ 1362 wBMU_ID_2_msg_05_warnings: 8 BMU_ID_2
 SG_ System_errors : 0|1@1+ (1,0) [0|0] ""  BMU_ID_0
 SG_ Architecture_configuration_error : 1|1@1+ (1,0) [0|0] ""  BMU_ID_0
 SG_ Parallelization_voltage_errors : 2|1@1+ (1,0) [0|0] ""  BMU_ID_0
 SG_ General_configuration_errors : 3|1@1+ (1,0) [0|0] ""  BMU_ID_0
 SG_ Parallelization_comm_lost_primar : 4|1@1+ (1,0) [0|0] ""  BMU_ID_0
 SG_ Cell_overvoltage : 5|1@1+ (1,0) [0|0] ""  BMU_ID_0
 SG_ Cell_undervoltage : 6|1@1+ (1,0) [0|0] ""  BMU_ID_0
 SG_ Comm_failure_with_CMU : 7|1@1+ (1,0) [0|0] ""  BMU_ID_0
 SG_ Internal_CMU_error : 8|1@1+ (1,0) [0|0] ""  BMU_ID_0
 SG_ Internal_CMU_temperature_error : 9|1@1+ (1,0) [0|0] ""  BMU_ID_0
 SG_ Internal_CMU_voltage_reference : 10|1@1+ (1,0) [0|0] ""  BMU_ID_0
 SG_ Cell_shortcircuit : 11|1@1+ (1,0) [0|0] ""  BMU_ID_0
 SG_ Battery_overcurrent : 12|1@1+ (1,0) [0|0] ""  BMU_ID_0
 SG_ Overload_ratio_exceeded : 13|1@1+ (1,0) [0|0] ""  BMU_ID_0
 SG_ Current_sensor_errors : 14|1@1+ (1,0) [0|0] ""  BMU_ID_0
 SG_ BMU_temperature_errors : 15|1@1+ (1,0) [0|0] ""  BMU_ID_0
 SG_ Cell_overtemperature : 16|1@1+ (1,0) [0|0] ""  BMU_ID_0
 SG_ Cell_undertemperature : 17|1@1+ (1,0) [0|0] ""  BMU_ID_0
 SG_ Balancing_overtemperature : 18|1@1+ (1,0) [0|0] ""  BMU_ID_0
 SG_ Balancing_undertemperature : 19|1@1+ (1,0) [0|0] ""  BMU_ID_0
 SG_ Max_op_cell_temp_delta : 20|1@1+ (1,0) [0|0] ""  BMU_ID_0
 SG_ Thermal_runaway : 21|1@1+ (1,0) [0|0] ""  BMU_ID_0
 SG_ OW_and_SC_detected_on_cell : 22|1@1+ (1,0) [0|0] ""  BMU_ID_0
 SG_ BMU_external_overtemperature : 23|1@1+ (1,0) [0|0] ""  BMU_ID_0
 SG_ Battery_undervoltage : 24|1@1+ (1,0) [0|0] ""  BMU_ID_0
 SG_ BMU_supply_voltage_error : 25|1@1+ (1,0) [0|0] ""  BMU_ID_0
 SG_ Battery_overvoltage : 26|1@1+ (1,0) [0|0] ""  BMU_ID_0
 SG_ Cells_unbalanced : 27|1@1+ (1,0) [0|0] ""  BMU_ID_0
 SG_ Advanced_relaxation_voltage_delt : 28|1@1+ (1,0) [0|0] ""  BMU_ID_0
 SG_ Internal_BMU_error : 30|1@1+ (1,0) [0|0] ""  BMU_ID_0
 SG_ Safety_sensor_error : 31|1@1+ (1,0) [0|0] ""  BMU_ID_0
 SG_ High_voltage_sensor_errors : 32|1@1+ (1,0) [0|0] ""  BMU_ID_0
 SG_ IMD_errors : 33|1@1+ (1,0) [0|0] ""  BMU_ID_0
 SG_ Isolation_error : 34|1@1+ (1,0) [0|0] ""  BMU_ID_0
 SG_ BMU_SoC_errors : 35|1@1+ (1,0) [0|0] ""  BMU_ID_0
 SG_ BMU_SoH_error : 36|1@1+ (1,0) [0|0] ""  BMU_ID_0
 SG_ Contactor_stuck_open_errors : 37|1@1+ (1,0) [0|0] ""  BMU_ID_0
 SG_ Contactor_stuck_closed_errors : 38|1@1+ (1,0) [0|0] ""  BMU_ID_0
 SG_ Contactor_supply_error : 39|1@1+ (1,0) [0|0] ""  BMU_ID_0
 SG_ Contactor_precharge_error : 40|1@1+ (1,0) [0|0] ""  BMU_ID_0
 SG_ Emergency_button_error : 41|1@1+ (1,0) [0|0] ""  BMU_ID_0
 SG_ Actuation_errors : 42|1@1+ (1,0) [0|0] ""  BMU_ID_0
 SG_ Auto_OFF : 43|1@1+ (1,0) [0|0] ""  BMU_ID_0
 SG_ Mode_mismatch : 44|1@1+ (1,0) [0|0] ""  BMU_ID_0
 SG_ Open_wire_errors : 45|1@1+ (1,0) [0|0] ""  BMU_ID_0
 SG_ Output_driver_errors_diagnostics : 46|1@1+ (1,0) [0|0] ""  BMU_ID_0
 SG_ User_forced_errors : 47|1@1+ (1,0) [0|0] ""  BMU_ID_0
 SG_ SD_error : 48|1@1+ (1,0) [0|0] ""  BMU_ID_0
 SG_ Ethernet_module_error : 49|1@1+ (1,0) [0|0] ""  BMU_ID_0
 SG_ Internal_memory_errors : 29|1@1+ (1,0) [0|0] ""  BMU_ID_0

BO_ 1363 wBMU_ID_3_msg_05_warnings: 8 BMU_ID_3
 SG_ System_errors : 0|1@1+ (1,0) [0|0] ""  BMU_ID_0
 SG_ Architecture_configuration_error : 1|1@1+ (1,0) [0|0] ""  BMU_ID_0
 SG_ Parallelization_voltage_errors : 2|1@1+ (1,0) [0|0] ""  BMU_ID_0
 SG_ General_configuration_errors : 3|1@1+ (1,0) [0|0] ""  BMU_ID_0
 SG_ Parallelization_comm_lost_primar : 4|1@1+ (1,0) [0|0] ""  BMU_ID_0
 SG_ Cell_overvoltage : 5|1@1+ (1,0) [0|0] ""  BMU_ID_0
 SG_ Cell_undervoltage : 6|1@1+ (1,0) [0|0] ""  BMU_ID_0
 SG_ Comm_failure_with_CMU : 7|1@1+ (1,0) [0|0] ""  BMU_ID_0
 SG_ Internal_CMU_error : 8|1@1+ (1,0) [0|0] ""  BMU_ID_0
 SG_ Internal_CMU_temperature_error : 9|1@1+ (1,0) [0|0] ""  BMU_ID_0
 SG_ Internal_CMU_voltage_reference : 10|1@1+ (1,0) [0|0] ""  BMU_ID_0
 SG_ Cell_shortcircuit : 11|1@1+ (1,0) [0|0] ""  BMU_ID_0
 SG_ Battery_overcurrent : 12|1@1+ (1,0) [0|0] ""  BMU_ID_0
 SG_ Overload_ratio_exceeded : 13|1@1+ (1,0) [0|0] ""  BMU_ID_0
 SG_ Current_sensor_errors : 14|1@1+ (1,0) [0|0] ""  BMU_ID_0
 SG_ BMU_temperature_errors : 15|1@1+ (1,0) [0|0] ""  BMU_ID_0
 SG_ Cell_overtemperature : 16|1@1+ (1,0) [0|0] ""  BMU_ID_0
 SG_ Cell_undertemperature : 17|1@1+ (1,0) [0|0] ""  BMU_ID_0
 SG_ Balancing_overtemperature : 18|1@1+ (1,0) [0|0] ""  BMU_ID_0
 SG_ Balancing_undertemperature : 19|1@1+ (1,0) [0|0] ""  BMU_ID_0
 SG_ Max_op_cell_temp_delta : 20|1@1+ (1,0) [0|0] ""  BMU_ID_0
 SG_ Thermal_runaway : 21|1@1+ (1,0) [0|0] ""  BMU_ID_0
 SG_ OW_and_SC_detected_on_cell : 22|1@1+ (1,0) [0|0] ""  BMU_ID_0
 SG_ BMU_external_overtemperature : 23|1@1+ (1,0) [0|0] ""  BMU_ID_0
 SG_ Battery_undervoltage : 24|1@1+ (1,0) [0|0] ""  BMU_ID_0
 SG_ BMU_supply_voltage_error : 25|1@1+ (1,0) [0|0] ""  BMU_ID_0
 SG_ Battery_overvoltage : 26|1@1+ (1,0) [0|0] ""  BMU_ID_0
 SG_ Cells_unbalanced : 27|1@1+ (1,0) [0|0] ""  BMU_ID_0
 SG_ Advanced_relaxation_voltage_delt : 28|1@1+ (1,0) [0|0] ""  BMU_ID_0
 SG_ Internal_BMU_error : 30|1@1+ (1,0) [0|0] ""  BMU_ID_0
 SG_ Safety_sensor_error : 31|1@1+ (1,0) [0|0] ""  BMU_ID_0
 SG_ High_voltage_sensor_errors : 32|1@1+ (1,0) [0|0] ""  BMU_ID_0
 SG_ IMD_errors : 33|1@1+ (1,0) [0|0] ""  BMU_ID_0
 SG_ Isolation_error : 34|1@1+ (1,0) [0|0] ""  BMU_ID_0
 SG_ BMU_SoC_errors : 35|1@1+ (1,0) [0|0] ""  BMU_ID_0
 SG_ BMU_SoH_error : 36|1@1+ (1,0) [0|0] ""  BMU_ID_0
 SG_ Contactor_stuck_open_errors : 37|1@1+ (1,0) [0|0] ""  BMU_ID_0
 SG_ Contactor_stuck_closed_errors : 38|1@1+ (1,0) [0|0] ""  BMU_ID_0
 SG_ Contactor_supply_error : 39|1@1+ (1,0) [0|0] ""  BMU_ID_0
 SG_ Contactor_precharge_error : 40|1@1+ (1,0) [0|0] ""  BMU_ID_0
 SG_ Emergency_button_error : 41|1@1+ (1,0) [0|0] ""  BMU_ID_0
 SG_ Actuation_errors : 42|1@1+ (1,0) [0|0] ""  BMU_ID_0
 SG_ Auto_OFF : 43|1@1+ (1,0) [0|0] ""  BMU_ID_0
 SG_ Mode_mismatch : 44|1@1+ (1,0) [0|0] ""  BMU_ID_0
 SG_ Open_wire_errors : 45|1@1+ (1,0) [0|0] ""  BMU_ID_0
 SG_ Output_driver_errors_diagnostics : 46|1@1+ (1,0) [0|0] ""  BMU_ID_0
 SG_ User_forced_errors : 47|1@1+ (1,0) [0|0] ""  BMU_ID_0
 SG_ SD_error : 48|1@1+ (1,0) [0|0] ""  BMU_ID_0
 SG_ Ethernet_module_error : 49|1@1+ (1,0) [0|0] ""  BMU_ID_0
 SG_ Internal_memory_errors : 29|1@1+ (1,0) [0|0] ""  BMU_ID_0

BO_ 1364 wBMU_ID_4_msg_05_warnings: 8 BMU_ID_4
 SG_ System_errors : 0|1@1+ (1,0) [0|0] ""  BMU_ID_0
 SG_ Architecture_configuration_error : 1|1@1+ (1,0) [0|0] ""  BMU_ID_0
 SG_ Parallelization_voltage_errors : 2|1@1+ (1,0) [0|0] ""  BMU_ID_0
 SG_ General_configuration_errors : 3|1@1+ (1,0) [0|0] ""  BMU_ID_0
 SG_ Parallelization_comm_lost_primar : 4|1@1+ (1,0) [0|0] ""  BMU_ID_0
 SG_ Cell_overvoltage : 5|1@1+ (1,0) [0|0] ""  BMU_ID_0
 SG_ Cell_undervoltage : 6|1@1+ (1,0) [0|0] ""  BMU_ID_0
 SG_ Comm_failure_with_CMU : 7|1@1+ (1,0) [0|0] ""  BMU_ID_0
 SG_ Internal_CMU_error : 8|1@1+ (1,0) [0|0] ""  BMU_ID_0
 SG_ Internal_CMU_temperature_error : 9|1@1+ (1,0) [0|0] ""  BMU_ID_0
 SG_ Internal_CMU_voltage_reference : 10|1@1+ (1,0) [0|0] ""  BMU_ID_0
 SG_ Cell_shortcircuit : 11|1@1+ (1,0) [0|0] ""  BMU_ID_0
 SG_ Battery_overcurrent : 12|1@1+ (1,0) [0|0] ""  BMU_ID_0
 SG_ Overload_ratio_exceeded : 13|1@1+ (1,0) [0|0] ""  BMU_ID_0
 SG_ Current_sensor_errors : 14|1@1+ (1,0) [0|0] ""  BMU_ID_0
 SG_ BMU_temperature_errors : 15|1@1+ (1,0) [0|0] ""  BMU_ID_0
 SG_ Cell_overtemperature : 16|1@1+ (1,0) [0|0] ""  BMU_ID_0
 SG_ Cell_undertemperature : 17|1@1+ (1,0) [0|0] ""  BMU_ID_0
 SG_ Balancing_overtemperature : 18|1@1+ (1,0) [0|0] ""  BMU_ID_0
 SG_ Balancing_undertemperature : 19|1@1+ (1,0) [0|0] ""  BMU_ID_0
 SG_ Max_op_cell_temp_delta : 20|1@1+ (1,0) [0|0] ""  BMU_ID_0
 SG_ Thermal_runaway : 21|1@1+ (1,0) [0|0] ""  BMU_ID_0
 SG_ OW_and_SC_detected_on_cell : 22|1@1+ (1,0) [0|0] ""  BMU_ID_0
 SG_ BMU_external_overtemperature : 23|1@1+ (1,0) [0|0] ""  BMU_ID_0
 SG_ Battery_undervoltage : 24|1@1+ (1,0) [0|0] ""  BMU_ID_0
 SG_ BMU_supply_voltage_error : 25|1@1+ (1,0) [0|0] ""  BMU_ID_0
 SG_ Battery_overvoltage : 26|1@1+ (1,0) [0|0] ""  BMU_ID_0
 SG_ Cells_unbalanced : 27|1@1+ (1,0) [0|0] ""  BMU_ID_0
 SG_ Advanced_relaxation_voltage_delt : 28|1@1+ (1,0) [0|0] ""  BMU_ID_0
 SG_ Internal_BMU_error : 30|1@1+ (1,0) [0|0] ""  BMU_ID_0
 SG_ Safety_sensor_error : 31|1@1+ (1,0) [0|0] ""  BMU_ID_0
 SG_ High_voltage_sensor_errors : 32|1@1+ (1,0) [0|0] ""  BMU_ID_0
 SG_ IMD_errors : 33|1@1+ (1,0) [0|0] ""  BMU_ID_0
 SG_ Isolation_error : 34|1@1+ (1,0) [0|0] ""  BMU_ID_0
 SG_ BMU_SoC_errors : 35|1@1+ (1,0) [0|0] ""  BMU_ID_0
 SG_ BMU_SoH_error : 36|1@1+ (1,0) [0|0] ""  BMU_ID_0
 SG_ Contactor_stuck_open_errors : 37|1@1+ (1,0) [0|0] ""  BMU_ID_0
 SG_ Contactor_stuck_closed_errors : 38|1@1+ (1,0) [0|0] ""  BMU_ID_0
 SG_ Contactor_supply_error : 39|1@1+ (1,0) [0|0] ""  BMU_ID_0
 SG_ Contactor_precharge_error : 40|1@1+ (1,0) [0|0] ""  BMU_ID_0
 SG_ Emergency_button_error : 41|1@1+ (1,0) [0|0] ""  BMU_ID_0
 SG_ Actuation_errors : 42|1@1+ (1,0) [0|0] ""  BMU_ID_0
 SG_ Auto_OFF : 43|1@1+ (1,0) [0|0] ""  BMU_ID_0
 SG_ Mode_mismatch : 44|1@1+ (1,0) [0|0] ""  BMU_ID_0
 SG_ Open_wire_errors : 45|1@1+ (1,0) [0|0] ""  BMU_ID_0
 SG_ Output_driver_errors_diagnostics : 46|1@1+ (1,0) [0|0] ""  BMU_ID_0
 SG_ User_forced_errors : 47|1@1+ (1,0) [0|0] ""  BMU_ID_0
 SG_ SD_error : 48|1@1+ (1,0) [0|0] ""  BMU_ID_0
 SG_ Ethernet_module_error : 49|1@1+ (1,0) [0|0] ""  BMU_ID_0
 SG_ Internal_memory_errors : 29|1@1+ (1,0) [0|0] ""  BMU_ID_0

CM_ BU_ BMU_ID_0 "Primary BMU";
CM_ BU_ BMU_ID_1 "Secondary - BMU ID 1";
CM_ BU_ BMU_ID_2 "Secondary - BMU ID 2";
CM_ BU_ BMU_ID_3 "Secondary - BMU ID 3";
CM_ BU_ BMU_ID_4 "Secondary - BMU ID 4";
CM_ BU_ BMU_ID_5 "Secondary - BMU ID 5";
CM_ BU_ BMU_ID_6 "Secondary - BMU ID 6";
CM_ BU_ BMU_ID_7 "Secondary - BMU ID 7";
CM_ BU_ BMU_ID_8 "Secondary - BMU ID 8";
CM_ BU_ BMU_ID_9 "Secondary - BMU ID 9";
CM_ BU_ BMU_ID_10 "Secondary - BMU ID 10";
CM_ BU_ BMU_ID_11 "Secondary - BMU ID 11";
CM_ BU_ BMU_ID_12 "Secondary - BMU ID 12";
CM_ BU_ BMU_ID_13 "Secondary - BMU ID 13";
CM_ BU_ BMU_ID_14 "Secondary - BMU ID 14";
CM_ BU_ BMU_ID_15 "Secondary - BMU ID 15";
CM_ SG_ 1296 Discharge_current_limit "Maximum current allowed during discharge";
CM_ SG_ 1296 Reconnection_time_interlock_flag "Reconnection time interlock status";
CM_ SG_ 1296 Charge_current_limit "Maximum current allowed during charge";
CM_ SG_ 1297 Discharge_current_limit "Maximum current allowed during discharge";
CM_ SG_ 1297 Reconnection_time_interlock_flag "Reconnection time interlock status";
CM_ SG_ 1297 Charge_current_limit "Maximum current allowed during charge";
CM_ SG_ 1298 Discharge_current_limit "Maximum current allowed during discharge";
CM_ SG_ 1298 Reconnection_time_interlock_flag "Reconnection time interlock status";
CM_ SG_ 1298 Charge_current_limit "Maximum current allowed during charge";
CM_ SG_ 1299 Discharge_current_limit "Maximum current allowed during discharge";
CM_ SG_ 1299 Reconnection_time_interlock_flag "Reconnection time interlock status";
CM_ SG_ 1299 Charge_current_limit "Maximum current allowed during charge";
CM_ SG_ 1300 Discharge_current_limit "Maximum current allowed during discharge";
CM_ SG_ 1300 Reconnection_time_interlock_flag "Reconnection time interlock status";
CM_ SG_ 1300 Charge_current_limit "Maximum current allowed during charge";
CM_ SG_ 1301 Discharge_current_limit "Maximum current allowed during discharge";
CM_ SG_ 1301 Reconnection_time_interlock_flag "Reconnection time interlock status";
CM_ SG_ 1301 Charge_current_limit "Maximum current allowed during charge";
CM_ SG_ 1302 Discharge_current_limit "Maximum current allowed during discharge";
CM_ SG_ 1302 Reconnection_time_interlock_flag "Reconnection time interlock status";
CM_ SG_ 1302 Charge_current_limit "Maximum current allowed during charge";
CM_ SG_ 1303 Discharge_current_limit "Maximum current allowed during discharge";
CM_ SG_ 1303 Reconnection_time_interlock_flag "Reconnection time interlock status";
CM_ SG_ 1303 Charge_current_limit "Maximum current allowed during charge";
CM_ SG_ 1304 Discharge_current_limit "Maximum current allowed during discharge";
CM_ SG_ 1304 Reconnection_time_interlock_flag "Reconnection time interlock status";
CM_ SG_ 1304 Charge_current_limit "Maximum current allowed during charge";
CM_ SG_ 1305 Discharge_current_limit "Maximum current allowed during discharge";
CM_ SG_ 1305 Reconnection_time_interlock_flag "Reconnection time interlock status";
CM_ SG_ 1305 Charge_current_limit "Maximum current allowed during charge";
CM_ SG_ 1306 Discharge_current_limit "Maximum current allowed during discharge";
CM_ SG_ 1306 Reconnection_time_interlock_flag "Reconnection time interlock status";
CM_ SG_ 1306 Charge_current_limit "Maximum current allowed during charge";
CM_ SG_ 1307 Discharge_current_limit "Maximum current allowed during discharge";
CM_ SG_ 1307 Reconnection_time_interlock_flag "Reconnection time interlock status";
CM_ SG_ 1307 Charge_current_limit "Maximum current allowed during charge";
CM_ SG_ 1308 Discharge_current_limit "Maximum current allowed during discharge";
CM_ SG_ 1308 Reconnection_time_interlock_flag "Reconnection time interlock status";
CM_ SG_ 1308 Charge_current_limit "Maximum current allowed during charge";
CM_ SG_ 1309 Discharge_current_limit "Maximum current allowed during discharge";
CM_ SG_ 1309 Reconnection_time_interlock_flag "Reconnection time interlock status";
CM_ SG_ 1309 Charge_current_limit "Maximum current allowed during charge";
CM_ SG_ 1310 Discharge_current_limit "Maximum current allowed during discharge";
CM_ SG_ 1310 Reconnection_time_interlock_flag "Reconnection time interlock status";
CM_ SG_ 1310 Charge_current_limit "Maximum current allowed during charge";
CM_ SG_ 1311 Discharge_current_limit "Maximum current allowed during discharge";
CM_ SG_ 1311 Reconnection_time_interlock_flag "Reconnection time interlock status";
CM_ SG_ 1311 Charge_current_limit "Maximum current allowed during charge";
CM_ SG_ 1312 Charge_voltage_setpoint "Charge voltage setpoint reported to the external charger / load";
CM_ SG_ 1312 Discharge_voltage_setpoint "Discharge voltage setpoint reported to the external charger / load";
CM_ SG_ 1312 Charge_current_setpoint "Charge current setpoint reported to the external charger / load";
CM_ SG_ 1312 Discharge_current_setpoint "Discharge current setpoint reported to the external charger / load";
CM_ SG_ 1313 Charge_voltage_setpoint "Charge voltage setpoint reported to the external charger / load";
CM_ SG_ 1313 Discharge_voltage_setpoint "Discharge voltage setpoint reported to the external charger / load";
CM_ SG_ 1313 Charge_current_setpoint "Charge current setpoint reported to the external charger / load";
CM_ SG_ 1313 Discharge_current_setpoint "Discharge current setpoint reported to the external charger / load";
CM_ SG_ 1314 Charge_voltage_setpoint "Charge voltage setpoint reported to the external charger / load";
CM_ SG_ 1314 Discharge_voltage_setpoint "Discharge voltage setpoint reported to the external charger / load";
CM_ SG_ 1314 Charge_current_setpoint "Charge current setpoint reported to the external charger / load";
CM_ SG_ 1314 Discharge_current_setpoint "Discharge current setpoint reported to the external charger / load";
CM_ SG_ 1315 Charge_voltage_setpoint "Charge voltage setpoint reported to the external charger / load";
CM_ SG_ 1315 Discharge_voltage_setpoint "Discharge voltage setpoint reported to the external charger / load";
CM_ SG_ 1315 Charge_current_setpoint "Charge current setpoint reported to the external charger / load";
CM_ SG_ 1315 Discharge_current_setpoint "Discharge current setpoint reported to the external charger / load";
CM_ SG_ 1316 Charge_voltage_setpoint "Charge voltage setpoint reported to the external charger / load";
CM_ SG_ 1316 Discharge_voltage_setpoint "Discharge voltage setpoint reported to the external charger / load";
CM_ SG_ 1316 Charge_current_setpoint "Charge current setpoint reported to the external charger / load";
CM_ SG_ 1316 Discharge_current_setpoint "Discharge current setpoint reported to the external charger / load";
CM_ SG_ 1317 Charge_voltage_setpoint "Charge voltage setpoint reported to the external charger / load";
CM_ SG_ 1317 Discharge_voltage_setpoint "Discharge voltage setpoint reported to the external charger / load";
CM_ SG_ 1317 Charge_current_setpoint "Charge current setpoint reported to the external charger / load";
CM_ SG_ 1317 Discharge_current_setpoint "Discharge current setpoint reported to the external charger / load";
CM_ SG_ 1318 Charge_voltage_setpoint "Charge voltage setpoint reported to the external charger / load";
CM_ SG_ 1318 Discharge_voltage_setpoint "Discharge voltage setpoint reported to the external charger / load";
CM_ SG_ 1318 Charge_current_setpoint "Charge current setpoint reported to the external charger / load";
CM_ SG_ 1318 Discharge_current_setpoint "Discharge current setpoint reported to the external charger / load";
CM_ SG_ 1319 Charge_voltage_setpoint "Charge voltage setpoint reported to the external charger / load";
CM_ SG_ 1319 Discharge_voltage_setpoint "Discharge voltage setpoint reported to the external charger / load";
CM_ SG_ 1319 Charge_current_setpoint "Charge current setpoint reported to the external charger / load";
CM_ SG_ 1319 Discharge_current_setpoint "Discharge current setpoint reported to the external charger / load";
CM_ SG_ 1320 Charge_voltage_setpoint "Charge voltage setpoint reported to the external charger / load";
CM_ SG_ 1320 Discharge_voltage_setpoint "Discharge voltage setpoint reported to the external charger / load";
CM_ SG_ 1320 Charge_current_setpoint "Charge current setpoint reported to the external charger / load";
CM_ SG_ 1320 Discharge_current_setpoint "Discharge current setpoint reported to the external charger / load";
CM_ SG_ 1321 Charge_voltage_setpoint "Charge voltage setpoint reported to the external charger / load";
CM_ SG_ 1321 Discharge_voltage_setpoint "Discharge voltage setpoint reported to the external charger / load";
CM_ SG_ 1321 Charge_current_setpoint "Charge current setpoint reported to the external charger / load";
CM_ SG_ 1321 Discharge_current_setpoint "Discharge current setpoint reported to the external charger / load";
CM_ SG_ 1322 Charge_voltage_setpoint "Charge voltage setpoint reported to the external charger / load";
CM_ SG_ 1322 Discharge_voltage_setpoint "Discharge voltage setpoint reported to the external charger / load";
CM_ SG_ 1322 Charge_current_setpoint "Charge current setpoint reported to the external charger / load";
CM_ SG_ 1322 Discharge_current_setpoint "Discharge current setpoint reported to the external charger / load";
CM_ SG_ 1323 Charge_voltage_setpoint "Charge voltage setpoint reported to the external charger / load";
CM_ SG_ 1323 Discharge_voltage_setpoint "Discharge voltage setpoint reported to the external charger / load";
CM_ SG_ 1323 Charge_current_setpoint "Charge current setpoint reported to the external charger / load";
CM_ SG_ 1323 Discharge_current_setpoint "Discharge current setpoint reported to the external charger / load";
CM_ SG_ 1324 Charge_voltage_setpoint "Charge voltage setpoint reported to the external charger / load";
CM_ SG_ 1324 Discharge_voltage_setpoint "Discharge voltage setpoint reported to the external charger / load";
CM_ SG_ 1324 Charge_current_setpoint "Charge current setpoint reported to the external charger / load";
CM_ SG_ 1324 Discharge_current_setpoint "Discharge current setpoint reported to the external charger / load";
CM_ SG_ 1325 Charge_voltage_setpoint "Charge voltage setpoint reported to the external charger / load";
CM_ SG_ 1325 Discharge_voltage_setpoint "Discharge voltage setpoint reported to the external charger / load";
CM_ SG_ 1325 Charge_current_setpoint "Charge current setpoint reported to the external charger / load";
CM_ SG_ 1325 Discharge_current_setpoint "Discharge current setpoint reported to the external charger / load";
CM_ SG_ 1326 Charge_voltage_setpoint "Charge voltage setpoint reported to the external charger / load";
CM_ SG_ 1326 Discharge_voltage_setpoint "Discharge voltage setpoint reported to the external charger / load";
CM_ SG_ 1326 Charge_current_setpoint "Charge current setpoint reported to the external charger / load";
CM_ SG_ 1326 Discharge_current_setpoint "Discharge current setpoint reported to the external charger / load";
CM_ SG_ 1327 Charge_voltage_setpoint "Charge voltage setpoint reported to the external charger / load";
CM_ SG_ 1327 Discharge_voltage_setpoint "Discharge voltage setpoint reported to the external charger / load";
CM_ SG_ 1327 Charge_current_setpoint "Charge current setpoint reported to the external charger / load";
CM_ SG_ 1327 Discharge_current_setpoint "Discharge current setpoint reported to the external charger / load";
CM_ SG_ 1328 System_errors "Associated DTC: 156, 157, 158, 159, 160, 162, 163, 197, 228, 266, 267";
CM_ SG_ 1328 Architecture_configuration_error "Associated DTC: 187, 189, 190, 191, 192, 193, 194, 195";
CM_ SG_ 1328 Parallelization_voltage_errors "Associated DTC: 280";
CM_ SG_ 1328 General_configuration_errors "Associated DTC: 67, 69, 70, 72, 244, 245, 268";
CM_ SG_ 1328 Parallelization_comm_lost_primar "Associated DTC: 243";
CM_ SG_ 1328 Cell_overvoltage "Associated DTC: 10";
CM_ SG_ 1328 Cell_undervoltage "Associated DTC: 11, 52";
CM_ SG_ 1328 Comm_failure_with_CMU "Associated DTC: 17";
CM_ SG_ 1328 Internal_CMU_error "Associated DTC: 20, 23, 24, 30, 256, 278";
CM_ SG_ 1328 Internal_CMU_temperature_error "Associated DTC: 25";
CM_ SG_ 1328 Internal_CMU_voltage_reference "Associated DTC: 26";
CM_ SG_ 1328 Cell_shortcircuit "Associated DTC: 27";
CM_ SG_ 1328 Battery_overcurrent "Associated DTC: 28";
CM_ SG_ 1328 Overload_ratio_exceeded "Associated DTC: 164";
CM_ SG_ 1328 Current_sensor_errors "Associated DTC: 22, 34, 79, 167, 229, 239, 277";
CM_ SG_ 1328 BMU_temperature_errors "Associated DTC: 169, 264";
CM_ SG_ 1328 Cell_overtemperature "Associated DTC: 12";
CM_ SG_ 1328 Cell_undertemperature "Associated DTC: 13";
CM_ SG_ 1328 Balancing_overtemperature "Associated DTC: 14";
CM_ SG_ 1328 Balancing_undertemperature "Associated DTC: 15";
CM_ SG_ 1328 Max_op_cell_temp_delta "Associated DTC: 32";
CM_ SG_ 1328 Thermal_runaway "Associated DTC: 16";
CM_ SG_ 1328 OW_and_SC_detected_on_cell "Associated DTC: 31";
CM_ SG_ 1328 BMU_external_overtemperature "Associated DTC: 261, 262, 263";
CM_ SG_ 1328 Battery_undervoltage "Associated DTC: 29";
CM_ SG_ 1328 BMU_supply_voltage_error "Associated DTC: 168";
CM_ SG_ 1328 Battery_overvoltage "Associated DTC: 18";
CM_ SG_ 1328 Cells_unbalanced "Associated DTC: 33, 265";
CM_ SG_ 1328 Advanced_relaxation_voltage_delt "Associated DTC: 19";
CM_ SG_ 1328 Internal_BMU_error "Associated DTC: 63, 77, 170, 176, 183, 184, 249, 260";
CM_ SG_ 1328 Safety_sensor_error "Associated DTC: 246";
CM_ SG_ 1328 High_voltage_sensor_errors "Associated DTC: 61, 240, 273, 274, 275";
CM_ SG_ 1328 IMD_errors "Associated DTC: 276, 279";
CM_ SG_ 1328 Isolation_error "Associated DTC: 174";
CM_ SG_ 1328 BMU_SoC_errors "Associted DTC: 35, 36, 55";
CM_ SG_ 1328 BMU_SoH_error "Associated DTC: 37";
CM_ SG_ 1328 Contactor_stuck_open_errors "Associated DTC: 73, 269, 270";
CM_ SG_ 1328 Contactor_stuck_closed_errors "Associated DTC: 252, 253, 254, 271, 272";
CM_ SG_ 1328 Contactor_supply_error "Associated DTC: 76";
CM_ SG_ 1328 Contactor_precharge_error "Associated DTC: 75";
CM_ SG_ 1328 Emergency_button_error "Associated DTC: 175";
CM_ SG_ 1328 Actuation_errors "Associated DTC: 91, 186";
CM_ SG_ 1328 Auto_OFF "Associated DTC: 185";
CM_ SG_ 1328 Mode_mismatch "Associated DTC: 250";
CM_ SG_ 1328 Open_wire_errors "Associated DTC: 21, 257";
CM_ SG_ 1328 Output_driver_errors_diagnostics "Associated DTC: 74, 78";
CM_ SG_ 1328 User_forced_errors "Associated DTC: 89, 94";
CM_ SG_ 1328 SD_error "Associated DTC: 177";
CM_ SG_ 1328 Ethernet_module_error "Associated DTC: 6";
CM_ SG_ 1328 Internal_memory_errors "Associated DTC: 83, 84, 85, 212";
CM_ SG_ 1329 System_errors "Associated DTC: 156, 157, 158, 159, 160, 162, 163, 197, 228, 266, 267";
CM_ SG_ 1329 Architecture_configuration_error "Associated DTC: 187, 189, 190, 191, 192, 193, 194, 195";
CM_ SG_ 1329 Parallelization_voltage_errors "Associated DTC: 280";
CM_ SG_ 1329 General_configuration_errors "Associated DTC: 67, 69, 70, 72, 244, 245, 268";
CM_ SG_ 1329 Parallelization_comm_lost_primar "Associated DTC: 243";
CM_ SG_ 1329 Cell_overvoltage "Associated DTC: 10";
CM_ SG_ 1329 Cell_undervoltage "Associated DTC: 11, 52";
CM_ SG_ 1329 Comm_failure_with_CMU "Associated DTC: 17";
CM_ SG_ 1329 Internal_CMU_error "Associated DTC: 20, 23, 24, 30, 256, 278";
CM_ SG_ 1329 Internal_CMU_temperature_error "Associated DTC: 25";
CM_ SG_ 1329 Internal_CMU_voltage_reference "Associated DTC: 26";
CM_ SG_ 1329 Cell_shortcircuit "Associated DTC: 27";
CM_ SG_ 1329 Battery_overcurrent "Associated DTC: 28";
CM_ SG_ 1329 Overload_ratio_exceeded "Associated DTC: 164";
CM_ SG_ 1329 Current_sensor_errors "Associated DTC: 22, 34, 79, 167, 229, 239, 277";
CM_ SG_ 1329 BMU_temperature_errors "Associated DTC: 169, 264";
CM_ SG_ 1329 Cell_overtemperature "Associated DTC: 12";
CM_ SG_ 1329 Cell_undertemperature "Associated DTC: 13";
CM_ SG_ 1329 Balancing_overtemperature "Associated DTC: 14";
CM_ SG_ 1329 Balancing_undertemperature "Associated DTC: 15";
CM_ SG_ 1329 Max_op_cell_temp_delta "Associated DTC: 32";
CM_ SG_ 1329 Thermal_runaway "Associated DTC: 16";
CM_ SG_ 1329 OW_and_SC_detected_on_cell "Associated DTC: 31";
CM_ SG_ 1329 BMU_external_overtemperature "Associated DTC: 261, 262, 263";
CM_ SG_ 1329 Battery_undervoltage "Associated DTC: 29";
CM_ SG_ 1329 BMU_supply_voltage_error "Associated DTC: 168";
CM_ SG_ 1329 Battery_overvoltage "Associated DTC: 18";
CM_ SG_ 1329 Cells_unbalanced "Associated DTC: 33, 265";
CM_ SG_ 1329 Advanced_relaxation_voltage_delt "Associated DTC: 19";
CM_ SG_ 1329 Internal_BMU_error "Associated DTC: 63, 77, 170, 176, 183, 184, 249, 260";
CM_ SG_ 1329 Safety_sensor_error "Associated DTC: 246";
CM_ SG_ 1329 High_voltage_sensor_errors "Associated DTC: 61, 240, 273, 274, 275";
CM_ SG_ 1329 IMD_errors "Associated DTC: 276, 279";
CM_ SG_ 1329 Isolation_error "Associated DTC: 174";
CM_ SG_ 1329 BMU_SoC_errors "Associted DTC: 35, 36, 55";
CM_ SG_ 1329 BMU_SoH_error "Associated DTC: 37";
CM_ SG_ 1329 Contactor_stuck_open_errors "Associated DTC: 73, 269, 270";
CM_ SG_ 1329 Contactor_stuck_closed_errors "Associated DTC: 252, 253, 254, 271, 272";
CM_ SG_ 1329 Contactor_supply_error "Associated DTC: 76";
CM_ SG_ 1329 Contactor_precharge_error "Associated DTC: 75";
CM_ SG_ 1329 Emergency_button_error "Associated DTC: 175";
CM_ SG_ 1329 Actuation_errors "Associated DTC: 91, 186";
CM_ SG_ 1329 Auto_OFF "Associated DTC: 185";
CM_ SG_ 1329 Mode_mismatch "Associated DTC: 250";
CM_ SG_ 1329 Open_wire_errors "Associated DTC: 21, 257";
CM_ SG_ 1329 Output_driver_errors_diagnostics "Associated DTC: 74, 78";
CM_ SG_ 1329 User_forced_errors "Associated DTC: 89, 94";
CM_ SG_ 1329 SD_error "Associated DTC: 177";
CM_ SG_ 1329 Ethernet_module_error "Associated DTC: 6";
CM_ SG_ 1329 Internal_memory_errors "Associated DTC: 83, 84, 85, 212";
CM_ SG_ 1330 System_errors "Associated DTC: 156, 157, 158, 159, 160, 162, 163, 197, 228, 266, 267";
CM_ SG_ 1330 Architecture_configuration_error "Associated DTC: 187, 189, 190, 191, 192, 193, 194, 195";
CM_ SG_ 1330 Parallelization_voltage_errors "Associated DTC: 280";
CM_ SG_ 1330 General_configuration_errors "Associated DTC: 67, 69, 70, 72, 244, 245, 268";
CM_ SG_ 1330 Parallelization_comm_lost_primar "Associated DTC: 243";
CM_ SG_ 1330 Cell_overvoltage "Associated DTC: 10";
CM_ SG_ 1330 Cell_undervoltage "Associated DTC: 11, 52";
CM_ SG_ 1330 Comm_failure_with_CMU "Associated DTC: 17";
CM_ SG_ 1330 Internal_CMU_error "Associated DTC: 20, 23, 24, 30, 256, 278";
CM_ SG_ 1330 Internal_CMU_temperature_error "Associated DTC: 25";
CM_ SG_ 1330 Internal_CMU_voltage_reference "Associated DTC: 26";
CM_ SG_ 1330 Cell_shortcircuit "Associated DTC: 27";
CM_ SG_ 1330 Battery_overcurrent "Associated DTC: 28";
CM_ SG_ 1330 Overload_ratio_exceeded "Associated DTC: 164";
CM_ SG_ 1330 Current_sensor_errors "Associated DTC: 22, 34, 79, 167, 229, 239, 277";
CM_ SG_ 1330 BMU_temperature_errors "Associated DTC: 169, 264";
CM_ SG_ 1330 Cell_overtemperature "Associated DTC: 12";
CM_ SG_ 1330 Cell_undertemperature "Associated DTC: 13";
CM_ SG_ 1330 Balancing_overtemperature "Associated DTC: 14";
CM_ SG_ 1330 Balancing_undertemperature "Associated DTC: 15";
CM_ SG_ 1330 Max_op_cell_temp_delta "Associated DTC: 32";
CM_ SG_ 1330 Thermal_runaway "Associated DTC: 16";
CM_ SG_ 1330 OW_and_SC_detected_on_cell "Associated DTC: 31";
CM_ SG_ 1330 BMU_external_overtemperature "Associated DTC: 261, 262, 263";
CM_ SG_ 1330 Battery_undervoltage "Associated DTC: 29";
CM_ SG_ 1330 BMU_supply_voltage_error "Associated DTC: 168";
CM_ SG_ 1330 Battery_overvoltage "Associated DTC: 18";
CM_ SG_ 1330 Cells_unbalanced "Associated DTC: 33, 265";
CM_ SG_ 1330 Advanced_relaxation_voltage_delt "Associated DTC: 19";
CM_ SG_ 1330 Internal_BMU_error "Associated DTC: 63, 77, 170, 176, 183, 184, 249, 260";
CM_ SG_ 1330 Safety_sensor_error "Associated DTC: 246";
CM_ SG_ 1330 High_voltage_sensor_errors "Associated DTC: 61, 240, 273, 274, 275";
CM_ SG_ 1330 IMD_errors "Associated DTC: 276, 279";
CM_ SG_ 1330 Isolation_error "Associated DTC: 174";
CM_ SG_ 1330 BMU_SoC_errors "Associted DTC: 35, 36, 55";
CM_ SG_ 1330 BMU_SoH_error "Associated DTC: 37";
CM_ SG_ 1330 Contactor_stuck_open_errors "Associated DTC: 73, 269, 270";
CM_ SG_ 1330 Contactor_stuck_closed_errors "Associated DTC: 252, 253, 254, 271, 272";
CM_ SG_ 1330 Contactor_supply_error "Associated DTC: 76";
CM_ SG_ 1330 Contactor_precharge_error "Associated DTC: 75";
CM_ SG_ 1330 Emergency_button_error "Associated DTC: 175";
CM_ SG_ 1330 Actuation_errors "Associated DTC: 91, 186";
CM_ SG_ 1330 Auto_OFF "Associated DTC: 185";
CM_ SG_ 1330 Mode_mismatch "Associated DTC: 250";
CM_ SG_ 1330 Open_wire_errors "Associated DTC: 21, 257";
CM_ SG_ 1330 Output_driver_errors_diagnostics "Associated DTC: 74, 78";
CM_ SG_ 1330 User_forced_errors "Associated DTC: 89, 94";
CM_ SG_ 1330 SD_error "Associated DTC: 177";
CM_ SG_ 1330 Ethernet_module_error "Associated DTC: 6";
CM_ SG_ 1330 Internal_memory_errors "Associated DTC: 83, 84, 85, 212";
CM_ SG_ 1331 System_errors "Associated DTC: 156, 157, 158, 159, 160, 162, 163, 197, 228, 266, 267";
CM_ SG_ 1331 Architecture_configuration_error "Associated DTC: 187, 189, 190, 191, 192, 193, 194, 195";
CM_ SG_ 1331 Parallelization_voltage_errors "Associated DTC: 280";
CM_ SG_ 1331 General_configuration_errors "Associated DTC: 67, 69, 70, 72, 244, 245, 268";
CM_ SG_ 1331 Parallelization_comm_lost_primar "Associated DTC: 243";
CM_ SG_ 1331 Cell_overvoltage "Associated DTC: 10";
CM_ SG_ 1331 Cell_undervoltage "Associated DTC: 11, 52";
CM_ SG_ 1331 Comm_failure_with_CMU "Associated DTC: 17";
CM_ SG_ 1331 Internal_CMU_error "Associated DTC: 20, 23, 24, 30, 256, 278";
CM_ SG_ 1331 Internal_CMU_temperature_error "Associated DTC: 25";
CM_ SG_ 1331 Internal_CMU_voltage_reference "Associated DTC: 26";
CM_ SG_ 1331 Cell_shortcircuit "Associated DTC: 27";
CM_ SG_ 1331 Battery_overcurrent "Associated DTC: 28";
CM_ SG_ 1331 Overload_ratio_exceeded "Associated DTC: 164";
CM_ SG_ 1331 Current_sensor_errors "Associated DTC: 22, 34, 79, 167, 229, 239, 277";
CM_ SG_ 1331 BMU_temperature_errors "Associated DTC: 169, 264";
CM_ SG_ 1331 Cell_overtemperature "Associated DTC: 12";
CM_ SG_ 1331 Cell_undertemperature "Associated DTC: 13";
CM_ SG_ 1331 Balancing_overtemperature "Associated DTC: 14";
CM_ SG_ 1331 Balancing_undertemperature "Associated DTC: 15";
CM_ SG_ 1331 Max_op_cell_temp_delta "Associated DTC: 32";
CM_ SG_ 1331 Thermal_runaway "Associated DTC: 16";
CM_ SG_ 1331 OW_and_SC_detected_on_cell "Associated DTC: 31";
CM_ SG_ 1331 BMU_external_overtemperature "Associated DTC: 261, 262, 263";
CM_ SG_ 1331 Battery_undervoltage "Associated DTC: 29";
CM_ SG_ 1331 BMU_supply_voltage_error "Associated DTC: 168";
CM_ SG_ 1331 Battery_overvoltage "Associated DTC: 18";
CM_ SG_ 1331 Cells_unbalanced "Associated DTC: 33, 265";
CM_ SG_ 1331 Advanced_relaxation_voltage_delt "Associated DTC: 19";
CM_ SG_ 1331 Internal_BMU_error "Associated DTC: 63, 77, 170, 176, 183, 184, 249, 260";
CM_ SG_ 1331 Safety_sensor_error "Associated DTC: 246";
CM_ SG_ 1331 High_voltage_sensor_errors "Associated DTC: 61, 240, 273, 274, 275";
CM_ SG_ 1331 IMD_errors "Associated DTC: 276, 279";
CM_ SG_ 1331 Isolation_error "Associated DTC: 174";
CM_ SG_ 1331 BMU_SoC_errors "Associted DTC: 35, 36, 55";
CM_ SG_ 1331 BMU_SoH_error "Associated DTC: 37";
CM_ SG_ 1331 Contactor_stuck_open_errors "Associated DTC: 73, 269, 270";
CM_ SG_ 1331 Contactor_stuck_closed_errors "Associated DTC: 252, 253, 254, 271, 272";
CM_ SG_ 1331 Contactor_supply_error "Associated DTC: 76";
CM_ SG_ 1331 Contactor_precharge_error "Associated DTC: 75";
CM_ SG_ 1331 Emergency_button_error "Associated DTC: 175";
CM_ SG_ 1331 Actuation_errors "Associated DTC: 91, 186";
CM_ SG_ 1331 Auto_OFF "Associated DTC: 185";
CM_ SG_ 1331 Mode_mismatch "Associated DTC: 250";
CM_ SG_ 1331 Open_wire_errors "Associated DTC: 21, 257";
CM_ SG_ 1331 Output_driver_errors_diagnostics "Associated DTC: 74, 78";
CM_ SG_ 1331 User_forced_errors "Associated DTC: 89, 94";
CM_ SG_ 1331 SD_error "Associated DTC: 177";
CM_ SG_ 1331 Ethernet_module_error "Associated DTC: 6";
CM_ SG_ 1331 Internal_memory_errors "Associated DTC: 83, 84, 85, 212";
CM_ SG_ 1332 System_errors "Associated DTC: 156, 157, 158, 159, 160, 162, 163, 197, 228, 266, 267";
CM_ SG_ 1332 Architecture_configuration_error "Associated DTC: 187, 189, 190, 191, 192, 193, 194, 195";
CM_ SG_ 1332 Parallelization_voltage_errors "Associated DTC: 280";
CM_ SG_ 1332 General_configuration_errors "Associated DTC: 67, 69, 70, 72, 244, 245, 268";
CM_ SG_ 1332 Parallelization_comm_lost_primar "Associated DTC: 243";
CM_ SG_ 1332 Cell_overvoltage "Associated DTC: 10";
CM_ SG_ 1332 Cell_undervoltage "Associated DTC: 11, 52";
CM_ SG_ 1332 Comm_failure_with_CMU "Associated DTC: 17";
CM_ SG_ 1332 Internal_CMU_error "Associated DTC: 20, 23, 24, 30, 256, 278";
CM_ SG_ 1332 Internal_CMU_temperature_error "Associated DTC: 25";
CM_ SG_ 1332 Internal_CMU_voltage_reference "Associated DTC: 26";
CM_ SG_ 1332 Cell_shortcircuit "Associated DTC: 27";
CM_ SG_ 1332 Battery_overcurrent "Associated DTC: 28";
CM_ SG_ 1332 Overload_ratio_exceeded "Associated DTC: 164";
CM_ SG_ 1332 Current_sensor_errors "Associated DTC: 22, 34, 79, 167, 229, 239, 277";
CM_ SG_ 1332 BMU_temperature_errors "Associated DTC: 169, 264";
CM_ SG_ 1332 Cell_overtemperature "Associated DTC: 12";
CM_ SG_ 1332 Cell_undertemperature "Associated DTC: 13";
CM_ SG_ 1332 Balancing_overtemperature "Associated DTC: 14";
CM_ SG_ 1332 Balancing_undertemperature "Associated DTC: 15";
CM_ SG_ 1332 Max_op_cell_temp_delta "Associated DTC: 32";
CM_ SG_ 1332 Thermal_runaway "Associated DTC: 16";
CM_ SG_ 1332 OW_and_SC_detected_on_cell "Associated DTC: 31";
CM_ SG_ 1332 BMU_external_overtemperature "Associated DTC: 261, 262, 263";
CM_ SG_ 1332 Battery_undervoltage "Associated DTC: 29";
CM_ SG_ 1332 BMU_supply_voltage_error "Associated DTC: 168";
CM_ SG_ 1332 Battery_overvoltage "Associated DTC: 18";
CM_ SG_ 1332 Cells_unbalanced "Associated DTC: 33, 265";
CM_ SG_ 1332 Advanced_relaxation_voltage_delt "Associated DTC: 19";
CM_ SG_ 1332 Internal_BMU_error "Associated DTC: 63, 77, 170, 176, 183, 184, 249, 260";
CM_ SG_ 1332 Safety_sensor_error "Associated DTC: 246";
CM_ SG_ 1332 High_voltage_sensor_errors "Associated DTC: 61, 240, 273, 274, 275";
CM_ SG_ 1332 IMD_errors "Associated DTC: 276, 279";
CM_ SG_ 1332 Isolation_error "Associated DTC: 174";
CM_ SG_ 1332 BMU_SoC_errors "Associted DTC: 35, 36, 55";
CM_ SG_ 1332 BMU_SoH_error "Associated DTC: 37";
CM_ SG_ 1332 Contactor_stuck_open_errors "Associated DTC: 73, 269, 270";
CM_ SG_ 1332 Contactor_stuck_closed_errors "Associated DTC: 252, 253, 254, 271, 272";
CM_ SG_ 1332 Contactor_supply_error "Associated DTC: 76";
CM_ SG_ 1332 Contactor_precharge_error "Associated DTC: 75";
CM_ SG_ 1332 Emergency_button_error "Associated DTC: 175";
CM_ SG_ 1332 Actuation_errors "Associated DTC: 91, 186";
CM_ SG_ 1332 Auto_OFF "Associated DTC: 185";
CM_ SG_ 1332 Mode_mismatch "Associated DTC: 250";
CM_ SG_ 1332 Open_wire_errors "Associated DTC: 21, 257";
CM_ SG_ 1332 Output_driver_errors_diagnostics "Associated DTC: 74, 78";
CM_ SG_ 1332 User_forced_errors "Associated DTC: 89, 94";
CM_ SG_ 1332 SD_error "Associated DTC: 177";
CM_ SG_ 1332 Ethernet_module_error "Associated DTC: 6";
CM_ SG_ 1332 Internal_memory_errors "Associated DTC: 83, 84, 85, 212";
CM_ SG_ 1333 System_errors "Associated DTC: 156, 157, 158, 159, 160, 162, 163, 197, 228, 266, 267";
CM_ SG_ 1333 Architecture_configuration_error "Associated DTC: 187, 189, 190, 191, 192, 193, 194, 195";
CM_ SG_ 1333 Parallelization_voltage_errors "Associated DTC: 280";
CM_ SG_ 1333 General_configuration_errors "Associated DTC: 67, 69, 70, 72, 244, 245, 268";
CM_ SG_ 1333 Parallelization_comm_lost_primar "Associated DTC: 243";
CM_ SG_ 1333 Cell_overvoltage "Associated DTC: 10";
CM_ SG_ 1333 Cell_undervoltage "Associated DTC: 11, 52";
CM_ SG_ 1333 Comm_failure_with_CMU "Associated DTC: 17";
CM_ SG_ 1333 Internal_CMU_error "Associated DTC: 20, 23, 24, 30, 256, 278";
CM_ SG_ 1333 Internal_CMU_temperature_error "Associated DTC: 25";
CM_ SG_ 1333 Internal_CMU_voltage_reference "Associated DTC: 26";
CM_ SG_ 1333 Cell_shortcircuit "Associated DTC: 27";
CM_ SG_ 1333 Battery_overcurrent "Associated DTC: 28";
CM_ SG_ 1333 Overload_ratio_exceeded "Associated DTC: 164";
CM_ SG_ 1333 Current_sensor_errors "Associated DTC: 22, 34, 79, 167, 229, 239, 277";
CM_ SG_ 1333 BMU_temperature_errors "Associated DTC: 169, 264";
CM_ SG_ 1333 Cell_overtemperature "Associated DTC: 12";
CM_ SG_ 1333 Cell_undertemperature "Associated DTC: 13";
CM_ SG_ 1333 Balancing_overtemperature "Associated DTC: 14";
CM_ SG_ 1333 Balancing_undertemperature "Associated DTC: 15";
CM_ SG_ 1333 Max_op_cell_temp_delta "Associated DTC: 32";
CM_ SG_ 1333 Thermal_runaway "Associated DTC: 16";
CM_ SG_ 1333 OW_and_SC_detected_on_cell "Associated DTC: 31";
CM_ SG_ 1333 BMU_external_overtemperature "Associated DTC: 261, 262, 263";
CM_ SG_ 1333 Battery_undervoltage "Associated DTC: 29";
CM_ SG_ 1333 BMU_supply_voltage_error "Associated DTC: 168";
CM_ SG_ 1333 Battery_overvoltage "Associated DTC: 18";
CM_ SG_ 1333 Cells_unbalanced "Associated DTC: 33, 265";
CM_ SG_ 1333 Advanced_relaxation_voltage_delt "Associated DTC: 19";
CM_ SG_ 1333 Internal_BMU_error "Associated DTC: 63, 77, 170, 176, 183, 184, 249, 260";
CM_ SG_ 1333 Safety_sensor_error "Associated DTC: 246";
CM_ SG_ 1333 High_voltage_sensor_errors "Associated DTC: 61, 240, 273, 274, 275";
CM_ SG_ 1333 IMD_errors "Associated DTC: 276, 279";
CM_ SG_ 1333 Isolation_error "Associated DTC: 174";
CM_ SG_ 1333 BMU_SoC_errors "Associted DTC: 35, 36, 55";
CM_ SG_ 1333 BMU_SoH_error "Associated DTC: 37";
CM_ SG_ 1333 Contactor_stuck_open_errors "Associated DTC: 73, 269, 270";
CM_ SG_ 1333 Contactor_stuck_closed_errors "Associated DTC: 252, 253, 254, 271, 272";
CM_ SG_ 1333 Contactor_supply_error "Associated DTC: 76";
CM_ SG_ 1333 Contactor_precharge_error "Associated DTC: 75";
CM_ SG_ 1333 Emergency_button_error "Associated DTC: 175";
CM_ SG_ 1333 Actuation_errors "Associated DTC: 91, 186";
CM_ SG_ 1333 Auto_OFF "Associated DTC: 185";
CM_ SG_ 1333 Mode_mismatch "Associated DTC: 250";
CM_ SG_ 1333 Open_wire_errors "Associated DTC: 21, 257";
CM_ SG_ 1333 Output_driver_errors_diagnostics "Associated DTC: 74, 78";
CM_ SG_ 1333 User_forced_errors "Associated DTC: 89, 94";
CM_ SG_ 1333 SD_error "Associated DTC: 177";
CM_ SG_ 1333 Ethernet_module_error "Associated DTC: 6";
CM_ SG_ 1333 Internal_memory_errors "Associated DTC: 83, 84, 85, 212";
CM_ SG_ 1334 System_errors "Associated DTC: 156, 157, 158, 159, 160, 162, 163, 197, 228, 266, 267";
CM_ SG_ 1334 Architecture_configuration_error "Associated DTC: 187, 189, 190, 191, 192, 193, 194, 195";
CM_ SG_ 1334 Parallelization_voltage_errors "Associated DTC: 280";
CM_ SG_ 1334 General_configuration_errors "Associated DTC: 67, 69, 70, 72, 244, 245, 268";
CM_ SG_ 1334 Parallelization_comm_lost_primar "Associated DTC: 243";
CM_ SG_ 1334 Cell_overvoltage "Associated DTC: 10";
CM_ SG_ 1334 Cell_undervoltage "Associated DTC: 11, 52";
CM_ SG_ 1334 Comm_failure_with_CMU "Associated DTC: 17";
CM_ SG_ 1334 Internal_CMU_error "Associated DTC: 20, 23, 24, 30, 256, 278";
CM_ SG_ 1334 Internal_CMU_temperature_error "Associated DTC: 25";
CM_ SG_ 1334 Internal_CMU_voltage_reference "Associated DTC: 26";
CM_ SG_ 1334 Cell_shortcircuit "Associated DTC: 27";
CM_ SG_ 1334 Battery_overcurrent "Associated DTC: 28";
CM_ SG_ 1334 Overload_ratio_exceeded "Associated DTC: 164";
CM_ SG_ 1334 Current_sensor_errors "Associated DTC: 22, 34, 79, 167, 229, 239, 277";
CM_ SG_ 1334 BMU_temperature_errors "Associated DTC: 169, 264";
CM_ SG_ 1334 Cell_overtemperature "Associated DTC: 12";
CM_ SG_ 1334 Cell_undertemperature "Associated DTC: 13";
CM_ SG_ 1334 Balancing_overtemperature "Associated DTC: 14";
CM_ SG_ 1334 Balancing_undertemperature "Associated DTC: 15";
CM_ SG_ 1334 Max_op_cell_temp_delta "Associated DTC: 32";
CM_ SG_ 1334 Thermal_runaway "Associated DTC: 16";
CM_ SG_ 1334 OW_and_SC_detected_on_cell "Associated DTC: 31";
CM_ SG_ 1334 BMU_external_overtemperature "Associated DTC: 261, 262, 263";
CM_ SG_ 1334 Battery_undervoltage "Associated DTC: 29";
CM_ SG_ 1334 BMU_supply_voltage_error "Associated DTC: 168";
CM_ SG_ 1334 Battery_overvoltage "Associated DTC: 18";
CM_ SG_ 1334 Cells_unbalanced "Associated DTC: 33, 265";
CM_ SG_ 1334 Advanced_relaxation_voltage_delt "Associated DTC: 19";
CM_ SG_ 1334 Internal_BMU_error "Associated DTC: 63, 77, 170, 176, 183, 184, 249, 260";
CM_ SG_ 1334 Safety_sensor_error "Associated DTC: 246";
CM_ SG_ 1334 High_voltage_sensor_errors "Associated DTC: 61, 240, 273, 274, 275";
CM_ SG_ 1334 IMD_errors "Associated DTC: 276, 279";
CM_ SG_ 1334 Isolation_error "Associated DTC: 174";
CM_ SG_ 1334 BMU_SoC_errors "Associted DTC: 35, 36, 55";
CM_ SG_ 1334 BMU_SoH_error "Associated DTC: 37";
CM_ SG_ 1334 Contactor_stuck_open_errors "Associated DTC: 73, 269, 270";
CM_ SG_ 1334 Contactor_stuck_closed_errors "Associated DTC: 252, 253, 254, 271, 272";
CM_ SG_ 1334 Contactor_supply_error "Associated DTC: 76";
CM_ SG_ 1334 Contactor_precharge_error "Associated DTC: 75";
CM_ SG_ 1334 Emergency_button_error "Associated DTC: 175";
CM_ SG_ 1334 Actuation_errors "Associated DTC: 91, 186";
CM_ SG_ 1334 Auto_OFF "Associated DTC: 185";
CM_ SG_ 1334 Mode_mismatch "Associated DTC: 250";
CM_ SG_ 1334 Open_wire_errors "Associated DTC: 21, 257";
CM_ SG_ 1334 Output_driver_errors_diagnostics "Associated DTC: 74, 78";
CM_ SG_ 1334 User_forced_errors "Associated DTC: 89, 94";
CM_ SG_ 1334 SD_error "Associated DTC: 177";
CM_ SG_ 1334 Ethernet_module_error "Associated DTC: 6";
CM_ SG_ 1334 Internal_memory_errors "Associated DTC: 83, 84, 85, 212";
CM_ SG_ 1335 System_errors "Associated DTC: 156, 157, 158, 159, 160, 162, 163, 197, 228, 266, 267";
CM_ SG_ 1335 Architecture_configuration_error "Associated DTC: 187, 189, 190, 191, 192, 193, 194, 195";
CM_ SG_ 1335 Parallelization_voltage_errors "Associated DTC: 280";
CM_ SG_ 1335 General_configuration_errors "Associated DTC: 67, 69, 70, 72, 244, 245, 268";
CM_ SG_ 1335 Parallelization_comm_lost_primar "Associated DTC: 243";
CM_ SG_ 1335 Cell_overvoltage "Associated DTC: 10";
CM_ SG_ 1335 Cell_undervoltage "Associated DTC: 11, 52";
CM_ SG_ 1335 Comm_failure_with_CMU "Associated DTC: 17";
CM_ SG_ 1335 Internal_CMU_error "Associated DTC: 20, 23, 24, 30, 256, 278";
CM_ SG_ 1335 Internal_CMU_temperature_error "Associated DTC: 25";
CM_ SG_ 1335 Internal_CMU_voltage_reference "Associated DTC: 26";
CM_ SG_ 1335 Cell_shortcircuit "Associated DTC: 27";
CM_ SG_ 1335 Battery_overcurrent "Associated DTC: 28";
CM_ SG_ 1335 Overload_ratio_exceeded "Associated DTC: 164";
CM_ SG_ 1335 Current_sensor_errors "Associated DTC: 22, 34, 79, 167, 229, 239, 277";
CM_ SG_ 1335 BMU_temperature_errors "Associated DTC: 169, 264";
CM_ SG_ 1335 Cell_overtemperature "Associated DTC: 12";
CM_ SG_ 1335 Cell_undertemperature "Associated DTC: 13";
CM_ SG_ 1335 Balancing_overtemperature "Associated DTC: 14";
CM_ SG_ 1335 Balancing_undertemperature "Associated DTC: 15";
CM_ SG_ 1335 Max_op_cell_temp_delta "Associated DTC: 32";
CM_ SG_ 1335 Thermal_runaway "Associated DTC: 16";
CM_ SG_ 1335 OW_and_SC_detected_on_cell "Associated DTC: 31";
CM_ SG_ 1335 BMU_external_overtemperature "Associated DTC: 261, 262, 263";
CM_ SG_ 1335 Battery_undervoltage "Associated DTC: 29";
CM_ SG_ 1335 BMU_supply_voltage_error "Associated DTC: 168";
CM_ SG_ 1335 Battery_overvoltage "Associated DTC: 18";
CM_ SG_ 1335 Cells_unbalanced "Associated DTC: 33, 265";
CM_ SG_ 1335 Advanced_relaxation_voltage_delt "Associated DTC: 19";
CM_ SG_ 1335 Internal_BMU_error "Associated DTC: 63, 77, 170, 176, 183, 184, 249, 260";
CM_ SG_ 1335 Safety_sensor_error "Associated DTC: 246";
CM_ SG_ 1335 High_voltage_sensor_errors "Associated DTC: 61, 240, 273, 274, 275";
CM_ SG_ 1335 IMD_errors "Associated DTC: 276, 279";
CM_ SG_ 1335 Isolation_error "Associated DTC: 174";
CM_ SG_ 1335 BMU_SoC_errors "Associted DTC: 35, 36, 55";
CM_ SG_ 1335 BMU_SoH_error "Associated DTC: 37";
CM_ SG_ 1335 Contactor_stuck_open_errors "Associated DTC: 73, 269, 270";
CM_ SG_ 1335 Contactor_stuck_closed_errors "Associated DTC: 252, 253, 254, 271, 272";
CM_ SG_ 1335 Contactor_supply_error "Associated DTC: 76";
CM_ SG_ 1335 Contactor_precharge_error "Associated DTC: 75";
CM_ SG_ 1335 Emergency_button_error "Associated DTC: 175";
CM_ SG_ 1335 Actuation_errors "Associated DTC: 91, 186";
CM_ SG_ 1335 Auto_OFF "Associated DTC: 185";
CM_ SG_ 1335 Mode_mismatch "Associated DTC: 250";
CM_ SG_ 1335 Open_wire_errors "Associated DTC: 21, 257";
CM_ SG_ 1335 Output_driver_errors_diagnostics "Associated DTC: 74, 78";
CM_ SG_ 1335 User_forced_errors "Associated DTC: 89, 94";
CM_ SG_ 1335 SD_error "Associated DTC: 177";
CM_ SG_ 1335 Ethernet_module_error "Associated DTC: 6";
CM_ SG_ 1335 Internal_memory_errors "Associated DTC: 83, 84, 85, 212";
CM_ SG_ 1336 System_errors "Associated DTC: 156, 157, 158, 159, 160, 162, 163, 197, 228, 266, 267";
CM_ SG_ 1336 Architecture_configuration_error "Associated DTC: 187, 189, 190, 191, 192, 193, 194, 195";
CM_ SG_ 1336 Parallelization_voltage_errors "Associated DTC: 280";
CM_ SG_ 1336 General_configuration_errors "Associated DTC: 67, 69, 70, 72, 244, 245, 268";
CM_ SG_ 1336 Parallelization_comm_lost_primar "Associated DTC: 243";
CM_ SG_ 1336 Cell_overvoltage "Associated DTC: 10";
CM_ SG_ 1336 Cell_undervoltage "Associated DTC: 11, 52";
CM_ SG_ 1336 Comm_failure_with_CMU "Associated DTC: 17";
CM_ SG_ 1336 Internal_CMU_error "Associated DTC: 20, 23, 24, 30, 256, 278";
CM_ SG_ 1336 Internal_CMU_temperature_error "Associated DTC: 25";
CM_ SG_ 1336 Internal_CMU_voltage_reference "Associated DTC: 26";
CM_ SG_ 1336 Cell_shortcircuit "Associated DTC: 27";
CM_ SG_ 1336 Battery_overcurrent "Associated DTC: 28";
CM_ SG_ 1336 Overload_ratio_exceeded "Associated DTC: 164";
CM_ SG_ 1336 Current_sensor_errors "Associated DTC: 22, 34, 79, 167, 229, 239, 277";
CM_ SG_ 1336 BMU_temperature_errors "Associated DTC: 169, 264";
CM_ SG_ 1336 Cell_overtemperature "Associated DTC: 12";
CM_ SG_ 1336 Cell_undertemperature "Associated DTC: 13";
CM_ SG_ 1336 Balancing_overtemperature "Associated DTC: 14";
CM_ SG_ 1336 Balancing_undertemperature "Associated DTC: 15";
CM_ SG_ 1336 Max_op_cell_temp_delta "Associated DTC: 32";
CM_ SG_ 1336 Thermal_runaway "Associated DTC: 16";
CM_ SG_ 1336 OW_and_SC_detected_on_cell "Associated DTC: 31";
CM_ SG_ 1336 BMU_external_overtemperature "Associated DTC: 261, 262, 263";
CM_ SG_ 1336 Battery_undervoltage "Associated DTC: 29";
CM_ SG_ 1336 BMU_supply_voltage_error "Associated DTC: 168";
CM_ SG_ 1336 Battery_overvoltage "Associated DTC: 18";
CM_ SG_ 1336 Cells_unbalanced "Associated DTC: 33, 265";
CM_ SG_ 1336 Advanced_relaxation_voltage_delt "Associated DTC: 19";
CM_ SG_ 1336 Internal_BMU_error "Associated DTC: 63, 77, 170, 176, 183, 184, 249, 260";
CM_ SG_ 1336 Safety_sensor_error "Associated DTC: 246";
CM_ SG_ 1336 High_voltage_sensor_errors "Associated DTC: 61, 240, 273, 274, 275";
CM_ SG_ 1336 IMD_errors "Associated DTC: 276, 279";
CM_ SG_ 1336 Isolation_error "Associated DTC: 174";
CM_ SG_ 1336 BMU_SoC_errors "Associted DTC: 35, 36, 55";
CM_ SG_ 1336 BMU_SoH_error "Associated DTC: 37";
CM_ SG_ 1336 Contactor_stuck_open_errors "Associated DTC: 73, 269, 270";
CM_ SG_ 1336 Contactor_stuck_closed_errors "Associated DTC: 252, 253, 254, 271, 272";
CM_ SG_ 1336 Contactor_supply_error "Associated DTC: 76";
CM_ SG_ 1336 Contactor_precharge_error "Associated DTC: 75";
CM_ SG_ 1336 Emergency_button_error "Associated DTC: 175";
CM_ SG_ 1336 Actuation_errors "Associated DTC: 91, 186";
CM_ SG_ 1336 Auto_OFF "Associated DTC: 185";
CM_ SG_ 1336 Mode_mismatch "Associated DTC: 250";
CM_ SG_ 1336 Open_wire_errors "Associated DTC: 21, 257";
CM_ SG_ 1336 Output_driver_errors_diagnostics "Associated DTC: 74, 78";
CM_ SG_ 1336 User_forced_errors "Associated DTC: 89, 94";
CM_ SG_ 1336 SD_error "Associated DTC: 177";
CM_ SG_ 1336 Ethernet_module_error "Associated DTC: 6";
CM_ SG_ 1336 Internal_memory_errors "Associated DTC: 83, 84, 85, 212";
CM_ SG_ 1337 System_errors "Associated DTC: 156, 157, 158, 159, 160, 162, 163, 197, 228, 266, 267";
CM_ SG_ 1337 Architecture_configuration_error "Associated DTC: 187, 189, 190, 191, 192, 193, 194, 195";
CM_ SG_ 1337 Parallelization_voltage_errors "Associated DTC: 280";
CM_ SG_ 1337 General_configuration_errors "Associated DTC: 67, 69, 70, 72, 244, 245, 268";
CM_ SG_ 1337 Parallelization_comm_lost_primar "Associated DTC: 243";
CM_ SG_ 1337 Cell_overvoltage "Associated DTC: 10";
CM_ SG_ 1337 Cell_undervoltage "Associated DTC: 11, 52";
CM_ SG_ 1337 Comm_failure_with_CMU "Associated DTC: 17";
CM_ SG_ 1337 Internal_CMU_error "Associated DTC: 20, 23, 24, 30, 256, 278";
CM_ SG_ 1337 Internal_CMU_temperature_error "Associated DTC: 25";
CM_ SG_ 1337 Internal_CMU_voltage_reference "Associated DTC: 26";
CM_ SG_ 1337 Cell_shortcircuit "Associated DTC: 27";
CM_ SG_ 1337 Battery_overcurrent "Associated DTC: 28";
CM_ SG_ 1337 Overload_ratio_exceeded "Associated DTC: 164";
CM_ SG_ 1337 Current_sensor_errors "Associated DTC: 22, 34, 79, 167, 229, 239, 277";
CM_ SG_ 1337 BMU_temperature_errors "Associated DTC: 169, 264";
CM_ SG_ 1337 Cell_overtemperature "Associated DTC: 12";
CM_ SG_ 1337 Cell_undertemperature "Associated DTC: 13";
CM_ SG_ 1337 Balancing_overtemperature "Associated DTC: 14";
CM_ SG_ 1337 Balancing_undertemperature "Associated DTC: 15";
CM_ SG_ 1337 Max_op_cell_temp_delta "Associated DTC: 32";
CM_ SG_ 1337 Thermal_runaway "Associated DTC: 16";
CM_ SG_ 1337 OW_and_SC_detected_on_cell "Associated DTC: 31";
CM_ SG_ 1337 BMU_external_overtemperature "Associated DTC: 261, 262, 263";
CM_ SG_ 1337 Battery_undervoltage "Associated DTC: 29";
CM_ SG_ 1337 BMU_supply_voltage_error "Associated DTC: 168";
CM_ SG_ 1337 Battery_overvoltage "Associated DTC: 18";
CM_ SG_ 1337 Cells_unbalanced "Associated DTC: 33, 265";
CM_ SG_ 1337 Advanced_relaxation_voltage_delt "Associated DTC: 19";
CM_ SG_ 1337 Internal_BMU_error "Associated DTC: 63, 77, 170, 176, 183, 184, 249, 260";
CM_ SG_ 1337 Safety_sensor_error "Associated DTC: 246";
CM_ SG_ 1337 High_voltage_sensor_errors "Associated DTC: 61, 240, 273, 274, 275";
CM_ SG_ 1337 IMD_errors "Associated DTC: 276, 279";
CM_ SG_ 1337 Isolation_error "Associated DTC: 174";
CM_ SG_ 1337 BMU_SoC_errors "Associted DTC: 35, 36, 55";
CM_ SG_ 1337 BMU_SoH_error "Associated DTC: 37";
CM_ SG_ 1337 Contactor_stuck_open_errors "Associated DTC: 73, 269, 270";
CM_ SG_ 1337 Contactor_stuck_closed_errors "Associated DTC: 252, 253, 254, 271, 272";
CM_ SG_ 1337 Contactor_supply_error "Associated DTC: 76";
CM_ SG_ 1337 Contactor_precharge_error "Associated DTC: 75";
CM_ SG_ 1337 Emergency_button_error "Associated DTC: 175";
CM_ SG_ 1337 Actuation_errors "Associated DTC: 91, 186";
CM_ SG_ 1337 Auto_OFF "Associated DTC: 185";
CM_ SG_ 1337 Mode_mismatch "Associated DTC: 250";
CM_ SG_ 1337 Open_wire_errors "Associated DTC: 21, 257";
CM_ SG_ 1337 Output_driver_errors_diagnostics "Associated DTC: 74, 78";
CM_ SG_ 1337 User_forced_errors "Associated DTC: 89, 94";
CM_ SG_ 1337 SD_error "Associated DTC: 177";
CM_ SG_ 1337 Ethernet_module_error "Associated DTC: 6";
CM_ SG_ 1337 Internal_memory_errors "Associated DTC: 83, 84, 85, 212";
CM_ SG_ 1338 System_errors "Associated DTC: 156, 157, 158, 159, 160, 162, 163, 197, 228, 266, 267";
CM_ SG_ 1338 Architecture_configuration_error "Associated DTC: 187, 189, 190, 191, 192, 193, 194, 195";
CM_ SG_ 1338 Parallelization_voltage_errors "Associated DTC: 280";
CM_ SG_ 1338 General_configuration_errors "Associated DTC: 67, 69, 70, 72, 244, 245, 268";
CM_ SG_ 1338 Parallelization_comm_lost_primar "Associated DTC: 243";
CM_ SG_ 1338 Cell_overvoltage "Associated DTC: 10";
CM_ SG_ 1338 Cell_undervoltage "Associated DTC: 11, 52";
CM_ SG_ 1338 Comm_failure_with_CMU "Associated DTC: 17";
CM_ SG_ 1338 Internal_CMU_error "Associated DTC: 20, 23, 24, 30, 256, 278";
CM_ SG_ 1338 Internal_CMU_temperature_error "Associated DTC: 25";
CM_ SG_ 1338 Internal_CMU_voltage_reference "Associated DTC: 26";
CM_ SG_ 1338 Cell_shortcircuit "Associated DTC: 27";
CM_ SG_ 1338 Battery_overcurrent "Associated DTC: 28";
CM_ SG_ 1338 Overload_ratio_exceeded "Associated DTC: 164";
CM_ SG_ 1338 Current_sensor_errors "Associated DTC: 22, 34, 79, 167, 229, 239, 277";
CM_ SG_ 1338 BMU_temperature_errors "Associated DTC: 169, 264";
CM_ SG_ 1338 Cell_overtemperature "Associated DTC: 12";
CM_ SG_ 1338 Cell_undertemperature "Associated DTC: 13";
CM_ SG_ 1338 Balancing_overtemperature "Associated DTC: 14";
CM_ SG_ 1338 Balancing_undertemperature "Associated DTC: 15";
CM_ SG_ 1338 Max_op_cell_temp_delta "Associated DTC: 32";
CM_ SG_ 1338 Thermal_runaway "Associated DTC: 16";
CM_ SG_ 1338 OW_and_SC_detected_on_cell "Associated DTC: 31";
CM_ SG_ 1338 BMU_external_overtemperature "Associated DTC: 261, 262, 263";
CM_ SG_ 1338 Battery_undervoltage "Associated DTC: 29";
CM_ SG_ 1338 BMU_supply_voltage_error "Associated DTC: 168";
CM_ SG_ 1338 Battery_overvoltage "Associated DTC: 18";
CM_ SG_ 1338 Cells_unbalanced "Associated DTC: 33, 265";
CM_ SG_ 1338 Advanced_relaxation_voltage_delt "Associated DTC: 19";
CM_ SG_ 1338 Internal_BMU_error "Associated DTC: 63, 77, 170, 176, 183, 184, 249, 260";
CM_ SG_ 1338 Safety_sensor_error "Associated DTC: 246";
CM_ SG_ 1338 High_voltage_sensor_errors "Associated DTC: 61, 240, 273, 274, 275";
CM_ SG_ 1338 IMD_errors "Associated DTC: 276, 279";
CM_ SG_ 1338 Isolation_error "Associated DTC: 174";
CM_ SG_ 1338 BMU_SoC_errors "Associted DTC: 35, 36, 55";
CM_ SG_ 1338 BMU_SoH_error "Associated DTC: 37";
CM_ SG_ 1338 Contactor_stuck_open_errors "Associated DTC: 73, 269, 270";
CM_ SG_ 1338 Contactor_stuck_closed_errors "Associated DTC: 252, 253, 254, 271, 272";
CM_ SG_ 1338 Contactor_supply_error "Associated DTC: 76";
CM_ SG_ 1338 Contactor_precharge_error "Associated DTC: 75";
CM_ SG_ 1338 Emergency_button_error "Associated DTC: 175";
CM_ SG_ 1338 Actuation_errors "Associated DTC: 91, 186";
CM_ SG_ 1338 Auto_OFF "Associated DTC: 185";
CM_ SG_ 1338 Mode_mismatch "Associated DTC: 250";
CM_ SG_ 1338 Open_wire_errors "Associated DTC: 21, 257";
CM_ SG_ 1338 Output_driver_errors_diagnostics "Associated DTC: 74, 78";
CM_ SG_ 1338 User_forced_errors "Associated DTC: 89, 94";
CM_ SG_ 1338 SD_error "Associated DTC: 177";
CM_ SG_ 1338 Ethernet_module_error "Associated DTC: 6";
CM_ SG_ 1338 Internal_memory_errors "Associated DTC: 83, 84, 85, 212";
CM_ SG_ 1339 System_errors "Associated DTC: 156, 157, 158, 159, 160, 162, 163, 197, 228, 266, 267";
CM_ SG_ 1339 Architecture_configuration_error "Associated DTC: 187, 189, 190, 191, 192, 193, 194, 195";
CM_ SG_ 1339 Parallelization_voltage_errors "Associated DTC: 280";
CM_ SG_ 1339 General_configuration_errors "Associated DTC: 67, 69, 70, 72, 244, 245, 268";
CM_ SG_ 1339 Parallelization_comm_lost_primar "Associated DTC: 243";
CM_ SG_ 1339 Cell_overvoltage "Associated DTC: 10";
CM_ SG_ 1339 Cell_undervoltage "Associated DTC: 11, 52";
CM_ SG_ 1339 Comm_failure_with_CMU "Associated DTC: 17";
CM_ SG_ 1339 Internal_CMU_error "Associated DTC: 20, 23, 24, 30, 256, 278";
CM_ SG_ 1339 Internal_CMU_temperature_error "Associated DTC: 25";
CM_ SG_ 1339 Internal_CMU_voltage_reference "Associated DTC: 26";
CM_ SG_ 1339 Cell_shortcircuit "Associated DTC: 27";
CM_ SG_ 1339 Battery_overcurrent "Associated DTC: 28";
CM_ SG_ 1339 Overload_ratio_exceeded "Associated DTC: 164";
CM_ SG_ 1339 Current_sensor_errors "Associated DTC: 22, 34, 79, 167, 229, 239, 277";
CM_ SG_ 1339 BMU_temperature_errors "Associated DTC: 169, 264";
CM_ SG_ 1339 Cell_overtemperature "Associated DTC: 12";
CM_ SG_ 1339 Cell_undertemperature "Associated DTC: 13";
CM_ SG_ 1339 Balancing_overtemperature "Associated DTC: 14";
CM_ SG_ 1339 Balancing_undertemperature "Associated DTC: 15";
CM_ SG_ 1339 Max_op_cell_temp_delta "Associated DTC: 32";
CM_ SG_ 1339 Thermal_runaway "Associated DTC: 16";
CM_ SG_ 1339 OW_and_SC_detected_on_cell "Associated DTC: 31";
CM_ SG_ 1339 BMU_external_overtemperature "Associated DTC: 261, 262, 263";
CM_ SG_ 1339 Battery_undervoltage "Associated DTC: 29";
CM_ SG_ 1339 BMU_supply_voltage_error "Associated DTC: 168";
CM_ SG_ 1339 Battery_overvoltage "Associated DTC: 18";
CM_ SG_ 1339 Cells_unbalanced "Associated DTC: 33, 265";
CM_ SG_ 1339 Advanced_relaxation_voltage_delt "Associated DTC: 19";
CM_ SG_ 1339 Internal_BMU_error "Associated DTC: 63, 77, 170, 176, 183, 184, 249, 260";
CM_ SG_ 1339 Safety_sensor_error "Associated DTC: 246";
CM_ SG_ 1339 High_voltage_sensor_errors "Associated DTC: 61, 240, 273, 274, 275";
CM_ SG_ 1339 IMD_errors "Associated DTC: 276, 279";
CM_ SG_ 1339 Isolation_error "Associated DTC: 174";
CM_ SG_ 1339 BMU_SoC_errors "Associted DTC: 35, 36, 55";
CM_ SG_ 1339 BMU_SoH_error "Associated DTC: 37";
CM_ SG_ 1339 Contactor_stuck_open_errors "Associated DTC: 73, 269, 270";
CM_ SG_ 1339 Contactor_stuck_closed_errors "Associated DTC: 252, 253, 254, 271, 272";
CM_ SG_ 1339 Contactor_supply_error "Associated DTC: 76";
CM_ SG_ 1339 Contactor_precharge_error "Associated DTC: 75";
CM_ SG_ 1339 Emergency_button_error "Associated DTC: 175";
CM_ SG_ 1339 Actuation_errors "Associated DTC: 91, 186";
CM_ SG_ 1339 Auto_OFF "Associated DTC: 185";
CM_ SG_ 1339 Mode_mismatch "Associated DTC: 250";
CM_ SG_ 1339 Open_wire_errors "Associated DTC: 21, 257";
CM_ SG_ 1339 Output_driver_errors_diagnostics "Associated DTC: 74, 78";
CM_ SG_ 1339 User_forced_errors "Associated DTC: 89, 94";
CM_ SG_ 1339 SD_error "Associated DTC: 177";
CM_ SG_ 1339 Ethernet_module_error "Associated DTC: 6";
CM_ SG_ 1339 Internal_memory_errors "Associated DTC: 83, 84, 85, 212";
CM_ SG_ 1340 System_errors "Associated DTC: 156, 157, 158, 159, 160, 162, 163, 197, 228, 266, 267";
CM_ SG_ 1340 Architecture_configuration_error "Associated DTC: 187, 189, 190, 191, 192, 193, 194, 195";
CM_ SG_ 1340 Parallelization_voltage_errors "Associated DTC: 280";
CM_ SG_ 1340 General_configuration_errors "Associated DTC: 67, 69, 70, 72, 244, 245, 268";
CM_ SG_ 1340 Parallelization_comm_lost_primar "Associated DTC: 243";
CM_ SG_ 1340 Cell_overvoltage "Associated DTC: 10";
CM_ SG_ 1340 Cell_undervoltage "Associated DTC: 11, 52";
CM_ SG_ 1340 Comm_failure_with_CMU "Associated DTC: 17";
CM_ SG_ 1340 Internal_CMU_error "Associated DTC: 20, 23, 24, 30, 256, 278";
CM_ SG_ 1340 Internal_CMU_temperature_error "Associated DTC: 25";
CM_ SG_ 1340 Internal_CMU_voltage_reference "Associated DTC: 26";
CM_ SG_ 1340 Cell_shortcircuit "Associated DTC: 27";
CM_ SG_ 1340 Battery_overcurrent "Associated DTC: 28";
CM_ SG_ 1340 Overload_ratio_exceeded "Associated DTC: 164";
CM_ SG_ 1340 Current_sensor_errors "Associated DTC: 22, 34, 79, 167, 229, 239, 277";
CM_ SG_ 1340 BMU_temperature_errors "Associated DTC: 169, 264";
CM_ SG_ 1340 Cell_overtemperature "Associated DTC: 12";
CM_ SG_ 1340 Cell_undertemperature "Associated DTC: 13";
CM_ SG_ 1340 Balancing_overtemperature "Associated DTC: 14";
CM_ SG_ 1340 Balancing_undertemperature "Associated DTC: 15";
CM_ SG_ 1340 Max_op_cell_temp_delta "Associated DTC: 32";
CM_ SG_ 1340 Thermal_runaway "Associated DTC: 16";
CM_ SG_ 1340 OW_and_SC_detected_on_cell "Associated DTC: 31";
CM_ SG_ 1340 BMU_external_overtemperature "Associated DTC: 261, 262, 263";
CM_ SG_ 1340 Battery_undervoltage "Associated DTC: 29";
CM_ SG_ 1340 BMU_supply_voltage_error "Associated DTC: 168";
CM_ SG_ 1340 Battery_overvoltage "Associated DTC: 18";
CM_ SG_ 1340 Cells_unbalanced "Associated DTC: 33, 265";
CM_ SG_ 1340 Advanced_relaxation_voltage_delt "Associated DTC: 19";
CM_ SG_ 1340 Internal_BMU_error "Associated DTC: 63, 77, 170, 176, 183, 184, 249, 260";
CM_ SG_ 1340 Safety_sensor_error "Associated DTC: 246";
CM_ SG_ 1340 High_voltage_sensor_errors "Associated DTC: 61, 240, 273, 274, 275";
CM_ SG_ 1340 IMD_errors "Associated DTC: 276, 279";
CM_ SG_ 1340 Isolation_error "Associated DTC: 174";
CM_ SG_ 1340 BMU_SoC_errors "Associted DTC: 35, 36, 55";
CM_ SG_ 1340 BMU_SoH_error "Associated DTC: 37";
CM_ SG_ 1340 Contactor_stuck_open_errors "Associated DTC: 73, 269, 270";
CM_ SG_ 1340 Contactor_stuck_closed_errors "Associated DTC: 252, 253, 254, 271, 272";
CM_ SG_ 1340 Contactor_supply_error "Associated DTC: 76";
CM_ SG_ 1340 Contactor_precharge_error "Associated DTC: 75";
CM_ SG_ 1340 Emergency_button_error "Associated DTC: 175";
CM_ SG_ 1340 Actuation_errors "Associated DTC: 91, 186";
CM_ SG_ 1340 Auto_OFF "Associated DTC: 185";
CM_ SG_ 1340 Mode_mismatch "Associated DTC: 250";
CM_ SG_ 1340 Open_wire_errors "Associated DTC: 21, 257";
CM_ SG_ 1340 Output_driver_errors_diagnostics "Associated DTC: 74, 78";
CM_ SG_ 1340 User_forced_errors "Associated DTC: 89, 94";
CM_ SG_ 1340 SD_error "Associated DTC: 177";
CM_ SG_ 1340 Ethernet_module_error "Associated DTC: 6";
CM_ SG_ 1340 Internal_memory_errors "Associated DTC: 83, 84, 85, 212";
CM_ SG_ 1341 System_errors "Associated DTC: 156, 157, 158, 159, 160, 162, 163, 197, 228, 266, 267";
CM_ SG_ 1341 Architecture_configuration_error "Associated DTC: 187, 189, 190, 191, 192, 193, 194, 195";
CM_ SG_ 1341 Parallelization_voltage_errors "Associated DTC: 280";
CM_ SG_ 1341 General_configuration_errors "Associated DTC: 67, 69, 70, 72, 244, 245, 268";
CM_ SG_ 1341 Parallelization_comm_lost_primar "Associated DTC: 243";
CM_ SG_ 1341 Cell_overvoltage "Associated DTC: 10";
CM_ SG_ 1341 Cell_undervoltage "Associated DTC: 11, 52";
CM_ SG_ 1341 Comm_failure_with_CMU "Associated DTC: 17";
CM_ SG_ 1341 Internal_CMU_error "Associated DTC: 20, 23, 24, 30, 256, 278";
CM_ SG_ 1341 Internal_CMU_temperature_error "Associated DTC: 25";
CM_ SG_ 1341 Internal_CMU_voltage_reference "Associated DTC: 26";
CM_ SG_ 1341 Cell_shortcircuit "Associated DTC: 27";
CM_ SG_ 1341 Battery_overcurrent "Associated DTC: 28";
CM_ SG_ 1341 Overload_ratio_exceeded "Associated DTC: 164";
CM_ SG_ 1341 Current_sensor_errors "Associated DTC: 22, 34, 79, 167, 229, 239, 277";
CM_ SG_ 1341 BMU_temperature_errors "Associated DTC: 169, 264";
CM_ SG_ 1341 Cell_overtemperature "Associated DTC: 12";
CM_ SG_ 1341 Cell_undertemperature "Associated DTC: 13";
CM_ SG_ 1341 Balancing_overtemperature "Associated DTC: 14";
CM_ SG_ 1341 Balancing_undertemperature "Associated DTC: 15";
CM_ SG_ 1341 Max_op_cell_temp_delta "Associated DTC: 32";
CM_ SG_ 1341 Thermal_runaway "Associated DTC: 16";
CM_ SG_ 1341 OW_and_SC_detected_on_cell "Associated DTC: 31";
CM_ SG_ 1341 BMU_external_overtemperature "Associated DTC: 261, 262, 263";
CM_ SG_ 1341 Battery_undervoltage "Associated DTC: 29";
CM_ SG_ 1341 BMU_supply_voltage_error "Associated DTC: 168";
CM_ SG_ 1341 Battery_overvoltage "Associated DTC: 18";
CM_ SG_ 1341 Cells_unbalanced "Associated DTC: 33, 265";
CM_ SG_ 1341 Advanced_relaxation_voltage_delt "Associated DTC: 19";
CM_ SG_ 1341 Internal_BMU_error "Associated DTC: 63, 77, 170, 176, 183, 184, 249, 260";
CM_ SG_ 1341 Safety_sensor_error "Associated DTC: 246";
CM_ SG_ 1341 High_voltage_sensor_errors "Associated DTC: 61, 240, 273, 274, 275";
CM_ SG_ 1341 IMD_errors "Associated DTC: 276, 279";
CM_ SG_ 1341 Isolation_error "Associated DTC: 174";
CM_ SG_ 1341 BMU_SoC_errors "Associted DTC: 35, 36, 55";
CM_ SG_ 1341 BMU_SoH_error "Associated DTC: 37";
CM_ SG_ 1341 Contactor_stuck_open_errors "Associated DTC: 73, 269, 270";
CM_ SG_ 1341 Contactor_stuck_closed_errors "Associated DTC: 252, 253, 254, 271, 272";
CM_ SG_ 1341 Contactor_supply_error "Associated DTC: 76";
CM_ SG_ 1341 Contactor_precharge_error "Associated DTC: 75";
CM_ SG_ 1341 Emergency_button_error "Associated DTC: 175";
CM_ SG_ 1341 Actuation_errors "Associated DTC: 91, 186";
CM_ SG_ 1341 Auto_OFF "Associated DTC: 185";
CM_ SG_ 1341 Mode_mismatch "Associated DTC: 250";
CM_ SG_ 1341 Open_wire_errors "Associated DTC: 21, 257";
CM_ SG_ 1341 Output_driver_errors_diagnostics "Associated DTC: 74, 78";
CM_ SG_ 1341 User_forced_errors "Associated DTC: 89, 94";
CM_ SG_ 1341 SD_error "Associated DTC: 177";
CM_ SG_ 1341 Ethernet_module_error "Associated DTC: 6";
CM_ SG_ 1341 Internal_memory_errors "Associated DTC: 83, 84, 85, 212";
CM_ SG_ 1342 System_errors "Associated DTC: 156, 157, 158, 159, 160, 162, 163, 197, 228, 266, 267";
CM_ SG_ 1342 Architecture_configuration_error "Associated DTC: 187, 189, 190, 191, 192, 193, 194, 195";
CM_ SG_ 1342 Parallelization_voltage_errors "Associated DTC: 280";
CM_ SG_ 1342 General_configuration_errors "Associated DTC: 67, 69, 70, 72, 244, 245, 268";
CM_ SG_ 1342 Parallelization_comm_lost_primar "Associated DTC: 243";
CM_ SG_ 1342 Cell_overvoltage "Associated DTC: 10";
CM_ SG_ 1342 Cell_undervoltage "Associated DTC: 11, 52";
CM_ SG_ 1342 Comm_failure_with_CMU "Associated DTC: 17";
CM_ SG_ 1342 Internal_CMU_error "Associated DTC: 20, 23, 24, 30, 256, 278";
CM_ SG_ 1342 Internal_CMU_temperature_error "Associated DTC: 25";
CM_ SG_ 1342 Internal_CMU_voltage_reference "Associated DTC: 26";
CM_ SG_ 1342 Cell_shortcircuit "Associated DTC: 27";
CM_ SG_ 1342 Battery_overcurrent "Associated DTC: 28";
CM_ SG_ 1342 Overload_ratio_exceeded "Associated DTC: 164";
CM_ SG_ 1342 Current_sensor_errors "Associated DTC: 22, 34, 79, 167, 229, 239, 277";
CM_ SG_ 1342 BMU_temperature_errors "Associated DTC: 169, 264";
CM_ SG_ 1342 Cell_overtemperature "Associated DTC: 12";
CM_ SG_ 1342 Cell_undertemperature "Associated DTC: 13";
CM_ SG_ 1342 Balancing_overtemperature "Associated DTC: 14";
CM_ SG_ 1342 Balancing_undertemperature "Associated DTC: 15";
CM_ SG_ 1342 Max_op_cell_temp_delta "Associated DTC: 32";
CM_ SG_ 1342 Thermal_runaway "Associated DTC: 16";
CM_ SG_ 1342 OW_and_SC_detected_on_cell "Associated DTC: 31";
CM_ SG_ 1342 BMU_external_overtemperature "Associated DTC: 261, 262, 263";
CM_ SG_ 1342 Battery_undervoltage "Associated DTC: 29";
CM_ SG_ 1342 BMU_supply_voltage_error "Associated DTC: 168";
CM_ SG_ 1342 Battery_overvoltage "Associated DTC: 18";
CM_ SG_ 1342 Cells_unbalanced "Associated DTC: 33, 265";
CM_ SG_ 1342 Advanced_relaxation_voltage_delt "Associated DTC: 19";
CM_ SG_ 1342 Internal_BMU_error "Associated DTC: 63, 77, 170, 176, 183, 184, 249, 260";
CM_ SG_ 1342 Safety_sensor_error "Associated DTC: 246";
CM_ SG_ 1342 High_voltage_sensor_errors "Associated DTC: 61, 240, 273, 274, 275";
CM_ SG_ 1342 IMD_errors "Associated DTC: 276, 279";
CM_ SG_ 1342 Isolation_error "Associated DTC: 174";
CM_ SG_ 1342 BMU_SoC_errors "Associted DTC: 35, 36, 55";
CM_ SG_ 1342 BMU_SoH_error "Associated DTC: 37";
CM_ SG_ 1342 Contactor_stuck_open_errors "Associated DTC: 73, 269, 270";
CM_ SG_ 1342 Contactor_stuck_closed_errors "Associated DTC: 252, 253, 254, 271, 272";
CM_ SG_ 1342 Contactor_supply_error "Associated DTC: 76";
CM_ SG_ 1342 Contactor_precharge_error "Associated DTC: 75";
CM_ SG_ 1342 Emergency_button_error "Associated DTC: 175";
CM_ SG_ 1342 Actuation_errors "Associated DTC: 91, 186";
CM_ SG_ 1342 Auto_OFF "Associated DTC: 185";
CM_ SG_ 1342 Mode_mismatch "Associated DTC: 250";
CM_ SG_ 1342 Open_wire_errors "Associated DTC: 21, 257";
CM_ SG_ 1342 Output_driver_errors_diagnostics "Associated DTC: 74, 78";
CM_ SG_ 1342 User_forced_errors "Associated DTC: 89, 94";
CM_ SG_ 1342 SD_error "Associated DTC: 177";
CM_ SG_ 1342 Ethernet_module_error "Associated DTC: 6";
CM_ SG_ 1342 Internal_memory_errors "Associated DTC: 83, 84, 85, 212";
CM_ SG_ 1343 System_errors "Associated DTC: 156, 157, 158, 159, 160, 162, 163, 197, 228, 266, 267";
CM_ SG_ 1343 Architecture_configuration_error "Associated DTC: 187, 189, 190, 191, 192, 193, 194, 195";
CM_ SG_ 1343 Parallelization_voltage_errors "Associated DTC: 280";
CM_ SG_ 1343 General_configuration_errors "Associated DTC: 67, 69, 70, 72, 244, 245, 268";
CM_ SG_ 1343 Parallelization_comm_lost_primar "Associated DTC: 243";
CM_ SG_ 1343 Cell_overvoltage "Associated DTC: 10";
CM_ SG_ 1343 Cell_undervoltage "Associated DTC: 11, 52";
CM_ SG_ 1343 Comm_failure_with_CMU "Associated DTC: 17";
CM_ SG_ 1343 Internal_CMU_error "Associated DTC: 20, 23, 24, 30, 256, 278";
CM_ SG_ 1343 Internal_CMU_temperature_error "Associated DTC: 25";
CM_ SG_ 1343 Internal_CMU_voltage_reference "Associated DTC: 26";
CM_ SG_ 1343 Cell_shortcircuit "Associated DTC: 27";
CM_ SG_ 1343 Battery_overcurrent "Associated DTC: 28";
CM_ SG_ 1343 Overload_ratio_exceeded "Associated DTC: 164";
CM_ SG_ 1343 Current_sensor_errors "Associated DTC: 22, 34, 79, 167, 229, 239, 277";
CM_ SG_ 1343 BMU_temperature_errors "Associated DTC: 169, 264";
CM_ SG_ 1343 Cell_overtemperature "Associated DTC: 12";
CM_ SG_ 1343 Cell_undertemperature "Associated DTC: 13";
CM_ SG_ 1343 Balancing_overtemperature "Associated DTC: 14";
CM_ SG_ 1343 Balancing_undertemperature "Associated DTC: 15";
CM_ SG_ 1343 Max_op_cell_temp_delta "Associated DTC: 32";
CM_ SG_ 1343 Thermal_runaway "Associated DTC: 16";
CM_ SG_ 1343 OW_and_SC_detected_on_cell "Associated DTC: 31";
CM_ SG_ 1343 BMU_external_overtemperature "Associated DTC: 261, 262, 263";
CM_ SG_ 1343 Battery_undervoltage "Associated DTC: 29";
CM_ SG_ 1343 BMU_supply_voltage_error "Associated DTC: 168";
CM_ SG_ 1343 Battery_overvoltage "Associated DTC: 18";
CM_ SG_ 1343 Cells_unbalanced "Associated DTC: 33, 265";
CM_ SG_ 1343 Advanced_relaxation_voltage_delt "Associated DTC: 19";
CM_ SG_ 1343 Internal_BMU_error "Associated DTC: 63, 77, 170, 176, 183, 184, 249, 260";
CM_ SG_ 1343 Safety_sensor_error "Associated DTC: 246";
CM_ SG_ 1343 High_voltage_sensor_errors "Associated DTC: 61, 240, 273, 274, 275";
CM_ SG_ 1343 IMD_errors "Associated DTC: 276, 279";
CM_ SG_ 1343 Isolation_error "Associated DTC: 174";
CM_ SG_ 1343 BMU_SoC_errors "Associted DTC: 35, 36, 55";
CM_ SG_ 1343 BMU_SoH_error "Associated DTC: 37";
CM_ SG_ 1343 Contactor_stuck_open_errors "Associated DTC: 73, 269, 270";
CM_ SG_ 1343 Contactor_stuck_closed_errors "Associated DTC: 252, 253, 254, 271, 272";
CM_ SG_ 1343 Contactor_supply_error "Associated DTC: 76";
CM_ SG_ 1343 Contactor_precharge_error "Associated DTC: 75";
CM_ SG_ 1343 Emergency_button_error "Associated DTC: 175";
CM_ SG_ 1343 Actuation_errors "Associated DTC: 91, 186";
CM_ SG_ 1343 Auto_OFF "Associated DTC: 185";
CM_ SG_ 1343 Mode_mismatch "Associated DTC: 250";
CM_ SG_ 1343 Open_wire_errors "Associated DTC: 21, 257";
CM_ SG_ 1343 Output_driver_errors_diagnostics "Associated DTC: 74, 78";
CM_ SG_ 1343 User_forced_errors "Associated DTC: 89, 94";
CM_ SG_ 1343 SD_error "Associated DTC: 177";
CM_ SG_ 1343 Ethernet_module_error "Associated DTC: 6";
CM_ SG_ 1343 Internal_memory_errors "Associated DTC: 83, 84, 85, 212";
CM_ BO_ 1344 "Str = string";
CM_ SG_ 1344 Battery_current "Measured current by the BMU";
CM_ SG_ 1344 Maximum_sensor_current "Maximum Sensor Current (value)";
CM_ SG_ 1344 Minimum_sensor_current "Minimum Sensor Current (value)";
CM_ SG_ 1344 Maximum_sensor_current_ID "Maximum Sensor Current (Sensor ID)";
CM_ SG_ 1344 Minimum_sensor_current_ID "Minimum Sensor Current (Sensor ID)";
CM_ BO_ 1345 "Str = string";
CM_ BO_ 1346 "Str = string";
CM_ BO_ 1347 "Str = string";
CM_ BO_ 1348 "Str = string";
CM_ BO_ 1349 "Str = string";
CM_ BO_ 1350 "Str = string";
CM_ BO_ 1351 "Str = string";
CM_ BO_ 1352 "Str = string";
CM_ BO_ 1353 "Str = string";
CM_ BO_ 1354 "Str = string";
CM_ BO_ 1355 "Str = string";
CM_ BO_ 1356 "Str = string";
CM_ BO_ 1357 "Str = string";
CM_ BO_ 1358 "Str = string";
CM_ BO_ 1359 "Str = string";
CM_ SG_ 1360 System_errors "Associated DTC: 156, 157, 158, 159, 160, 162, 163, 197, 228, 266, 267";
CM_ SG_ 1360 Architecture_configuration_error "Associated DTC: 187, 189, 190, 191, 192, 193, 194, 195";
CM_ SG_ 1360 Parallelization_voltage_errors "Associated DTC: 280";
CM_ SG_ 1360 General_configuration_errors "Associated DTC: 67, 69, 70, 72, 244, 245, 268";
CM_ SG_ 1360 Parallelization_comm_lost_primar "Associated DTC: 243";
CM_ SG_ 1360 Cell_overvoltage "Associated DTC: 10";
CM_ SG_ 1360 Cell_undervoltage "Associated DTC: 11, 52";
CM_ SG_ 1360 Comm_failure_with_CMU "Associated DTC: 17";
CM_ SG_ 1360 Internal_CMU_error "Associated DTC: 20, 23, 24, 30, 256, 278";
CM_ SG_ 1360 Internal_CMU_temperature_error "Associated DTC: 25";
CM_ SG_ 1360 Internal_CMU_voltage_reference "Associated DTC: 26";
CM_ SG_ 1360 Cell_shortcircuit "Associated DTC: 27";
CM_ SG_ 1360 Battery_overcurrent "Associated DTC: 28";
CM_ SG_ 1360 Overload_ratio_exceeded "Associated DTC: 164";
CM_ SG_ 1360 Current_sensor_errors "Associated DTC: 22, 34, 79, 167, 229, 239, 277";
CM_ SG_ 1360 BMU_temperature_errors "Associated DTC: 169, 264";
CM_ SG_ 1360 Cell_overtemperature "Associated DTC: 12";
CM_ SG_ 1360 Cell_undertemperature "Associated DTC: 13";
CM_ SG_ 1360 Balancing_overtemperature "Associated DTC: 14";
CM_ SG_ 1360 Balancing_undertemperature "Associated DTC: 15";
CM_ SG_ 1360 Max_op_cell_temp_delta "Associated DTC: 32";
CM_ SG_ 1360 Thermal_runaway "Associated DTC: 16";
CM_ SG_ 1360 OW_and_SC_detected_on_cell "Associated DTC: 31";
CM_ SG_ 1360 BMU_external_overtemperature "Associated DTC: 261, 262, 263";
CM_ SG_ 1360 Battery_undervoltage "Associated DTC: 29";
CM_ SG_ 1360 BMU_supply_voltage_error "Associated DTC: 168";
CM_ SG_ 1360 Battery_overvoltage "Associated DTC: 18";
CM_ SG_ 1360 Cells_unbalanced "Associated DTC: 33, 265";
CM_ SG_ 1360 Advanced_relaxation_voltage_delt "Associated DTC: 19";
CM_ SG_ 1360 Internal_BMU_error "Associated DTC: 63, 77, 170, 176, 183, 184, 249, 260";
CM_ SG_ 1360 Safety_sensor_error "Associated DTC: 246";
CM_ SG_ 1360 High_voltage_sensor_errors "Associated DTC: 61, 240, 273, 274, 275";
CM_ SG_ 1360 IMD_errors "Associated DTC: 276, 279";
CM_ SG_ 1360 Isolation_error "Associated DTC: 174";
CM_ SG_ 1360 BMU_SoC_errors "Associted DTC: 35, 36, 55";
CM_ SG_ 1360 BMU_SoH_error "Associated DTC: 37";
CM_ SG_ 1360 Contactor_stuck_open_errors "Associated DTC: 73, 269, 270";
CM_ SG_ 1360 Contactor_stuck_closed_errors "Associated DTC: 252, 253, 254, 271, 272";
CM_ SG_ 1360 Contactor_supply_error "Associated DTC: 76";
CM_ SG_ 1360 Contactor_precharge_error "Associated DTC: 75";
CM_ SG_ 1360 Emergency_button_error "Associated DTC: 175";
CM_ SG_ 1360 Actuation_errors "Associated DTC: 91, 186";
CM_ SG_ 1360 Auto_OFF "Associated DTC: 185";
CM_ SG_ 1360 Mode_mismatch "Associated DTC: 250";
CM_ SG_ 1360 Open_wire_errors "Associated DTC: 21, 257";
CM_ SG_ 1360 Output_driver_errors_diagnostics "Associated DTC: 74, 78";
CM_ SG_ 1360 User_forced_errors "Associated DTC: 89, 94";
CM_ SG_ 1360 SD_error "Associated DTC: 177";
CM_ SG_ 1360 Ethernet_module_error "Associated DTC: 6";
CM_ SG_ 1360 Internal_memory_errors "Associated DTC: 83, 84, 85, 212";
CM_ SG_ 1361 System_errors "Associated DTC: 156, 157, 158, 159, 160, 162, 163, 197, 228, 266, 267";
CM_ SG_ 1361 Architecture_configuration_error "Associated DTC: 187, 189, 190, 191, 192, 193, 194, 195";
CM_ SG_ 1361 Parallelization_voltage_errors "Associated DTC: 280";
CM_ SG_ 1361 General_configuration_errors "Associated DTC: 67, 69, 70, 72, 244, 245, 268";
CM_ SG_ 1361 Parallelization_comm_lost_primar "Associated DTC: 243";
CM_ SG_ 1361 Cell_overvoltage "Associated DTC: 10";
CM_ SG_ 1361 Cell_undervoltage "Associated DTC: 11, 52";
CM_ SG_ 1361 Comm_failure_with_CMU "Associated DTC: 17";
CM_ SG_ 1361 Internal_CMU_error "Associated DTC: 20, 23, 24, 30, 256, 278";
CM_ SG_ 1361 Internal_CMU_temperature_error "Associated DTC: 25";
CM_ SG_ 1361 Internal_CMU_voltage_reference "Associated DTC: 26";
CM_ SG_ 1361 Cell_shortcircuit "Associated DTC: 27";
CM_ SG_ 1361 Battery_overcurrent "Associated DTC: 28";
CM_ SG_ 1361 Overload_ratio_exceeded "Associated DTC: 164";
CM_ SG_ 1361 Current_sensor_errors "Associated DTC: 22, 34, 79, 167, 229, 239, 277";
CM_ SG_ 1361 BMU_temperature_errors "Associated DTC: 169, 264";
CM_ SG_ 1361 Cell_overtemperature "Associated DTC: 12";
CM_ SG_ 1361 Cell_undertemperature "Associated DTC: 13";
CM_ SG_ 1361 Balancing_overtemperature "Associated DTC: 14";
CM_ SG_ 1361 Balancing_undertemperature "Associated DTC: 15";
CM_ SG_ 1361 Max_op_cell_temp_delta "Associated DTC: 32";
CM_ SG_ 1361 Thermal_runaway "Associated DTC: 16";
CM_ SG_ 1361 OW_and_SC_detected_on_cell "Associated DTC: 31";
CM_ SG_ 1361 BMU_external_overtemperature "Associated DTC: 261, 262, 263";
CM_ SG_ 1361 Battery_undervoltage "Associated DTC: 29";
CM_ SG_ 1361 BMU_supply_voltage_error "Associated DTC: 168";
CM_ SG_ 1361 Battery_overvoltage "Associated DTC: 18";
CM_ SG_ 1361 Cells_unbalanced "Associated DTC: 33, 265";
CM_ SG_ 1361 Advanced_relaxation_voltage_delt "Associated DTC: 19";
CM_ SG_ 1361 Internal_BMU_error "Associated DTC: 63, 77, 170, 176, 183, 184, 249, 260";
CM_ SG_ 1361 Safety_sensor_error "Associated DTC: 246";
CM_ SG_ 1361 High_voltage_sensor_errors "Associated DTC: 61, 240, 273, 274, 275";
CM_ SG_ 1361 IMD_errors "Associated DTC: 276, 279";
CM_ SG_ 1361 Isolation_error "Associated DTC: 174";
CM_ SG_ 1361 BMU_SoC_errors "Associted DTC: 35, 36, 55";
CM_ SG_ 1361 BMU_SoH_error "Associated DTC: 37";
CM_ SG_ 1361 Contactor_stuck_open_errors "Associated DTC: 73, 269, 270";
CM_ SG_ 1361 Contactor_stuck_closed_errors "Associated DTC: 252, 253, 254, 271, 272";
CM_ SG_ 1361 Contactor_supply_error "Associated DTC: 76";
CM_ SG_ 1361 Contactor_precharge_error "Associated DTC: 75";
CM_ SG_ 1361 Emergency_button_error "Associated DTC: 175";
CM_ SG_ 1361 Actuation_errors "Associated DTC: 91, 186";
CM_ SG_ 1361 Auto_OFF "Associated DTC: 185";
CM_ SG_ 1361 Mode_mismatch "Associated DTC: 250";
CM_ SG_ 1361 Open_wire_errors "Associated DTC: 21, 257";
CM_ SG_ 1361 Output_driver_errors_diagnostics "Associated DTC: 74, 78";
CM_ SG_ 1361 User_forced_errors "Associated DTC: 89, 94";
CM_ SG_ 1361 SD_error "Associated DTC: 177";
CM_ SG_ 1361 Ethernet_module_error "Associated DTC: 6";
CM_ SG_ 1361 Internal_memory_errors "Associated DTC: 83, 84, 85, 212";
CM_ SG_ 1362 System_errors "Associated DTC: 156, 157, 158, 159, 160, 162, 163, 197, 228, 266, 267";
CM_ SG_ 1362 Architecture_configuration_error "Associated DTC: 187, 189, 190, 191, 192, 193, 194, 195";
CM_ SG_ 1362 Parallelization_voltage_errors "Associated DTC: 280";
CM_ SG_ 1362 General_configuration_errors "Associated DTC: 67, 69, 70, 72, 244, 245, 268";
CM_ SG_ 1362 Parallelization_comm_lost_primar "Associated DTC: 243";
CM_ SG_ 1362 Cell_overvoltage "Associated DTC: 10";
CM_ SG_ 1362 Cell_undervoltage "Associated DTC: 11, 52";
CM_ SG_ 1362 Comm_failure_with_CMU "Associated DTC: 17";
CM_ SG_ 1362 Internal_CMU_error "Associated DTC: 20, 23, 24, 30, 256, 278";
CM_ SG_ 1362 Internal_CMU_temperature_error "Associated DTC: 25";
CM_ SG_ 1362 Internal_CMU_voltage_reference "Associated DTC: 26";
CM_ SG_ 1362 Cell_shortcircuit "Associated DTC: 27";
CM_ SG_ 1362 Battery_overcurrent "Associated DTC: 28";
CM_ SG_ 1362 Overload_ratio_exceeded "Associated DTC: 164";
CM_ SG_ 1362 Current_sensor_errors "Associated DTC: 22, 34, 79, 167, 229, 239, 277";
CM_ SG_ 1362 BMU_temperature_errors "Associated DTC: 169, 264";
CM_ SG_ 1362 Cell_overtemperature "Associated DTC: 12";
CM_ SG_ 1362 Cell_undertemperature "Associated DTC: 13";
CM_ SG_ 1362 Balancing_overtemperature "Associated DTC: 14";
CM_ SG_ 1362 Balancing_undertemperature "Associated DTC: 15";
CM_ SG_ 1362 Max_op_cell_temp_delta "Associated DTC: 32";
CM_ SG_ 1362 Thermal_runaway "Associated DTC: 16";
CM_ SG_ 1362 OW_and_SC_detected_on_cell "Associated DTC: 31";
CM_ SG_ 1362 BMU_external_overtemperature "Associated DTC: 261, 262, 263";
CM_ SG_ 1362 Battery_undervoltage "Associated DTC: 29";
CM_ SG_ 1362 BMU_supply_voltage_error "Associated DTC: 168";
CM_ SG_ 1362 Battery_overvoltage "Associated DTC: 18";
CM_ SG_ 1362 Cells_unbalanced "Associated DTC: 33, 265";
CM_ SG_ 1362 Advanced_relaxation_voltage_delt "Associated DTC: 19";
CM_ SG_ 1362 Internal_BMU_error "Associated DTC: 63, 77, 170, 176, 183, 184, 249, 260";
CM_ SG_ 1362 Safety_sensor_error "Associated DTC: 246";
CM_ SG_ 1362 High_voltage_sensor_errors "Associated DTC: 61, 240, 273, 274, 275";
CM_ SG_ 1362 IMD_errors "Associated DTC: 276, 279";
CM_ SG_ 1362 Isolation_error "Associated DTC: 174";
CM_ SG_ 1362 BMU_SoC_errors "Associted DTC: 35, 36, 55";
CM_ SG_ 1362 BMU_SoH_error "Associated DTC: 37";
CM_ SG_ 1362 Contactor_stuck_open_errors "Associated DTC: 73, 269, 270";
CM_ SG_ 1362 Contactor_stuck_closed_errors "Associated DTC: 252, 253, 254, 271, 272";
CM_ SG_ 1362 Contactor_supply_error "Associated DTC: 76";
CM_ SG_ 1362 Contactor_precharge_error "Associated DTC: 75";
CM_ SG_ 1362 Emergency_button_error "Associated DTC: 175";
CM_ SG_ 1362 Actuation_errors "Associated DTC: 91, 186";
CM_ SG_ 1362 Auto_OFF "Associated DTC: 185";
CM_ SG_ 1362 Mode_mismatch "Associated DTC: 250";
CM_ SG_ 1362 Open_wire_errors "Associated DTC: 21, 257";
CM_ SG_ 1362 Output_driver_errors_diagnostics "Associated DTC: 74, 78";
CM_ SG_ 1362 User_forced_errors "Associated DTC: 89, 94";
CM_ SG_ 1362 SD_error "Associated DTC: 177";
CM_ SG_ 1362 Ethernet_module_error "Associated DTC: 6";
CM_ SG_ 1362 Internal_memory_errors "Associated DTC: 83, 84, 85, 212";
CM_ SG_ 1363 System_errors "Associated DTC: 156, 157, 158, 159, 160, 162, 163, 197, 228, 266, 267";
CM_ SG_ 1363 Architecture_configuration_error "Associated DTC: 187, 189, 190, 191, 192, 193, 194, 195";
CM_ SG_ 1363 Parallelization_voltage_errors "Associated DTC: 280";
CM_ SG_ 1363 General_configuration_errors "Associated DTC: 67, 69, 70, 72, 244, 245, 268";
CM_ SG_ 1363 Parallelization_comm_lost_primar "Associated DTC: 243";
CM_ SG_ 1363 Cell_overvoltage "Associated DTC: 10";
CM_ SG_ 1363 Cell_undervoltage "Associated DTC: 11, 52";
CM_ SG_ 1363 Comm_failure_with_CMU "Associated DTC: 17";
CM_ SG_ 1363 Internal_CMU_error "Associated DTC: 20, 23, 24, 30, 256, 278";
CM_ SG_ 1363 Internal_CMU_temperature_error "Associated DTC: 25";
CM_ SG_ 1363 Internal_CMU_voltage_reference "Associated DTC: 26";
CM_ SG_ 1363 Cell_shortcircuit "Associated DTC: 27";
CM_ SG_ 1363 Battery_overcurrent "Associated DTC: 28";
CM_ SG_ 1363 Overload_ratio_exceeded "Associated DTC: 164";
CM_ SG_ 1363 Current_sensor_errors "Associated DTC: 22, 34, 79, 167, 229, 239, 277";
CM_ SG_ 1363 BMU_temperature_errors "Associated DTC: 169, 264";
CM_ SG_ 1363 Cell_overtemperature "Associated DTC: 12";
CM_ SG_ 1363 Cell_undertemperature "Associated DTC: 13";
CM_ SG_ 1363 Balancing_overtemperature "Associated DTC: 14";
CM_ SG_ 1363 Balancing_undertemperature "Associated DTC: 15";
CM_ SG_ 1363 Max_op_cell_temp_delta "Associated DTC: 32";
CM_ SG_ 1363 Thermal_runaway "Associated DTC: 16";
CM_ SG_ 1363 OW_and_SC_detected_on_cell "Associated DTC: 31";
CM_ SG_ 1363 BMU_external_overtemperature "Associated DTC: 261, 262, 263";
CM_ SG_ 1363 Battery_undervoltage "Associated DTC: 29";
CM_ SG_ 1363 BMU_supply_voltage_error "Associated DTC: 168";
CM_ SG_ 1363 Battery_overvoltage "Associated DTC: 18";
CM_ SG_ 1363 Cells_unbalanced "Associated DTC: 33, 265";
CM_ SG_ 1363 Advanced_relaxation_voltage_delt "Associated DTC: 19";
CM_ SG_ 1363 Internal_BMU_error "Associated DTC: 63, 77, 170, 176, 183, 184, 249, 260";
CM_ SG_ 1363 Safety_sensor_error "Associated DTC: 246";
CM_ SG_ 1363 High_voltage_sensor_errors "Associated DTC: 61, 240, 273, 274, 275";
CM_ SG_ 1363 IMD_errors "Associated DTC: 276, 279";
CM_ SG_ 1363 Isolation_error "Associated DTC: 174";
CM_ SG_ 1363 BMU_SoC_errors "Associted DTC: 35, 36, 55";
CM_ SG_ 1363 BMU_SoH_error "Associated DTC: 37";
CM_ SG_ 1363 Contactor_stuck_open_errors "Associated DTC: 73, 269, 270";
CM_ SG_ 1363 Contactor_stuck_closed_errors "Associated DTC: 252, 253, 254, 271, 272";
CM_ SG_ 1363 Contactor_supply_error "Associated DTC: 76";
CM_ SG_ 1363 Contactor_precharge_error "Associated DTC: 75";
CM_ SG_ 1363 Emergency_button_error "Associated DTC: 175";
CM_ SG_ 1363 Actuation_errors "Associated DTC: 91, 186";
CM_ SG_ 1363 Auto_OFF "Associated DTC: 185";
CM_ SG_ 1363 Mode_mismatch "Associated DTC: 250";
CM_ SG_ 1363 Open_wire_errors "Associated DTC: 21, 257";
CM_ SG_ 1363 Output_driver_errors_diagnostics "Associated DTC: 74, 78";
CM_ SG_ 1363 User_forced_errors "Associated DTC: 89, 94";
CM_ SG_ 1363 SD_error "Associated DTC: 177";
CM_ SG_ 1363 Ethernet_module_error "Associated DTC: 6";
CM_ SG_ 1363 Internal_memory_errors "Associated DTC: 83, 84, 85, 212";
CM_ SG_ 1364 System_errors "Associated DTC: 156, 157, 158, 159, 160, 162, 163, 197, 228, 266, 267";
CM_ SG_ 1364 Architecture_configuration_error "Associated DTC: 187, 189, 190, 191, 192, 193, 194, 195";
CM_ SG_ 1364 Parallelization_voltage_errors "Associated DTC: 280";
CM_ SG_ 1364 General_configuration_errors "Associated DTC: 67, 69, 70, 72, 244, 245, 268";
CM_ SG_ 1364 Parallelization_comm_lost_primar "Associated DTC: 243";
CM_ SG_ 1364 Cell_overvoltage "Associated DTC: 10";
CM_ SG_ 1364 Cell_undervoltage "Associated DTC: 11, 52";
CM_ SG_ 1364 Comm_failure_with_CMU "Associated DTC: 17";
CM_ SG_ 1364 Internal_CMU_error "Associated DTC: 20, 23, 24, 30, 256, 278";
CM_ SG_ 1364 Internal_CMU_temperature_error "Associated DTC: 25";
CM_ SG_ 1364 Internal_CMU_voltage_reference "Associated DTC: 26";
CM_ SG_ 1364 Cell_shortcircuit "Associated DTC: 27";
CM_ SG_ 1364 Battery_overcurrent "Associated DTC: 28";
CM_ SG_ 1364 Overload_ratio_exceeded "Associated DTC: 164";
CM_ SG_ 1364 Current_sensor_errors "Associated DTC: 22, 34, 79, 167, 229, 239, 277";
CM_ SG_ 1364 BMU_temperature_errors "Associated DTC: 169, 264";
CM_ SG_ 1364 Cell_overtemperature "Associated DTC: 12";
CM_ SG_ 1364 Cell_undertemperature "Associated DTC: 13";
CM_ SG_ 1364 Balancing_overtemperature "Associated DTC: 14";
CM_ SG_ 1364 Balancing_undertemperature "Associated DTC: 15";
CM_ SG_ 1364 Max_op_cell_temp_delta "Associated DTC: 32";
CM_ SG_ 1364 Thermal_runaway "Associated DTC: 16";
CM_ SG_ 1364 OW_and_SC_detected_on_cell "Associated DTC: 31";
CM_ SG_ 1364 BMU_external_overtemperature "Associated DTC: 261, 262, 263";
CM_ SG_ 1364 Battery_undervoltage "Associated DTC: 29";
CM_ SG_ 1364 BMU_supply_voltage_error "Associated DTC: 168";
CM_ SG_ 1364 Battery_overvoltage "Associated DTC: 18";
CM_ SG_ 1364 Cells_unbalanced "Associated DTC: 33, 265";
CM_ SG_ 1364 Advanced_relaxation_voltage_delt "Associated DTC: 19";
CM_ SG_ 1364 Internal_BMU_error "Associated DTC: 63, 77, 170, 176, 183, 184, 249, 260";
CM_ SG_ 1364 Safety_sensor_error "Associated DTC: 246";
CM_ SG_ 1364 High_voltage_sensor_errors "Associated DTC: 61, 240, 273, 274, 275";
CM_ SG_ 1364 IMD_errors "Associated DTC: 276, 279";
CM_ SG_ 1364 Isolation_error "Associated DTC: 174";
CM_ SG_ 1364 BMU_SoC_errors "Associted DTC: 35, 36, 55";
CM_ SG_ 1364 BMU_SoH_error "Associated DTC: 37";
CM_ SG_ 1364 Contactor_stuck_open_errors "Associated DTC: 73, 269, 270";
CM_ SG_ 1364 Contactor_stuck_closed_errors "Associated DTC: 252, 253, 254, 271, 272";
CM_ SG_ 1364 Contactor_supply_error "Associated DTC: 76";
CM_ SG_ 1364 Contactor_precharge_error "Associated DTC: 75";
CM_ SG_ 1364 Emergency_button_error "Associated DTC: 175";
CM_ SG_ 1364 Actuation_errors "Associated DTC: 91, 186";
CM_ SG_ 1364 Auto_OFF "Associated DTC: 185";
CM_ SG_ 1364 Mode_mismatch "Associated DTC: 250";
CM_ SG_ 1364 Open_wire_errors "Associated DTC: 21, 257";
CM_ SG_ 1364 Output_driver_errors_diagnostics "Associated DTC: 74, 78";
CM_ SG_ 1364 User_forced_errors "Associated DTC: 89, 94";
CM_ SG_ 1364 SD_error "Associated DTC: 177";
CM_ SG_ 1364 Ethernet_module_error "Associated DTC: 6";
CM_ SG_ 1364 Internal_memory_errors "Associated DTC: 83, 84, 85, 212";
VAL_ 1296 BMU_status 0 "INIT" 1 "READY" 2 "ACTIVE" 3 "FAILURE" ;
VAL_ 1296 System_error_flag 0 "RESET" 1 "SET" ;
VAL_ 1296 Stop_charge_flag 0 "CHARGE_IS_ALLOWED" 1 "CHARGE_IS_NOT_ALLOWED" ;
VAL_ 1296 Stop_discharge_flag 0 "DISCHARGE_IS_ALLOWED" 1 "DISCHARGE_IS_NOT_ALLOWED" ;
VAL_ 1296 Reconnection_time_interlock_flag 0 "RESET" 1 "SET" ;
VAL_ 1296 Advanced_BMU_status 0 "RESERVED " 1 "BATTERY_STATUS_BMU_STATUS_INITIALIZING" 2 "BATTERY_STATUS_BMU_STATUS_DISCONNECTED" 3 "BATTERY_STATUS_BMU_STATUS_CONNECTING" 4 "BATTERY_STATUS_BMU_STATUS_CONNECTED" 5 "BATTERY_STATUS_BMU_STATUS_BMU_ERROR" 6 "BATTERY_STATUS_BMU_STATUS_SYSTEM_ERROR" 7 "RESERVED" 8 "BATTERY_STATUS_BMU_STATUS_DISCONNECTING" 9 "BATTERY_STATUS_BMU_STATUS_ERROR_DISCONNECTING" 10 "RESERVED" ;
VAL_ 1296 Charge_Discharge_control_state 0 "CURRENT_STATE_NOMINAL" 1 "CURRENT_STATE_CURRENT_CORRECTION" 2 "CURRENT_STATE_CV_CHARGE" 3 "CURRENT_STATE_CHARGED" 4 "CURRENT_STATE_TOPPING_CHARGE" 5 "CURRENT_STATE_OVER_CHARGED" 6 "CURRENT_STATE_CV_DISCHARGE" 7 "CURRENT_STATE_DISCHARGED" 8 "CURRENT_STATE_OVER_DISCHARGED" 9 "CURRENT_STATE_OVER_DISCHARGE_RECOVERY" 10 "CURRENT_STATE_DEEPLY_DISCHARGED" ;
VAL_ 1296 Fully_charged_flag 0 "IDLE" 1 "ACTIVE" ;
VAL_ 1297 BMU_status 0 "INIT" 1 "READY" 2 "ACTIVE" 3 "FAILURE" ;
VAL_ 1297 System_error_flag 0 "RESET" 1 "SET" ;
VAL_ 1297 Stop_charge_flag 0 "CHARGE_IS_ALLOWED" 1 "CHARGE_IS_NOT_ALLOWED" ;
VAL_ 1297 Stop_discharge_flag 0 "DISCHARGE_IS_ALLOWED" 1 "DISCHARGE_IS_NOT_ALLOWED" ;
VAL_ 1297 Reconnection_time_interlock_flag 0 "RESET" 1 "SET" ;
VAL_ 1297 Advanced_BMU_status 0 "RESERVED " 1 "BATTERY_STATUS_BMU_STATUS_INITIALIZING" 2 "BATTERY_STATUS_BMU_STATUS_DISCONNECTED" 3 "BATTERY_STATUS_BMU_STATUS_CONNECTING" 4 "BATTERY_STATUS_BMU_STATUS_CONNECTED" 5 "BATTERY_STATUS_BMU_STATUS_BMU_ERROR" 6 "BATTERY_STATUS_BMU_STATUS_SYSTEM_ERROR" 7 "RESERVED" 8 "BATTERY_STATUS_BMU_STATUS_DISCONNECTING" 9 "BATTERY_STATUS_BMU_STATUS_ERROR_DISCONNECTING" 10 "RESERVED" ;
VAL_ 1297 Charge_Discharge_control_state 0 "CURRENT_STATE_NOMINAL" 1 "CURRENT_STATE_CURRENT_CORRECTION" 2 "CURRENT_STATE_CV_CHARGE" 3 "CURRENT_STATE_CHARGED" 4 "CURRENT_STATE_TOPPING_CHARGE" 5 "CURRENT_STATE_OVER_CHARGED" 6 "CURRENT_STATE_CV_DISCHARGE" 7 "CURRENT_STATE_DISCHARGED" 8 "CURRENT_STATE_OVER_DISCHARGED" 9 "CURRENT_STATE_OVER_DISCHARGE_RECOVERY" 10 "CURRENT_STATE_DEEPLY_DISCHARGED" ;
VAL_ 1297 Fully_charged_flag 0 "IDLE" 1 "ACTIVE" ;
VAL_ 1298 BMU_status 0 "INIT" 1 "READY" 2 "ACTIVE" 3 "FAILURE" ;
VAL_ 1298 System_error_flag 0 "RESET" 1 "SET" ;
VAL_ 1298 Stop_charge_flag 0 "CHARGE_IS_ALLOWED" 1 "CHARGE_IS_NOT_ALLOWED" ;
VAL_ 1298 Stop_discharge_flag 0 "DISCHARGE_IS_ALLOWED" 1 "DISCHARGE_IS_NOT_ALLOWED" ;
VAL_ 1298 Reconnection_time_interlock_flag 0 "RESET" 1 "SET" ;
VAL_ 1298 Advanced_BMU_status 0 "RESERVED " 1 "BATTERY_STATUS_BMU_STATUS_INITIALIZING" 2 "BATTERY_STATUS_BMU_STATUS_DISCONNECTED" 3 "BATTERY_STATUS_BMU_STATUS_CONNECTING" 4 "BATTERY_STATUS_BMU_STATUS_CONNECTED" 5 "BATTERY_STATUS_BMU_STATUS_BMU_ERROR" 6 "BATTERY_STATUS_BMU_STATUS_SYSTEM_ERROR" 7 "RESERVED" 8 "BATTERY_STATUS_BMU_STATUS_DISCONNECTING" 9 "BATTERY_STATUS_BMU_STATUS_ERROR_DISCONNECTING" 10 "RESERVED" ;
VAL_ 1298 Charge_Discharge_control_state 0 "CURRENT_STATE_NOMINAL" 1 "CURRENT_STATE_CURRENT_CORRECTION" 2 "CURRENT_STATE_CV_CHARGE" 3 "CURRENT_STATE_CHARGED" 4 "CURRENT_STATE_TOPPING_CHARGE" 5 "CURRENT_STATE_OVER_CHARGED" 6 "CURRENT_STATE_CV_DISCHARGE" 7 "CURRENT_STATE_DISCHARGED" 8 "CURRENT_STATE_OVER_DISCHARGED" 9 "CURRENT_STATE_OVER_DISCHARGE_RECOVERY" 10 "CURRENT_STATE_DEEPLY_DISCHARGED" ;
VAL_ 1298 Fully_charged_flag 0 "IDLE" 1 "ACTIVE" ;
VAL_ 1299 BMU_status 0 "INIT" 1 "READY" 2 "ACTIVE" 3 "FAILURE" ;
VAL_ 1299 System_error_flag 0 "RESET" 1 "SET" ;
VAL_ 1299 Stop_charge_flag 0 "CHARGE_IS_ALLOWED" 1 "CHARGE_IS_NOT_ALLOWED" ;
VAL_ 1299 Stop_discharge_flag 0 "DISCHARGE_IS_ALLOWED" 1 "DISCHARGE_IS_NOT_ALLOWED" ;
VAL_ 1299 Reconnection_time_interlock_flag 0 "RESET" 1 "SET" ;
VAL_ 1299 Advanced_BMU_status 0 "RESERVED " 1 "BATTERY_STATUS_BMU_STATUS_INITIALIZING" 2 "BATTERY_STATUS_BMU_STATUS_DISCONNECTED" 3 "BATTERY_STATUS_BMU_STATUS_CONNECTING" 4 "BATTERY_STATUS_BMU_STATUS_CONNECTED" 5 "BATTERY_STATUS_BMU_STATUS_BMU_ERROR" 6 "BATTERY_STATUS_BMU_STATUS_SYSTEM_ERROR" 7 "RESERVED" 8 "BATTERY_STATUS_BMU_STATUS_DISCONNECTING" 9 "BATTERY_STATUS_BMU_STATUS_ERROR_DISCONNECTING" 10 "RESERVED" ;
VAL_ 1299 Charge_Discharge_control_state 0 "CURRENT_STATE_NOMINAL" 1 "CURRENT_STATE_CURRENT_CORRECTION" 2 "CURRENT_STATE_CV_CHARGE" 3 "CURRENT_STATE_CHARGED" 4 "CURRENT_STATE_TOPPING_CHARGE" 5 "CURRENT_STATE_OVER_CHARGED" 6 "CURRENT_STATE_CV_DISCHARGE" 7 "CURRENT_STATE_DISCHARGED" 8 "CURRENT_STATE_OVER_DISCHARGED" 9 "CURRENT_STATE_OVER_DISCHARGE_RECOVERY" 10 "CURRENT_STATE_DEEPLY_DISCHARGED" ;
VAL_ 1299 Fully_charged_flag 0 "IDLE" 1 "ACTIVE" ;
VAL_ 1300 BMU_status 0 "INIT" 1 "READY" 2 "ACTIVE" 3 "FAILURE" ;
VAL_ 1300 System_error_flag 0 "RESET" 1 "SET" ;
VAL_ 1300 Stop_charge_flag 0 "CHARGE_IS_ALLOWED" 1 "CHARGE_IS_NOT_ALLOWED" ;
VAL_ 1300 Stop_discharge_flag 0 "DISCHARGE_IS_ALLOWED" 1 "DISCHARGE_IS_NOT_ALLOWED" ;
VAL_ 1300 Reconnection_time_interlock_flag 0 "RESET" 1 "SET" ;
VAL_ 1300 Advanced_BMU_status 0 "RESERVED " 1 "BATTERY_STATUS_BMU_STATUS_INITIALIZING" 2 "BATTERY_STATUS_BMU_STATUS_DISCONNECTED" 3 "BATTERY_STATUS_BMU_STATUS_CONNECTING" 4 "BATTERY_STATUS_BMU_STATUS_CONNECTED" 5 "BATTERY_STATUS_BMU_STATUS_BMU_ERROR" 6 "BATTERY_STATUS_BMU_STATUS_SYSTEM_ERROR" 7 "RESERVED" 8 "BATTERY_STATUS_BMU_STATUS_DISCONNECTING" 9 "BATTERY_STATUS_BMU_STATUS_ERROR_DISCONNECTING" 10 "RESERVED" ;
VAL_ 1300 Charge_Discharge_control_state 0 "CURRENT_STATE_NOMINAL" 1 "CURRENT_STATE_CURRENT_CORRECTION" 2 "CURRENT_STATE_CV_CHARGE" 3 "CURRENT_STATE_CHARGED" 4 "CURRENT_STATE_TOPPING_CHARGE" 5 "CURRENT_STATE_OVER_CHARGED" 6 "CURRENT_STATE_CV_DISCHARGE" 7 "CURRENT_STATE_DISCHARGED" 8 "CURRENT_STATE_OVER_DISCHARGED" 9 "CURRENT_STATE_OVER_DISCHARGE_RECOVERY" 10 "CURRENT_STATE_DEEPLY_DISCHARGED" ;
VAL_ 1300 Fully_charged_flag 0 "IDLE" 1 "ACTIVE" ;
VAL_ 1301 BMU_status 0 "INIT" 1 "READY" 2 "ACTIVE" 3 "FAILURE" ;
VAL_ 1301 System_error_flag 0 "RESET" 1 "SET" ;
VAL_ 1301 Stop_charge_flag 0 "CHARGE_IS_ALLOWED" 1 "CHARGE_IS_NOT_ALLOWED" ;
VAL_ 1301 Stop_discharge_flag 0 "DISCHARGE_IS_ALLOWED" 1 "DISCHARGE_IS_NOT_ALLOWED" ;
VAL_ 1301 Reconnection_time_interlock_flag 0 "RESET" 1 "SET" ;
VAL_ 1301 Advanced_BMU_status 0 "RESERVED " 1 "BATTERY_STATUS_BMU_STATUS_INITIALIZING" 2 "BATTERY_STATUS_BMU_STATUS_DISCONNECTED" 3 "BATTERY_STATUS_BMU_STATUS_CONNECTING" 4 "BATTERY_STATUS_BMU_STATUS_CONNECTED" 5 "BATTERY_STATUS_BMU_STATUS_BMU_ERROR" 6 "BATTERY_STATUS_BMU_STATUS_SYSTEM_ERROR" 7 "RESERVED" 8 "BATTERY_STATUS_BMU_STATUS_DISCONNECTING" 9 "BATTERY_STATUS_BMU_STATUS_ERROR_DISCONNECTING" 10 "RESERVED" ;
VAL_ 1301 Charge_Discharge_control_state 0 "CURRENT_STATE_NOMINAL" 1 "CURRENT_STATE_CURRENT_CORRECTION" 2 "CURRENT_STATE_CV_CHARGE" 3 "CURRENT_STATE_CHARGED" 4 "CURRENT_STATE_TOPPING_CHARGE" 5 "CURRENT_STATE_OVER_CHARGED" 6 "CURRENT_STATE_CV_DISCHARGE" 7 "CURRENT_STATE_DISCHARGED" 8 "CURRENT_STATE_OVER_DISCHARGED" 9 "CURRENT_STATE_OVER_DISCHARGE_RECOVERY" 10 "CURRENT_STATE_DEEPLY_DISCHARGED" ;
VAL_ 1301 Fully_charged_flag 0 "IDLE" 1 "ACTIVE" ;
VAL_ 1302 BMU_status 0 "INIT" 1 "READY" 2 "ACTIVE" 3 "FAILURE" ;
VAL_ 1302 System_error_flag 0 "RESET" 1 "SET" ;
VAL_ 1302 Stop_charge_flag 0 "CHARGE_IS_ALLOWED" 1 "CHARGE_IS_NOT_ALLOWED" ;
VAL_ 1302 Stop_discharge_flag 0 "DISCHARGE_IS_ALLOWED" 1 "DISCHARGE_IS_NOT_ALLOWED" ;
VAL_ 1302 Reconnection_time_interlock_flag 0 "RESET" 1 "SET" ;
VAL_ 1302 Advanced_BMU_status 0 "RESERVED " 1 "BATTERY_STATUS_BMU_STATUS_INITIALIZING" 2 "BATTERY_STATUS_BMU_STATUS_DISCONNECTED" 3 "BATTERY_STATUS_BMU_STATUS_CONNECTING" 4 "BATTERY_STATUS_BMU_STATUS_CONNECTED" 5 "BATTERY_STATUS_BMU_STATUS_BMU_ERROR" 6 "BATTERY_STATUS_BMU_STATUS_SYSTEM_ERROR" 7 "RESERVED" 8 "BATTERY_STATUS_BMU_STATUS_DISCONNECTING" 9 "BATTERY_STATUS_BMU_STATUS_ERROR_DISCONNECTING" 10 "RESERVED" ;
VAL_ 1302 Charge_Discharge_control_state 0 "CURRENT_STATE_NOMINAL" 1 "CURRENT_STATE_CURRENT_CORRECTION" 2 "CURRENT_STATE_CV_CHARGE" 3 "CURRENT_STATE_CHARGED" 4 "CURRENT_STATE_TOPPING_CHARGE" 5 "CURRENT_STATE_OVER_CHARGED" 6 "CURRENT_STATE_CV_DISCHARGE" 7 "CURRENT_STATE_DISCHARGED" 8 "CURRENT_STATE_OVER_DISCHARGED" 9 "CURRENT_STATE_OVER_DISCHARGE_RECOVERY" 10 "CURRENT_STATE_DEEPLY_DISCHARGED" ;
VAL_ 1302 Fully_charged_flag 0 "IDLE" 1 "ACTIVE" ;
VAL_ 1303 BMU_status 0 "INIT" 1 "READY" 2 "ACTIVE" 3 "FAILURE" ;
VAL_ 1303 System_error_flag 0 "RESET" 1 "SET" ;
VAL_ 1303 Stop_charge_flag 0 "CHARGE_IS_ALLOWED" 1 "CHARGE_IS_NOT_ALLOWED" ;
VAL_ 1303 Stop_discharge_flag 0 "DISCHARGE_IS_ALLOWED" 1 "DISCHARGE_IS_NOT_ALLOWED" ;
VAL_ 1303 Reconnection_time_interlock_flag 0 "RESET" 1 "SET" ;
VAL_ 1303 Advanced_BMU_status 0 "RESERVED " 1 "BATTERY_STATUS_BMU_STATUS_INITIALIZING" 2 "BATTERY_STATUS_BMU_STATUS_DISCONNECTED" 3 "BATTERY_STATUS_BMU_STATUS_CONNECTING" 4 "BATTERY_STATUS_BMU_STATUS_CONNECTED" 5 "BATTERY_STATUS_BMU_STATUS_BMU_ERROR" 6 "BATTERY_STATUS_BMU_STATUS_SYSTEM_ERROR" 7 "RESERVED" 8 "BATTERY_STATUS_BMU_STATUS_DISCONNECTING" 9 "BATTERY_STATUS_BMU_STATUS_ERROR_DISCONNECTING" 10 "RESERVED" ;
VAL_ 1303 Charge_Discharge_control_state 0 "CURRENT_STATE_NOMINAL" 1 "CURRENT_STATE_CURRENT_CORRECTION" 2 "CURRENT_STATE_CV_CHARGE" 3 "CURRENT_STATE_CHARGED" 4 "CURRENT_STATE_TOPPING_CHARGE" 5 "CURRENT_STATE_OVER_CHARGED" 6 "CURRENT_STATE_CV_DISCHARGE" 7 "CURRENT_STATE_DISCHARGED" 8 "CURRENT_STATE_OVER_DISCHARGED" 9 "CURRENT_STATE_OVER_DISCHARGE_RECOVERY" 10 "CURRENT_STATE_DEEPLY_DISCHARGED" ;
VAL_ 1303 Fully_charged_flag 0 "IDLE" 1 "ACTIVE" ;
VAL_ 1304 BMU_status 0 "INIT" 1 "READY" 2 "ACTIVE" 3 "FAILURE" ;
VAL_ 1304 System_error_flag 0 "RESET" 1 "SET" ;
VAL_ 1304 Stop_charge_flag 0 "CHARGE_IS_ALLOWED" 1 "CHARGE_IS_NOT_ALLOWED" ;
VAL_ 1304 Stop_discharge_flag 0 "DISCHARGE_IS_ALLOWED" 1 "DISCHARGE_IS_NOT_ALLOWED" ;
VAL_ 1304 Reconnection_time_interlock_flag 0 "RESET" 1 "SET" ;
VAL_ 1304 Advanced_BMU_status 0 "RESERVED " 1 "BATTERY_STATUS_BMU_STATUS_INITIALIZING" 2 "BATTERY_STATUS_BMU_STATUS_DISCONNECTED" 3 "BATTERY_STATUS_BMU_STATUS_CONNECTING" 4 "BATTERY_STATUS_BMU_STATUS_CONNECTED" 5 "BATTERY_STATUS_BMU_STATUS_BMU_ERROR" 6 "BATTERY_STATUS_BMU_STATUS_SYSTEM_ERROR" 7 "RESERVED" 8 "BATTERY_STATUS_BMU_STATUS_DISCONNECTING" 9 "BATTERY_STATUS_BMU_STATUS_ERROR_DISCONNECTING" 10 "RESERVED" ;
VAL_ 1304 Charge_Discharge_control_state 0 "CURRENT_STATE_NOMINAL" 1 "CURRENT_STATE_CURRENT_CORRECTION" 2 "CURRENT_STATE_CV_CHARGE" 3 "CURRENT_STATE_CHARGED" 4 "CURRENT_STATE_TOPPING_CHARGE" 5 "CURRENT_STATE_OVER_CHARGED" 6 "CURRENT_STATE_CV_DISCHARGE" 7 "CURRENT_STATE_DISCHARGED" 8 "CURRENT_STATE_OVER_DISCHARGED" 9 "CURRENT_STATE_OVER_DISCHARGE_RECOVERY" 10 "CURRENT_STATE_DEEPLY_DISCHARGED" ;
VAL_ 1304 Fully_charged_flag 0 "IDLE" 1 "ACTIVE" ;
VAL_ 1305 BMU_status 0 "INIT" 1 "READY" 2 "ACTIVE" 3 "FAILURE" ;
VAL_ 1305 System_error_flag 0 "RESET" 1 "SET" ;
VAL_ 1305 Stop_charge_flag 0 "CHARGE_IS_ALLOWED" 1 "CHARGE_IS_NOT_ALLOWED" ;
VAL_ 1305 Stop_discharge_flag 0 "DISCHARGE_IS_ALLOWED" 1 "DISCHARGE_IS_NOT_ALLOWED" ;
VAL_ 1305 Reconnection_time_interlock_flag 0 "RESET" 1 "SET" ;
VAL_ 1305 Advanced_BMU_status 0 "RESERVED " 1 "BATTERY_STATUS_BMU_STATUS_INITIALIZING" 2 "BATTERY_STATUS_BMU_STATUS_DISCONNECTED" 3 "BATTERY_STATUS_BMU_STATUS_CONNECTING" 4 "BATTERY_STATUS_BMU_STATUS_CONNECTED" 5 "BATTERY_STATUS_BMU_STATUS_BMU_ERROR" 6 "BATTERY_STATUS_BMU_STATUS_SYSTEM_ERROR" 7 "RESERVED" 8 "BATTERY_STATUS_BMU_STATUS_DISCONNECTING" 9 "BATTERY_STATUS_BMU_STATUS_ERROR_DISCONNECTING" 10 "RESERVED" ;
VAL_ 1305 Charge_Discharge_control_state 0 "CURRENT_STATE_NOMINAL" 1 "CURRENT_STATE_CURRENT_CORRECTION" 2 "CURRENT_STATE_CV_CHARGE" 3 "CURRENT_STATE_CHARGED" 4 "CURRENT_STATE_TOPPING_CHARGE" 5 "CURRENT_STATE_OVER_CHARGED" 6 "CURRENT_STATE_CV_DISCHARGE" 7 "CURRENT_STATE_DISCHARGED" 8 "CURRENT_STATE_OVER_DISCHARGED" 9 "CURRENT_STATE_OVER_DISCHARGE_RECOVERY" 10 "CURRENT_STATE_DEEPLY_DISCHARGED" ;
VAL_ 1305 Fully_charged_flag 0 "IDLE" 1 "ACTIVE" ;
VAL_ 1306 BMU_status 0 "INIT" 1 "READY" 2 "ACTIVE" 3 "FAILURE" ;
VAL_ 1306 System_error_flag 0 "RESET" 1 "SET" ;
VAL_ 1306 Stop_charge_flag 0 "CHARGE_IS_ALLOWED" 1 "CHARGE_IS_NOT_ALLOWED" ;
VAL_ 1306 Stop_discharge_flag 0 "DISCHARGE_IS_ALLOWED" 1 "DISCHARGE_IS_NOT_ALLOWED" ;
VAL_ 1306 Reconnection_time_interlock_flag 0 "RESET" 1 "SET" ;
VAL_ 1306 Advanced_BMU_status 0 "RESERVED " 1 "BATTERY_STATUS_BMU_STATUS_INITIALIZING" 2 "BATTERY_STATUS_BMU_STATUS_DISCONNECTED" 3 "BATTERY_STATUS_BMU_STATUS_CONNECTING" 4 "BATTERY_STATUS_BMU_STATUS_CONNECTED" 5 "BATTERY_STATUS_BMU_STATUS_BMU_ERROR" 6 "BATTERY_STATUS_BMU_STATUS_SYSTEM_ERROR" 7 "RESERVED" 8 "BATTERY_STATUS_BMU_STATUS_DISCONNECTING" 9 "BATTERY_STATUS_BMU_STATUS_ERROR_DISCONNECTING" 10 "RESERVED" ;
VAL_ 1306 Charge_Discharge_control_state 0 "CURRENT_STATE_NOMINAL" 1 "CURRENT_STATE_CURRENT_CORRECTION" 2 "CURRENT_STATE_CV_CHARGE" 3 "CURRENT_STATE_CHARGED" 4 "CURRENT_STATE_TOPPING_CHARGE" 5 "CURRENT_STATE_OVER_CHARGED" 6 "CURRENT_STATE_CV_DISCHARGE" 7 "CURRENT_STATE_DISCHARGED" 8 "CURRENT_STATE_OVER_DISCHARGED" 9 "CURRENT_STATE_OVER_DISCHARGE_RECOVERY" 10 "CURRENT_STATE_DEEPLY_DISCHARGED" ;
VAL_ 1306 Fully_charged_flag 0 "IDLE" 1 "ACTIVE" ;
VAL_ 1307 BMU_status 0 "INIT" 1 "READY" 2 "ACTIVE" 3 "FAILURE" ;
VAL_ 1307 System_error_flag 0 "RESET" 1 "SET" ;
VAL_ 1307 Stop_charge_flag 0 "CHARGE_IS_ALLOWED" 1 "CHARGE_IS_NOT_ALLOWED" ;
VAL_ 1307 Stop_discharge_flag 0 "DISCHARGE_IS_ALLOWED" 1 "DISCHARGE_IS_NOT_ALLOWED" ;
VAL_ 1307 Reconnection_time_interlock_flag 0 "RESET" 1 "SET" ;
VAL_ 1307 Advanced_BMU_status 0 "RESERVED " 1 "BATTERY_STATUS_BMU_STATUS_INITIALIZING" 2 "BATTERY_STATUS_BMU_STATUS_DISCONNECTED" 3 "BATTERY_STATUS_BMU_STATUS_CONNECTING" 4 "BATTERY_STATUS_BMU_STATUS_CONNECTED" 5 "BATTERY_STATUS_BMU_STATUS_BMU_ERROR" 6 "BATTERY_STATUS_BMU_STATUS_SYSTEM_ERROR" 7 "RESERVED" 8 "BATTERY_STATUS_BMU_STATUS_DISCONNECTING" 9 "BATTERY_STATUS_BMU_STATUS_ERROR_DISCONNECTING" 10 "RESERVED" ;
VAL_ 1307 Charge_Discharge_control_state 0 "CURRENT_STATE_NOMINAL" 1 "CURRENT_STATE_CURRENT_CORRECTION" 2 "CURRENT_STATE_CV_CHARGE" 3 "CURRENT_STATE_CHARGED" 4 "CURRENT_STATE_TOPPING_CHARGE" 5 "CURRENT_STATE_OVER_CHARGED" 6 "CURRENT_STATE_CV_DISCHARGE" 7 "CURRENT_STATE_DISCHARGED" 8 "CURRENT_STATE_OVER_DISCHARGED" 9 "CURRENT_STATE_OVER_DISCHARGE_RECOVERY" 10 "CURRENT_STATE_DEEPLY_DISCHARGED" ;
VAL_ 1307 Fully_charged_flag 0 "IDLE" 1 "ACTIVE" ;
VAL_ 1308 BMU_status 0 "INIT" 1 "READY" 2 "ACTIVE" 3 "FAILURE" ;
VAL_ 1308 System_error_flag 0 "RESET" 1 "SET" ;
VAL_ 1308 Stop_charge_flag 0 "CHARGE_IS_ALLOWED" 1 "CHARGE_IS_NOT_ALLOWED" ;
VAL_ 1308 Stop_discharge_flag 0 "DISCHARGE_IS_ALLOWED" 1 "DISCHARGE_IS_NOT_ALLOWED" ;
VAL_ 1308 Reconnection_time_interlock_flag 0 "RESET" 1 "SET" ;
VAL_ 1308 Advanced_BMU_status 0 "RESERVED " 1 "BATTERY_STATUS_BMU_STATUS_INITIALIZING" 2 "BATTERY_STATUS_BMU_STATUS_DISCONNECTED" 3 "BATTERY_STATUS_BMU_STATUS_CONNECTING" 4 "BATTERY_STATUS_BMU_STATUS_CONNECTED" 5 "BATTERY_STATUS_BMU_STATUS_BMU_ERROR" 6 "BATTERY_STATUS_BMU_STATUS_SYSTEM_ERROR" 7 "RESERVED" 8 "BATTERY_STATUS_BMU_STATUS_DISCONNECTING" 9 "BATTERY_STATUS_BMU_STATUS_ERROR_DISCONNECTING" 10 "RESERVED" ;
VAL_ 1308 Charge_Discharge_control_state 0 "CURRENT_STATE_NOMINAL" 1 "CURRENT_STATE_CURRENT_CORRECTION" 2 "CURRENT_STATE_CV_CHARGE" 3 "CURRENT_STATE_CHARGED" 4 "CURRENT_STATE_TOPPING_CHARGE" 5 "CURRENT_STATE_OVER_CHARGED" 6 "CURRENT_STATE_CV_DISCHARGE" 7 "CURRENT_STATE_DISCHARGED" 8 "CURRENT_STATE_OVER_DISCHARGED" 9 "CURRENT_STATE_OVER_DISCHARGE_RECOVERY" 10 "CURRENT_STATE_DEEPLY_DISCHARGED" ;
VAL_ 1308 Fully_charged_flag 0 "IDLE" 1 "ACTIVE" ;
VAL_ 1309 BMU_status 0 "INIT" 1 "READY" 2 "ACTIVE" 3 "FAILURE" ;
VAL_ 1309 System_error_flag 0 "RESET" 1 "SET" ;
VAL_ 1309 Stop_charge_flag 0 "CHARGE_IS_ALLOWED" 1 "CHARGE_IS_NOT_ALLOWED" ;
VAL_ 1309 Stop_discharge_flag 0 "DISCHARGE_IS_ALLOWED" 1 "DISCHARGE_IS_NOT_ALLOWED" ;
VAL_ 1309 Reconnection_time_interlock_flag 0 "RESET" 1 "SET" ;
VAL_ 1309 Advanced_BMU_status 0 "RESERVED " 1 "BATTERY_STATUS_BMU_STATUS_INITIALIZING" 2 "BATTERY_STATUS_BMU_STATUS_DISCONNECTED" 3 "BATTERY_STATUS_BMU_STATUS_CONNECTING" 4 "BATTERY_STATUS_BMU_STATUS_CONNECTED" 5 "BATTERY_STATUS_BMU_STATUS_BMU_ERROR" 6 "BATTERY_STATUS_BMU_STATUS_SYSTEM_ERROR" 7 "RESERVED" 8 "BATTERY_STATUS_BMU_STATUS_DISCONNECTING" 9 "BATTERY_STATUS_BMU_STATUS_ERROR_DISCONNECTING" 10 "RESERVED" ;
VAL_ 1309 Charge_Discharge_control_state 0 "CURRENT_STATE_NOMINAL" 1 "CURRENT_STATE_CURRENT_CORRECTION" 2 "CURRENT_STATE_CV_CHARGE" 3 "CURRENT_STATE_CHARGED" 4 "CURRENT_STATE_TOPPING_CHARGE" 5 "CURRENT_STATE_OVER_CHARGED" 6 "CURRENT_STATE_CV_DISCHARGE" 7 "CURRENT_STATE_DISCHARGED" 8 "CURRENT_STATE_OVER_DISCHARGED" 9 "CURRENT_STATE_OVER_DISCHARGE_RECOVERY" 10 "CURRENT_STATE_DEEPLY_DISCHARGED" ;
VAL_ 1309 Fully_charged_flag 0 "IDLE" 1 "ACTIVE" ;
VAL_ 1310 BMU_status 0 "INIT" 1 "READY" 2 "ACTIVE" 3 "FAILURE" ;
VAL_ 1310 System_error_flag 0 "RESET" 1 "SET" ;
VAL_ 1310 Stop_charge_flag 0 "CHARGE_IS_ALLOWED" 1 "CHARGE_IS_NOT_ALLOWED" ;
VAL_ 1310 Stop_discharge_flag 0 "DISCHARGE_IS_ALLOWED" 1 "DISCHARGE_IS_NOT_ALLOWED" ;
VAL_ 1310 Reconnection_time_interlock_flag 0 "RESET" 1 "SET" ;
VAL_ 1310 Advanced_BMU_status 0 "RESERVED " 1 "BATTERY_STATUS_BMU_STATUS_INITIALIZING" 2 "BATTERY_STATUS_BMU_STATUS_DISCONNECTED" 3 "BATTERY_STATUS_BMU_STATUS_CONNECTING" 4 "BATTERY_STATUS_BMU_STATUS_CONNECTED" 5 "BATTERY_STATUS_BMU_STATUS_BMU_ERROR" 6 "BATTERY_STATUS_BMU_STATUS_SYSTEM_ERROR" 7 "RESERVED" 8 "BATTERY_STATUS_BMU_STATUS_DISCONNECTING" 9 "BATTERY_STATUS_BMU_STATUS_ERROR_DISCONNECTING" 10 "RESERVED" ;
VAL_ 1310 Charge_Discharge_control_state 0 "CURRENT_STATE_NOMINAL" 1 "CURRENT_STATE_CURRENT_CORRECTION" 2 "CURRENT_STATE_CV_CHARGE" 3 "CURRENT_STATE_CHARGED" 4 "CURRENT_STATE_TOPPING_CHARGE" 5 "CURRENT_STATE_OVER_CHARGED" 6 "CURRENT_STATE_CV_DISCHARGE" 7 "CURRENT_STATE_DISCHARGED" 8 "CURRENT_STATE_OVER_DISCHARGED" 9 "CURRENT_STATE_OVER_DISCHARGE_RECOVERY" 10 "CURRENT_STATE_DEEPLY_DISCHARGED" ;
VAL_ 1310 Fully_charged_flag 0 "IDLE" 1 "ACTIVE" ;
VAL_ 1311 BMU_status 0 "INIT" 1 "READY" 2 "ACTIVE" 3 "FAILURE" ;
VAL_ 1311 System_error_flag 0 "RESET" 1 "SET" ;
VAL_ 1311 Stop_charge_flag 0 "CHARGE_IS_ALLOWED" 1 "CHARGE_IS_NOT_ALLOWED" ;
VAL_ 1311 Stop_discharge_flag 0 "DISCHARGE_IS_ALLOWED" 1 "DISCHARGE_IS_NOT_ALLOWED" ;
VAL_ 1311 Reconnection_time_interlock_flag 0 "RESET" 1 "SET" ;
VAL_ 1311 Advanced_BMU_status 0 "RESERVED " 1 "BATTERY_STATUS_BMU_STATUS_INITIALIZING" 2 "BATTERY_STATUS_BMU_STATUS_DISCONNECTED" 3 "BATTERY_STATUS_BMU_STATUS_CONNECTING" 4 "BATTERY_STATUS_BMU_STATUS_CONNECTED" 5 "BATTERY_STATUS_BMU_STATUS_BMU_ERROR" 6 "BATTERY_STATUS_BMU_STATUS_SYSTEM_ERROR" 7 "RESERVED" 8 "BATTERY_STATUS_BMU_STATUS_DISCONNECTING" 9 "BATTERY_STATUS_BMU_STATUS_ERROR_DISCONNECTING" 10 "RESERVED" ;
VAL_ 1311 Charge_Discharge_control_state 0 "CURRENT_STATE_NOMINAL" 1 "CURRENT_STATE_CURRENT_CORRECTION" 2 "CURRENT_STATE_CV_CHARGE" 3 "CURRENT_STATE_CHARGED" 4 "CURRENT_STATE_TOPPING_CHARGE" 5 "CURRENT_STATE_OVER_CHARGED" 6 "CURRENT_STATE_CV_DISCHARGE" 7 "CURRENT_STATE_DISCHARGED" 8 "CURRENT_STATE_OVER_DISCHARGED" 9 "CURRENT_STATE_OVER_DISCHARGE_RECOVERY" 10 "CURRENT_STATE_DEEPLY_DISCHARGED" ;
VAL_ 1311 Fully_charged_flag 0 "IDLE" 1 "ACTIVE" ;
